VERSION "HNNBNNNYNNNNNNNNNNNNNNNNNNNNNNNNNNNNNNNNNN/4/%%%/4/'%**4NNN///"

NS_ :

BS_:

BU_: BAP_Tester BedienDisp_vo BedienSG_hi CGS DDA Gateway Gateway_PAG GurtMikrofon OTA_FC ZR_High ZR_LIMU ZR_MIB_TOP_ab_Gen3 ZR_Standard

BO_ 795 ESP_24: 8 Gateway
 SG_ ESP_24_CRC : 0|8@1+ (1,0) [0|255] ""  Vector__XXX
 SG_ ESP_24_BZ : 8|4@1+ (1,0) [0|15] ""  Vector__XXX
 SG_ ESP_Lampe : 12|1@1+ (1.0,0.0) [0.0|1] ""  OTA_FC,ZR_High,ZR_LIMU,ZR_MIB_TOP_ab_Gen3
 SG_ ABS_Lampe : 13|1@1+ (1.0,0.0) [0.0|1] ""  OTA_FC,ZR_High
 SG_ BK_Lampe_02 : 14|2@1+ (1.0,0.0) [0.0|3] ""  OTA_FC
 SG_ TC_Lampe : 16|1@1+ (1.0,0.0) [0.0|1] ""  Vector__XXX
 SG_ ESP_m_Raddrehz : 17|15@1+ (0.002,0) [0.000|65.278] "Unit_Hertz"  Vector__XXX
 SG_ ESP_Textanzeigen_03 : 32|5@1+ (1.0,0.0) [0.0|31] ""  OTA_FC
 SG_ ESP_Meldungen : 37|3@1+ (1.0,0.0) [0.0|7] ""  Vector__XXX
 SG_ ESP_Wegimp_VA : 40|11@1+ (1,0) [0|2047] ""  ZR_High,ZR_LIMU,ZR_MIB_TOP_ab_Gen3,ZR_Standard
 SG_ ESP_Fehlerstatus_Wegimp : 51|1@1+ (1.0,0.0) [0.0|1] ""  ZR_High,ZR_LIMU,ZR_MIB_TOP_ab_Gen3,ZR_Standard
 SG_ ESP_Wegimp_Ueberlauf : 52|1@1+ (1.0,0.0) [0.0|1] ""  ZR_High,ZR_LIMU,ZR_MIB_TOP_ab_Gen3,ZR_Standard
 SG_ ESP_QBit_Wegimp_VA : 53|1@1+ (1.0,0.0) [0.0|1] ""  ZR_High,ZR_LIMU,ZR_MIB_TOP_ab_Gen3,ZR_Standard
 SG_ ESP_HDC_Geschw_Farbe : 54|1@1+ (1.0,0.0) [0.0|1] ""  ZR_High,ZR_LIMU,ZR_MIB_TOP_ab_Gen3
 SG_ ESP_Off_Lampe : 55|1@1+ (1.0,0.0) [0.0|1] ""  OTA_FC,ZR_High
 SG_ ESP_HDC_Regelgeschw : 56|7@1+ (0.32,0) [0.32|39.68] "Unit_KiloMeterPerHour"  ZR_High,ZR_LIMU,ZR_MIB_TOP_ab_Gen3,ZR_Standard
 SG_ ESP_BKV_Warnung : 63|1@1+ (1.0,0.0) [0.0|1] ""  OTA_FC

BO_ 508 ESP_32: 8 Gateway
 SG_ ESP_32_CRC : 0|8@1+ (1,0) [0|255] ""  Vector__XXX
 SG_ ESP_32_BZ : 8|4@1+ (1,0) [0|15] ""  Vector__XXX
 SG_ ESP_Status_Bremsentemp_02 : 12|2@1+ (1.0,0.0) [0.0|3] ""  ZR_LIMU,ZR_MIB_TOP_ab_Gen3
 SG_ ESP_Aggregataktivitaet : 14|1@1+ (1.0,0.0) [0.0|1] ""  Vector__XXX
 SG_ ESP_Stillstandsflag : 15|1@1+ (1.0,0.0) [0.0|1] ""  Vector__XXX
 SG_ ESC_MBK_Meldungen : 16|2@1+ (1.0,0.0) [0.0|3] ""  Vector__XXX
 SG_ ESP_EDS_Anzeige : 32|3@1+ (1.0,0.0) [0.0|7] ""  ZR_High,ZR_LIMU,ZR_MIB_TOP_ab_Gen3
 SG_ RLE_Anzeigen : 35|3@1+ (1.0,0.0) [0.0|7] ""  Vector__XXX
 SG_ ESP_Wiederstart_Anz_Std : 38|1@1+ (1.0,0.0) [0.0|1] ""  Vector__XXX
 SG_ ESC_Anforderung_Airbrake : 39|1@1+ (1.0,0.0) [0.0|1] ""  Vector__XXX
 SG_ ESC_FBA_Meldungen : 40|2@1+ (1.0,0.0) [0.0|3] ""  Vector__XXX
 SG_ ESP_Rollover_Status_dyn : 42|2@1+ (1.0,0.0) [0.0|3] ""  Vector__XXX
 SG_ ESP_Rollover_Status_stat : 44|2@1+ (1.0,0.0) [0.0|3] ""  Vector__XXX
 SG_ ESP_AVH_LED : 46|3@1+ (1.0,0.0) [0.0|7] ""  Vector__XXX
 SG_ ESP_HDC_LED : 49|3@1+ (1.0,0.0) [0.0|7] ""  Vector__XXX
 SG_ ESP_Off_LED : 52|3@1+ (1.0,0.0) [0.0|7] ""  Vector__XXX
 SG_ ESP_Notbremsanzeige : 55|1@1+ (1.0,0.0) [0.0|1] ""  Vector__XXX
 SG_ ESC_Motorstartverzoegerung : 56|1@1+ (1.0,0.0) [0.0|1] ""  Vector__XXX
 SG_ ESP_Offroad_Lampe : 57|1@1+ (1.0,0.0) [0.0|1] ""  Vector__XXX
 SG_ ESP_HDC_Textanzeigen : 58|5@1+ (1.0,0.0) [0.0|31] ""  Vector__XXX
 SG_ ESP_HOLD_verf : 63|1@1+ (1.0,0.0) [0.0|1] ""  OTA_FC

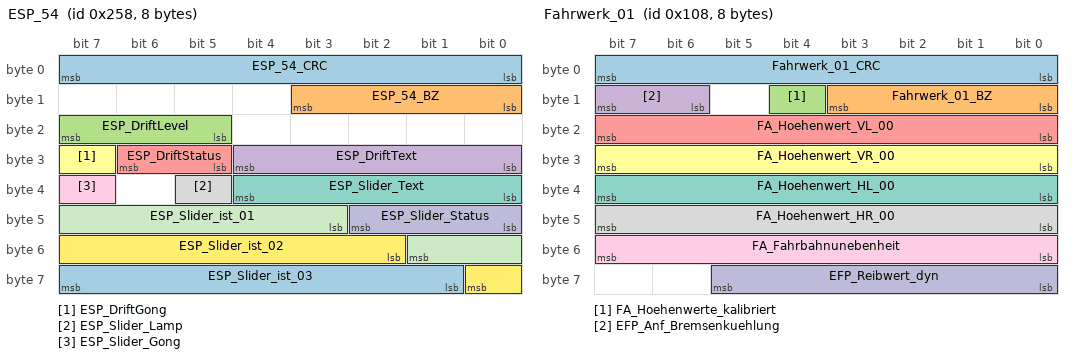
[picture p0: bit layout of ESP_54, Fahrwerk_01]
BO_ 600 ESP_54: 8 Gateway
 SG_ ESP_54_CRC : 0|8@1+ (1,0) [0|255] ""  ZR_LIMU
 SG_ ESP_54_BZ : 8|4@1+ (1,0) [0|15] ""  ZR_LIMU
 SG_ ESP_DriftLevel : 21|3@1+ (1.0,0.0) [0.0|7] ""  Vector__XXX
 SG_ ESP_DriftText : 24|5@1+ (1.0,0.0) [0.0|31] ""  Vector__XXX
 SG_ ESP_DriftStatus : 29|2@1+ (1.0,0.0) [0.0|3] ""  Vector__XXX
 SG_ ESP_DriftGong : 31|1@1+ (1.0,0.0) [0.0|1] ""  Vector__XXX
 SG_ ESP_Slider_Text : 32|5@1+ (1.0,0.0) [0.0|31] ""  ZR_LIMU
 SG_ ESP_Slider_Lamp : 37|1@1+ (1.0,0.0) [0.0|1] ""  Vector__XXX
 SG_ ESP_Slider_Gong : 39|1@1+ (1.0,0.0) [0.0|1] ""  Vector__XXX
 SG_ ESP_Slider_Status : 40|3@1+ (1.0,0.0) [0.0|7] ""  ZR_LIMU
 SG_ ESP_Slider_ist_01 : 43|7@1+ (1,0) [0|126] ""  ZR_LIMU
 SG_ ESP_Slider_ist_02 : 50|7@1+ (1,0) [0|126] ""  ZR_LIMU
 SG_ ESP_Slider_ist_03 : 57|7@1+ (1,0) [0|126] ""  ZR_LIMU

BO_ 264 Fahrwerk_01: 8 Gateway
 SG_ Fahrwerk_01_CRC : 0|8@1+ (1,0) [0|255] ""  Vector__XXX
 SG_ Fahrwerk_01_BZ : 8|4@1+ (1,0) [0|15] ""  Vector__XXX
 SG_ FA_Hoehenwerte_kalibriert : 12|1@1+ (1.0,0.0) [0.0|1] ""  ZR_High
 SG_ EFP_Anf_Bremsenkuehlung : 14|2@1+ (1.0,0.0) [0.0|3] ""  Vector__XXX
 SG_ FA_Hoehenwert_VL_00 : 16|8@1+ (1,-127) [-127|126] "Unit_MilliMeter"  DDA,OTA_FC,ZR_High,ZR_MIB_TOP_ab_Gen3
 SG_ FA_Hoehenwert_VR_00 : 24|8@1+ (1,-127) [-127|126] "Unit_MilliMeter"  DDA,OTA_FC,ZR_High,ZR_MIB_TOP_ab_Gen3
 SG_ FA_Hoehenwert_HL_00 : 32|8@1+ (1,-127) [-127|126] "Unit_MilliMeter"  DDA,OTA_FC,ZR_High,ZR_MIB_TOP_ab_Gen3
 SG_ FA_Hoehenwert_HR_00 : 40|8@1+ (1,-127) [-127|126] "Unit_MilliMeter"  DDA,OTA_FC,ZR_High,ZR_MIB_TOP_ab_Gen3
 SG_ FA_Fahrbahnunebenheit : 48|8@1+ (1,0) [0|253] ""  OTA_FC,ZR_High
 SG_ EFP_Reibwert_dyn : 56|6@1+ (0.03,0) [0.00|1.50] "Unit_None"  Vector__XXX

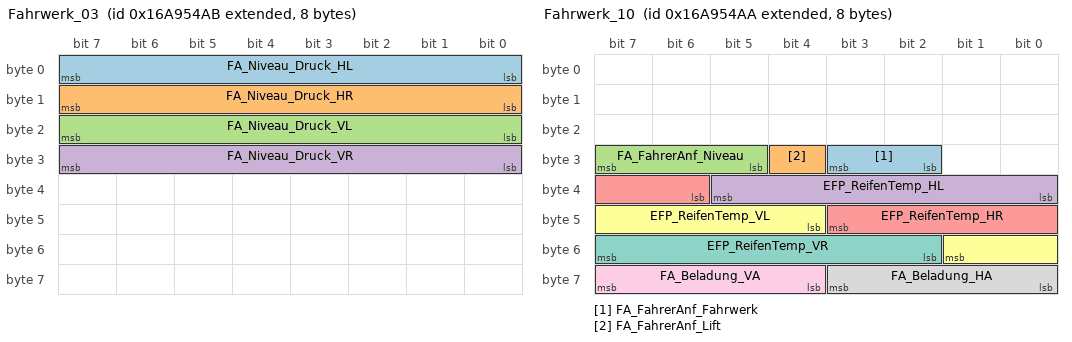
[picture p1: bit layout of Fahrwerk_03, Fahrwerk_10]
BO_ 2527679659 Fahrwerk_03: 8 Gateway
 SG_ FA_Niveau_Druck_HL : 0|8@1+ (0.1,0) [0.0|25.3] "Unit_Bar"  ZR_High
 SG_ FA_Niveau_Druck_HR : 8|8@1+ (0.1,0) [0.0|25.3] "Unit_Bar"  ZR_High
 SG_ FA_Niveau_Druck_VL : 16|8@1+ (0.1,0) [0.0|25.3] "Unit_Bar"  ZR_High
 SG_ FA_Niveau_Druck_VR : 24|8@1+ (0.1,0) [0.0|25.3] "Unit_Bar"  ZR_High

BO_ 429 Fahrwerk_06: 8 Gateway
 SG_ Fahrwerk_06_CRC : 0|8@1+ (1,0) [0|255] ""  Vector__XXX
 SG_ Fahrwerk_06_BZ : 8|4@1+ (1,0) [0|15] ""  Vector__XXX
 SG_ NR_Reglerstatus : 12|4@1+ (1.0,0.0) [0.0|15] ""  OTA_FC,ZR_High
 SG_ FA_Verstellung_in_Kuerze : 16|1@1+ (1.0,0.0) [0.0|1] ""  ZR_High
 SG_ FA_Verstellung_aktiv : 17|1@1+ (1.0,0.0) [0.0|1] ""  ZR_High
 SG_ FA_Kompressor_laeuft_in_Kuerze : 18|1@1+ (1.0,0.0) [0.0|1] ""  Vector__XXX
 SG_ FA_Kompressor_laeuft : 19|1@1+ (1.0,0.0) [0.0|1] ""  Vector__XXX
 SG_ NR_Anforderung_v_Begrenzung : 20|2@1+ (1.0,0.0) [0.0|3] ""  Vector__XXX
 SG_ NR_LED_SGN : 22|1@1+ (1.0,0.0) [0.0|1] ""  ZR_High
 SG_ NR_LED_TN : 23|1@1+ (1.0,0.0) [0.0|1] ""  ZR_High
 SG_ NR_LED_BN : 24|1@1+ (1.0,0.0) [0.0|1] ""  ZR_High
 SG_ FA_Absenkung_Fahrzeug : 25|1@1+ (1.0,0.0) [0.0|1] ""  OTA_FC,ZR_High
 SG_ FA_Anhaengerstatus_intern : 26|3@1+ (1.0,0.0) [0.0|7] ""  ZR_High
 SG_ FA_Anhebung_Fahrzeug : 29|1@1+ (1.0,0.0) [0.0|1] ""  OTA_FC,ZR_High
 SG_ FA_Druckspeicher_verfuegbar : 30|1@1+ (1.0,0.0) [0.0|1] ""  OTA_FC
 SG_ FA_HAL_Abschaltung : 31|1@1+ (1.0,0.0) [0.0|1] ""  Vector__XXX
 SG_ FA_ESP_Zuschaltung : 32|1@1+ (1.0,0.0) [0.0|1] ""  Vector__XXX
 SG_ NR_LED_HN : 33|1@1+ (1.0,0.0) [0.0|1] ""  ZR_High
 SG_ FA_Zwischenniveau : 34|1@1+ (1.0,0.0) [0.0|1] ""  OTA_FC
 SG_ FA_Systemstatus : 35|1@1+ (1.0,0.0) [0.0|1] ""  ZR_High
 SG_ EFP_Soll_FahrPr_HAL : 36|4@1+ (1.0,0.0) [0.0|15] ""  Vector__XXX
 SG_ NR_Kompressor_Strom_02 : 40|8@1+ (0.2,0) [0.0|50.8] "Unit_Amper"  Vector__XXX
 SG_ NR_Kompressor_Temp_Zylinderkopf : 48|8@1+ (1,-40) [-40|213] "Unit_DegreCelsi"  OTA_FC
 SG_ FA_Signal_Drucksensor : 56|8@1+ (0.1,0) [0.0|25.3] "Unit_Bar"  OTA_FC

BO_ 2527679658 Fahrwerk_10: 8 Gateway
 SG_ FA_FahrerAnf_Fahrwerk : 26|2@1+ (1.0,0.0) [0.0|3] ""  OTA_FC,ZR_MIB_TOP_ab_Gen3
 SG_ FA_FahrerAnf_Lift : 28|1@1+ (1.0,0.0) [0.0|1] ""  OTA_FC,ZR_MIB_TOP_ab_Gen3
 SG_ FA_FahrerAnf_Niveau : 29|3@1+ (1.0,0.0) [0.0|7] ""  OTA_FC,ZR_MIB_TOP_ab_Gen3
 SG_ EFP_ReifenTemp_HL : 32|6@1+ (2,-25) [-25|99] "Unit_DegreCelsi"  OTA_FC
 SG_ EFP_ReifenTemp_HR : 38|6@1+ (2,-25) [-25|99] "Unit_DegreCelsi"  OTA_FC
 SG_ EFP_ReifenTemp_VL : 44|6@1+ (2,-25) [-25|99] "Unit_DegreCelsi"  OTA_FC
 SG_ EFP_ReifenTemp_VR : 50|6@1+ (2,-25) [-25|99] "Unit_DegreCelsi"  OTA_FC
 SG_ FA_Beladung_HA : 56|4@1+ (50,0) [0|650] "Unit_KiloGram"  ZR_High
 SG_ FA_Beladung_VA : 60|4@1+ (50,0) [0|650] "Unit_KiloGram"  ZR_High

BO_ 2527679896 Fahrwerk_12: 8 Gateway_PAG
 SG_ Fahrwerk_12_CRC : 0|8@1+ (1,0) [0|255] ""  Vector__XXX
 SG_ Fahrwerk_12_BZ : 8|4@1+ (1,0) [0|15] ""  Vector__XXX
 SG_ EFP_ReifenTempOf_VL : 12|6@1+ (2,-25) [-25|99] "Unit_DegreCelsi"  Vector__XXX
 SG_ EFP_ReifenTempOf_VR : 18|6@1+ (2,-25) [-25|99] "Unit_DegreCelsi"  Vector__XXX
 SG_ EFP_ReifenTempOf_HL : 24|6@1+ (2,-25) [-25|99] "Unit_DegreCelsi"  Vector__XXX
 SG_ EFP_ReifenTempOf_HR : 30|6@1+ (2,-25) [-25|99] "Unit_DegreCelsi"  Vector__XXX
 SG_ FA_FahrerAnf_Lift_Abwurf : 39|1@1+ (1.0,0.0) [0.0|1] ""  ZR_MIB_TOP_ab_Gen3
 SG_ FA_Niveau_AOCCT_timer2_verbaut : 40|1@1+ (1.0,0.0) [0.0|1] ""  Vector__XXX
 SG_ FA_Niveau_AOCCT_timer2_count : 41|1@1+ (1.0,0.0) [0.0|1] ""  Vector__XXX
 SG_ FA_Niveau_AOCCT_timer1_verbaut : 42|1@1+ (1.0,0.0) [0.0|1] ""  Vector__XXX
 SG_ FA_Niveau_AOCCT_timer1_count : 43|1@1+ (1.0,0.0) [0.0|1] ""  Vector__XXX
 SG_ FA_Niveau_AOCCT_teststatus : 44|1@1+ (1.0,0.0) [0.0|1] ""  Vector__XXX
 SG_ FA_Niveau_AOCCT_fehlerstatus : 45|1@1+ (1.0,0.0) [0.0|1] ""  Vector__XXX
 SG_ FA_Zuladung_VA : 46|6@1+ (20,0) [0|1200] "Unit_KiloGram"  Vector__XXX
 SG_ FA_Zuladung_HA : 52|6@1+ (20,0) [0|1200] "Unit_KiloGram"  Vector__XXX
 SG_ FA_Zuladung_Status_VA : 58|3@1+ (1.0,0.0) [0.0|7] ""  Vector__XXX
 SG_ FA_Zuladung_Status_HA : 61|3@1+ (1.0,0.0) [0.0|7] ""  Vector__XXX

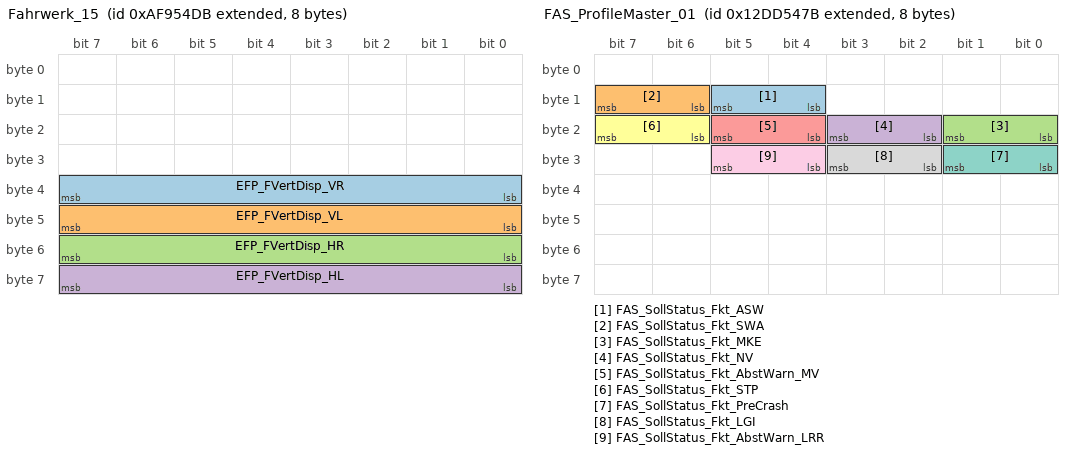
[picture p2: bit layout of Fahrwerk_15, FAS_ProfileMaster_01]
BO_ 2331595995 Fahrwerk_15: 8 Gateway
 SG_ EFP_FVertDisp_VR : 32|8@1+ (100,0) [0|24000] "Unit_Newto"  ZR_MIB_TOP_ab_Gen3
 SG_ EFP_FVertDisp_VL : 40|8@1+ (100,0) [0|24000] "Unit_Newto"  ZR_MIB_TOP_ab_Gen3
 SG_ EFP_FVertDisp_HR : 48|8@1+ (100,0) [0|24000] "Unit_Newto"  ZR_MIB_TOP_ab_Gen3
 SG_ EFP_FVertDisp_HL : 56|8@1+ (100,0) [0|24000] "Unit_Newto"  ZR_MIB_TOP_ab_Gen3

BO_ 705 Fahrwerk_Anzeige_01: 8 Gateway
 SG_ Fahrwerk_Anzeige_01_CRC : 0|8@1+ (1,0) [0|255] ""  Vector__XXX
 SG_ Fahrwerk_Anzeige_01_BZ : 8|4@1+ (1,0) [0|15] ""  Vector__XXX
 SG_ EFP_Verbau_DR : 12|1@1+ (1.0,0.0) [0.0|1] ""  Vector__XXX
 SG_ EFP_Verbau_eAllrad : 13|1@1+ (1.0,0.0) [0.0|1] ""  Vector__XXX
 SG_ EFP_Verbau_LF : 14|1@1+ (1.0,0.0) [0.0|1] ""  Vector__XXX
 SG_ LF_Texte : 15|2@1+ (1.0,0.0) [0.0|3] ""  Vector__XXX
 SG_ EFP_Verbau_eAWS : 17|1@1+ (1.0,0.0) [0.0|1] ""  Vector__XXX
 SG_ eAWS_Warnmeldung_Prio1 : 18|1@1+ (1.0,0.0) [0.0|1] ""  Vector__XXX
 SG_ eAWS_Warnmeldung_Prio2 : 19|1@1+ (1.0,0.0) [0.0|1] ""  Vector__XXX
 SG_ LF_Texte_2 : 20|4@1+ (1.0,0.0) [0.0|15] ""  Vector__XXX
 SG_ EFP_Status_Taster_Lift : 24|2@1+ (1.0,0.0) [0.0|3] ""  Vector__XXX
 SG_ EFP_Status_Taster_Fahrwerk : 26|2@1+ (1.0,0.0) [0.0|3] ""  BedienDisp_vo
 SG_ FDR_Warnung_ALR : 28|2@1+ (1.0,0.0) [0.0|3] ""  Vector__XXX
 SG_ FDR_Warnung_TV : 30|2@1+ (1.0,0.0) [0.0|3] ""  Vector__XXX
 SG_ EFP_Verbau_eABC : 32|1@1+ (1.0,0.0) [0.0|1] ""  Vector__XXX
 SG_ LF_Warnung_Prio1_02 : 33|3@1+ (1.0,0.0) [0.0|7] ""  Vector__XXX
 SG_ LF_Warnung_Prio1 : 36|2@1+ (1.0,0.0) [0.0|3] ""  Vector__XXX
 SG_ LF_Warnung_Prio2 : 38|2@1+ (1.0,0.0) [0.0|3] ""  Vector__XXX
 SG_ eABC_Warnung_Prio2 : 40|2@1+ (1.0,0.0) [0.0|3] ""  Vector__XXX
 SG_ eABC_Warnung_Prio1 : 42|3@1+ (1.0,0.0) [0.0|7] ""  Vector__XXX
 SG_ eABC_Texte : 45|3@1+ (1.0,0.0) [0.0|7] ""  Vector__XXX
 SG_ DR_Warnung : 48|2@1+ (1.0,0.0) [0.0|3] ""  Vector__XXX
 SG_ NR_LED_Offroadlevel : 50|2@1+ (1.0,0.0) [0.0|3] ""  Vector__XXX
 SG_ NR_LED_Ladelevel : 52|2@1+ (1.0,0.0) [0.0|3] ""  Vector__XXX
 SG_ NR_LED_Sync : 54|2@1+ (1.0,0.0) [0.0|3] ""  Vector__XXX
 SG_ NR_LED_XtraLevel : 56|2@1+ (1.0,0.0) [0.0|3] ""  Vector__XXX
 SG_ NR_LED_Strassenlevel : 58|2@1+ (1.0,0.0) [0.0|3] ""  Vector__XXX
 SG_ EFP_Warnung_Naesse : 60|3@1+ (1.0,0.0) [0.0|7] ""  Vector__XXX
 SG_ EFP_Warnung_Naesse_verf : 63|1@1+ (1.0,0.0) [0.0|1] ""  Vector__XXX

BO_ 2463978619 FAS_ProfileMaster_01: 8 Gateway
 SG_ FAS_SollStatus_Fkt_ASW : 12|2@1+ (1.0,0.0) [0.0|3] ""  ZR_High
 SG_ FAS_SollStatus_Fkt_SWA : 14|2@1+ (1.0,0.0) [0.0|3] ""  ZR_High
 SG_ FAS_SollStatus_Fkt_MKE : 16|2@1+ (1.0,0.0) [0.0|3] ""  ZR_High
 SG_ FAS_SollStatus_Fkt_NV : 18|2@1+ (1.0,0.0) [0.0|3] ""  ZR_High
 SG_ FAS_SollStatus_Fkt_AbstWarn_MV : 20|2@1+ (1.0,0.0) [0.0|3] ""  ZR_High
 SG_ FAS_SollStatus_Fkt_STP : 22|2@1+ (1.0,0.0) [0.0|3] ""  ZR_High
 SG_ FAS_SollStatus_Fkt_PreCrash : 24|2@1+ (1.0,0.0) [0.0|3] ""  ZR_High
 SG_ FAS_SollStatus_Fkt_LGI : 26|2@1+ (1.0,0.0) [0.0|3] ""  ZR_High
 SG_ FAS_SollStatus_Fkt_AbstWarn_LRR : 28|2@1+ (1.0,0.0) [0.0|3] ""  Vector__XXX

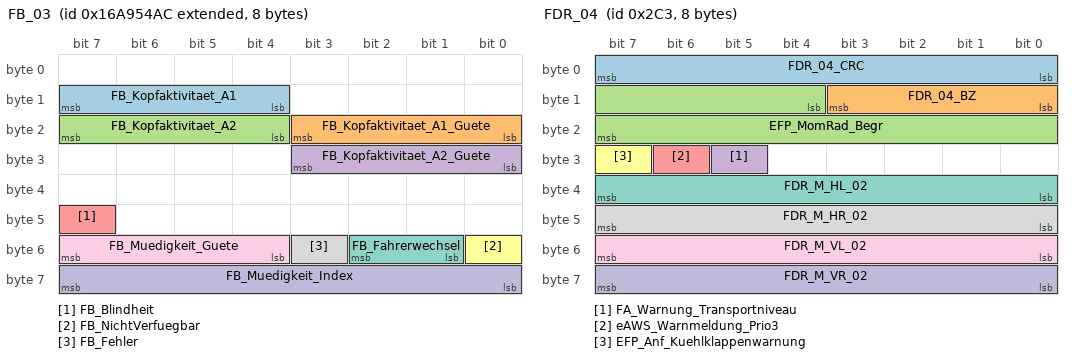
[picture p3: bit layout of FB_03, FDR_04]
BO_ 2527679660 FB_03: 8 Gateway
 SG_ FB_Kopfaktivitaet_A1 : 12|4@1+ (7.143,0) [0.000|100.002] "Unit_None"  Vector__XXX
 SG_ FB_Kopfaktivitaet_A1_Guete : 16|4@1+ (6.667,0) [0.000|100.005] "Unit_PerCent"  Vector__XXX
 SG_ FB_Kopfaktivitaet_A2 : 20|4@1+ (7.143,0) [0.000|100.002] "Unit_None"  Vector__XXX
 SG_ FB_Kopfaktivitaet_A2_Guete : 24|4@1+ (6.667,0) [0.000|100.005] "Unit_PerCent"  Vector__XXX
 SG_ FB_Blindheit : 47|1@1+ (1.0,0.0) [0.0|1] ""  Vector__XXX
 SG_ FB_NichtVerfuegbar : 48|1@1+ (1.0,0.0) [0.0|1] ""  Vector__XXX
 SG_ FB_Fahrerwechsel : 49|2@1+ (1.0,0.0) [0.0|3] ""  ZR_High
 SG_ FB_Fehler : 51|1@1+ (1.0,0.0) [0.0|1] ""  ZR_High
 SG_ FB_Muedigkeit_Guete : 52|4@1+ (6.667,0) [0.000|100.005] "Unit_PerCent"  ZR_High
 SG_ FB_Muedigkeit_Index : 56|8@1+ (0.05,0) [0.00|9.00] "Unit_None"  ZR_High

BO_ 707 FDR_04: 8 Gateway
 SG_ FDR_04_CRC : 0|8@1+ (1,0) [0|255] ""  Vector__XXX
 SG_ FDR_04_BZ : 8|4@1+ (1,0) [0|15] ""  Vector__XXX
 SG_ EFP_MomRad_Begr : 12|12@1+ (3,0) [0|12279] "Unit_NewtoMeter"  Vector__XXX
 SG_ FA_Warnung_Transportniveau : 29|1@1+ (1.0,0.0) [0.0|1] ""  Vector__XXX
 SG_ eAWS_Warnmeldung_Prio3 : 30|1@1+ (1.0,0.0) [0.0|1] ""  Vector__XXX
 SG_ EFP_Anf_Kuehlklappenwarnung : 31|1@1+ (1.0,0.0) [0.0|1] ""  Vector__XXX
 SG_ FDR_M_HL_02 : 32|8@1+ (1,-100) [-100|100] "Unit_PerCent"  ZR_High,ZR_LIMU,ZR_MIB_TOP_ab_Gen3,ZR_Standard
 SG_ FDR_M_HR_02 : 40|8@1+ (1,-100) [-100|100] "Unit_PerCent"  ZR_High,ZR_LIMU,ZR_MIB_TOP_ab_Gen3,ZR_Standard
 SG_ FDR_M_VL_02 : 48|8@1+ (1,-100) [-100|100] "Unit_PerCent"  ZR_High,ZR_LIMU,ZR_MIB_TOP_ab_Gen3,ZR_Standard
 SG_ FDR_M_VR_02 : 56|8@1+ (1,-100) [-100|100] "Unit_PerCent"  ZR_High,ZR_LIMU,ZR_MIB_TOP_ab_Gen3,ZR_Standard

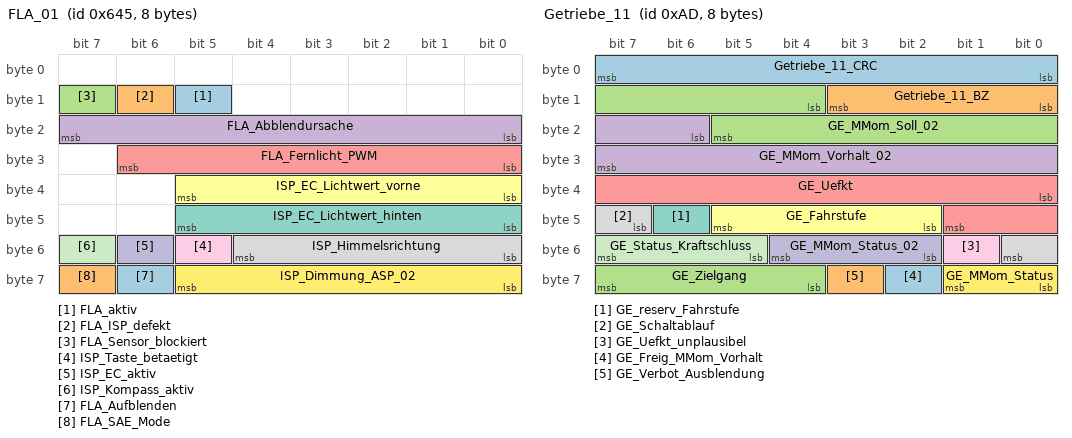
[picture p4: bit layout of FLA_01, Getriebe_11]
BO_ 1605 FLA_01: 8 Gateway
 SG_ FLA_aktiv : 13|1@1+ (1.0,0.0) [0.0|1] ""  Vector__XXX
 SG_ FLA_ISP_defekt : 14|1@1+ (1.0,0.0) [0.0|1] ""  ZR_High
 SG_ FLA_Sensor_blockiert : 15|1@1+ (1.0,0.0) [0.0|1] ""  ZR_High
 SG_ FLA_Abblendursache : 16|8@1+ (1.0,0.0) [0.0|255] ""  ZR_High
 SG_ FLA_Fernlicht_PWM : 24|7@1+ (1,0) [0|100] "Unit_PerCent"  Vector__XXX
 SG_ ISP_EC_Lichtwert_vorne : 32|6@1+ (1,0) [0|61] "Unit_None"  Vector__XXX
 SG_ ISP_EC_Lichtwert_hinten : 40|6@1+ (1,0) [0|61] "Unit_None"  Vector__XXX
 SG_ ISP_Himmelsrichtung : 48|5@1+ (12,0) [0|348] "Unit_DegreOfArc"  Vector__XXX
 SG_ ISP_Taste_betaetigt : 53|1@1+ (1.0,0.0) [0.0|1] ""  Vector__XXX
 SG_ ISP_EC_aktiv : 54|1@1+ (1.0,0.0) [0.0|1] ""  Vector__XXX
 SG_ ISP_Kompass_aktiv : 55|1@1+ (1.0,0.0) [0.0|1] ""  Vector__XXX
 SG_ ISP_Dimmung_ASP_02 : 56|6@1+ (0.0226,0) [0.0000|1.4012] "Unit_Volt"  Vector__XXX
 SG_ FLA_Aufblenden : 62|1@1+ (1.0,0.0) [0.0|1] ""  Vector__XXX
 SG_ FLA_SAE_Mode : 63|1@1+ (1.0,0.0) [0.0|1] ""  Vector__XXX

BO_ 2589283684 FoD_01: 8 Gateway
 SG_ FoD_Transmission_Info : 60|2@1+ (1.0,0.0) [0.0|3] ""  ZR_High,ZR_LIMU,ZR_MIB_TOP_ab_Gen3
 SG_ FoD_Anz_Funktionsabschaltung : 62|2@1+ (1.0,0.0) [0.0|3] ""  Vector__XXX

BO_ 2549875571 FoD_ZR_Req: 8 Gateway
 SG_ FoD_ZR_Req_Data : 0|64@1+ (1.0,0.0) [0.0|18446744073709551615] ""  ZR_High,ZR_LIMU,ZR_MIB_TOP_ab_Gen3

BO_ 2550006643 FoD_ZR_Resp: 8 ZR_High
 SG_ FoD_ZR_Resp_Data : 0|64@1+ (1.0,0.0) [0.0|18446744073709551615] ""  Gateway,Gateway_PAG

BO_ 173 Getriebe_11: 8 Gateway
 SG_ Getriebe_11_CRC : 0|8@1+ (1,0) [0|255] ""  Vector__XXX
 SG_ Getriebe_11_BZ : 8|4@1+ (1,0) [0|15] ""  Vector__XXX
 SG_ GE_MMom_Soll_02 : 12|10@1+ (1,-509) [-509|509] ""  Vector__XXX
 SG_ GE_MMom_Vorhalt_02 : 22|10@1+ (1,-509) [-509|509] ""  Vector__XXX
 SG_ GE_Uefkt : 32|10@1+ (0.1,0) [0.0|102.2] ""  Vector__XXX
 SG_ GE_Fahrstufe : 42|4@1+ (1.0,0.0) [0.0|15] ""  DDA,OTA_FC,ZR_High,ZR_LIMU,ZR_MIB_TOP_ab_Gen3
 SG_ GE_reserv_Fahrstufe : 46|1@1+ (1,0) [0|1] ""  Vector__XXX
 SG_ GE_Schaltablauf : 47|2@1+ (1.0,0.0) [0.0|3] ""  Vector__XXX
 SG_ GE_Uefkt_unplausibel : 49|1@1+ (1.0,0.0) [0.0|1] ""  Vector__XXX
 SG_ GE_MMom_Status_02 : 50|3@1+ (1.0,0.0) [0.0|7] ""  Vector__XXX
 SG_ GE_Status_Kraftschluss : 53|3@1+ (1.0,0.0) [0.0|7] ""  Vector__XXX
 SG_ GE_MMom_Status : 56|2@1+ (1.0,0.0) [0.0|3] ""  Vector__XXX
 SG_ GE_Freig_MMom_Vorhalt : 58|1@1+ (1.0,0.0) [0.0|1] ""  Vector__XXX
 SG_ GE_Verbot_Ausblendung : 59|1@1+ (1.0,0.0) [0.0|1] ""  Vector__XXX
 SG_ GE_Zielgang : 60|4@1+ (1.0,0.0) [0.0|15] ""  OTA_FC,ZR_High

BO_ 968 Getriebe_14: 8 Gateway
 SG_ GE_OBD_AbsperrVent : 12|4@1+ (1.0,0.0) [0.0|15] ""  Vector__XXX
 SG_ GE_amax_moeglich : 16|9@1+ (0.024,-2.016) [-2.016|10.224] "Unit_MeterPerSeconSquar"  Vector__XXX
 SG_ GE_Charisma_FahrPr : 25|4@1+ (1.0,0.0) [0.0|15] ""  Vector__XXX
 SG_ GE_Charisma_Status : 29|2@1+ (1.0,0.0) [0.0|3] ""  Vector__XXX
 SG_ GE_Freigabe_Verfallsinfo_WFS : 31|1@1+ (1.0,0.0) [0.0|1] ""  Vector__XXX
 SG_ GE_LaunchControl_LB : 32|4@1+ (1.0,0.0) [0.0|15] ""  Vector__XXX
 SG_ GE_Status_PaddleNeutral : 37|2@1+ (1.0,0.0) [0.0|3] ""  Vector__XXX
 SG_ GE_Remotestart_Betrieb : 39|1@1+ (1.0,0.0) [0.0|1] ""  Vector__XXX
 SG_ Freilauf_Charisma_FahrPr : 40|4@1+ (1.0,0.0) [0.0|15] ""  Vector__XXX
 SG_ Freilauf_Charisma_Status : 44|2@1+ (1.0,0.0) [0.0|3] ""  Vector__XXX
 SG_ GE_Freigabe_Info_WFS : 46|1@1+ (1.0,0.0) [0.0|1] ""  Vector__XXX
 SG_ GE_Sperr_Info_WFS : 47|1@1+ (1.0,0.0) [0.0|1] ""  Vector__XXX
 SG_ GE_Zustand_Kuppltemp : 48|2@1+ (1.0,0.0) [0.0|3] ""  Vector__XXX
 SG_ GE_Codierung_MSG : 50|1@1+ (1.0,0.0) [0.0|1] ""  Vector__XXX
 SG_ GE_LaunchControl : 51|1@1+ (1.0,0.0) [0.0|1] ""  OTA_FC
 SG_ GE_Heizwunsch : 52|2@1+ (1.0,0.0) [0.0|3] ""  Vector__XXX
 SG_ GE_OBD_Status : 54|1@1+ (1.0,0.0) [0.0|1] ""  Vector__XXX
 SG_ GE_LFR_Adaption : 55|1@1+ (1.0,0.0) [0.0|1] ""  Vector__XXX
 SG_ GE_Sumpftemperatur : 56|8@1+ (1,-58) [-58|196] "Unit_DegreCelsi"  OTA_FC,ZR_High,ZR_MIB_TOP_ab_Gen3,ZR_Standard

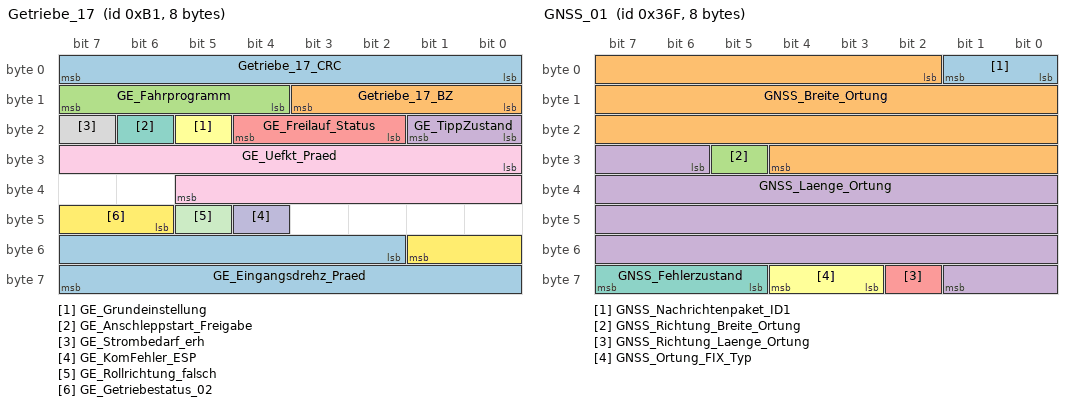
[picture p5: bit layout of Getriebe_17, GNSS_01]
BO_ 177 Getriebe_17: 8 Gateway
 SG_ Getriebe_17_CRC : 0|8@1+ (1,0) [0|255] ""  Vector__XXX
 SG_ Getriebe_17_BZ : 8|4@1+ (1,0) [0|15] ""  Vector__XXX
 SG_ GE_Fahrprogramm : 12|4@1+ (1.0,0.0) [0.0|15] ""  OTA_FC,ZR_High
 SG_ GE_TippZustand : 16|2@1+ (1.0,0.0) [0.0|3] ""  ZR_High
 SG_ GE_Freilauf_Status : 18|3@1+ (1.0,0.0) [0.0|7] ""  Vector__XXX
 SG_ GE_Grundeinstellung : 21|1@1+ (1.0,0.0) [0.0|1] ""  Vector__XXX
 SG_ GE_Anschleppstart_Freigabe : 22|1@1+ (1.0,0.0) [0.0|1] ""  Vector__XXX
 SG_ GE_Strombedarf_erh : 23|1@1+ (1.0,0.0) [0.0|1] ""  Vector__XXX
 SG_ GE_Uefkt_Praed : 24|14@1+ (0.008,0) [0.000|131.056] ""  Vector__XXX
 SG_ GE_KomFehler_ESP : 44|1@1+ (1.0,0.0) [0.0|1] ""  Vector__XXX
 SG_ GE_Rollrichtung_falsch : 45|1@1+ (1.0,0.0) [0.0|1] ""  Vector__XXX
 SG_ GE_Getriebestatus_02 : 46|4@1+ (1.0,0.0) [0.0|15] ""  OTA_FC
 SG_ GE_Eingangsdrehz_Praed : 50|14@1+ (1,0) [0|16381] "Unit_MinutInver"  Vector__XXX

BO_ 879 GNSS_01: 8 Gateway
 SG_ GNSS_Nachrichtenpaket_ID1 : 0|2@1+ (1,0) [0|3] "Unit_Bit"  ZR_High,ZR_LIMU,ZR_MIB_TOP_ab_Gen3,ZR_Standard
 SG_ GNSS_Breite_Ortung : 2|27@1+ (0.000001,0) [0.000000|90.000000] "Unit_DegreOfArc"  ZR_High,ZR_LIMU,ZR_MIB_TOP_ab_Gen3,ZR_Standard
 SG_ GNSS_Richtung_Breite_Ortung : 29|1@1+ (1.0,0.0) [0.0|1] ""  ZR_High,ZR_LIMU,ZR_MIB_TOP_ab_Gen3,ZR_Standard
 SG_ GNSS_Laenge_Ortung : 30|28@1+ (0.000001,0) [0.000000|180.000000] "Unit_DegreOfArc"  ZR_High,ZR_LIMU,ZR_MIB_TOP_ab_Gen3,ZR_Standard
 SG_ GNSS_Richtung_Laenge_Ortung : 58|1@1+ (1.0,0.0) [0.0|1] ""  ZR_High,ZR_LIMU,ZR_MIB_TOP_ab_Gen3,ZR_Standard
 SG_ GNSS_Ortung_FIX_Typ : 59|2@1+ (1.0,0.0) [0.0|3] ""  ZR_High,ZR_LIMU,ZR_MIB_TOP_ab_Gen3,ZR_Standard
 SG_ GNSS_Fehlerzustand : 61|3@1+ (1.0,0.0) [0.0|7] ""  ZR_High,ZR_LIMU,ZR_MIB_TOP_ab_Gen3,ZR_Standard

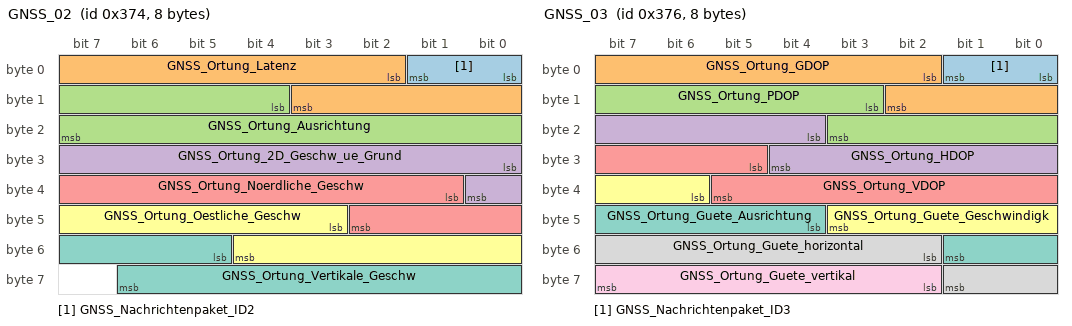
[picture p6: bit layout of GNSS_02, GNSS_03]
BO_ 884 GNSS_02: 8 Gateway
 SG_ GNSS_Nachrichtenpaket_ID2 : 0|2@1+ (1,0) [0|3] "Unit_Bit"  ZR_High,ZR_LIMU,ZR_MIB_TOP_ab_Gen3,ZR_Standard
 SG_ GNSS_Ortung_Latenz : 2|10@1+ (1,0) [0|1021] "Unit_MilliSecon"  ZR_High,ZR_LIMU,ZR_MIB_TOP_ab_Gen3,ZR_Standard
 SG_ GNSS_Ortung_Ausrichtung : 12|12@1+ (0.1,0) [0.0|359.9] "Unit_DegreOfArc"  ZR_High,ZR_LIMU,ZR_MIB_TOP_ab_Gen3,ZR_Standard
 SG_ GNSS_Ortung_2D_Geschw_ue_Grund : 24|9@1+ (0.25,0) [0.00|125.00] "Unit_MeterPerSecon"  ZR_High,ZR_LIMU,ZR_MIB_TOP_ab_Gen3,ZR_Standard
 SG_ GNSS_Ortung_Noerdliche_Geschw : 33|10@1+ (0.25,-125) [-125.00|125.00] "Unit_MeterPerSecon"  ZR_High,ZR_LIMU,ZR_MIB_TOP_ab_Gen3,ZR_Standard
 SG_ GNSS_Ortung_Oestliche_Geschw : 43|10@1+ (0.25,-125) [-125.00|125.00] "Unit_MeterPerSecon"  ZR_High,ZR_LIMU,ZR_MIB_TOP_ab_Gen3,ZR_Standard
 SG_ GNSS_Ortung_Vertikale_Geschw : 53|10@1+ (0.25,-125) [-125.00|125.00] "Unit_MeterPerSecon"  ZR_High,ZR_LIMU,ZR_MIB_TOP_ab_Gen3,ZR_Standard

BO_ 886 GNSS_03: 8 Gateway
 SG_ GNSS_Nachrichtenpaket_ID3 : 0|2@1+ (1,0) [0|3] "Unit_Bit"  ZR_High,ZR_LIMU,ZR_MIB_TOP_ab_Gen3,ZR_Standard
 SG_ GNSS_Ortung_GDOP : 2|9@1+ (0.1,0) [0.0|50.0] "Unit_None"  ZR_High,ZR_LIMU,ZR_MIB_TOP_ab_Gen3,ZR_Standard
 SG_ GNSS_Ortung_PDOP : 11|9@1+ (0.1,0) [0.0|50.0] "Unit_None"  ZR_High,ZR_LIMU,ZR_MIB_TOP_ab_Gen3,ZR_Standard
 SG_ GNSS_Ortung_HDOP : 20|9@1+ (0.1,0) [0.0|50.0] "Unit_None"  ZR_High,ZR_LIMU,ZR_MIB_TOP_ab_Gen3,ZR_Standard
 SG_ GNSS_Ortung_VDOP : 29|9@1+ (0.1,0) [0.0|50.0] "Unit_None"  ZR_High,ZR_LIMU,ZR_MIB_TOP_ab_Gen3,ZR_Standard
 SG_ GNSS_Ortung_Guete_Geschwindigk : 38|6@1+ (0.05,0) [0.00|3.05] "Unit_MeterPerSecon"  ZR_High,ZR_LIMU,ZR_MIB_TOP_ab_Gen3,ZR_Standard
 SG_ GNSS_Ortung_Guete_Ausrichtung : 44|6@1+ (0.15,0) [0.00|9.15] "Unit_DegreOfArc"  ZR_High,ZR_LIMU,ZR_MIB_TOP_ab_Gen3,ZR_Standard
 SG_ GNSS_Ortung_Guete_horizontal : 50|8@1+ (1,0) [0|250] "Unit_Meter"  ZR_High,ZR_LIMU,ZR_MIB_TOP_ab_Gen3,ZR_Standard
 SG_ GNSS_Ortung_Guete_vertikal : 58|6@1+ (2,0) [0|122] "Unit_Meter"  ZR_High,ZR_LIMU,ZR_MIB_TOP_ab_Gen3,ZR_Standard

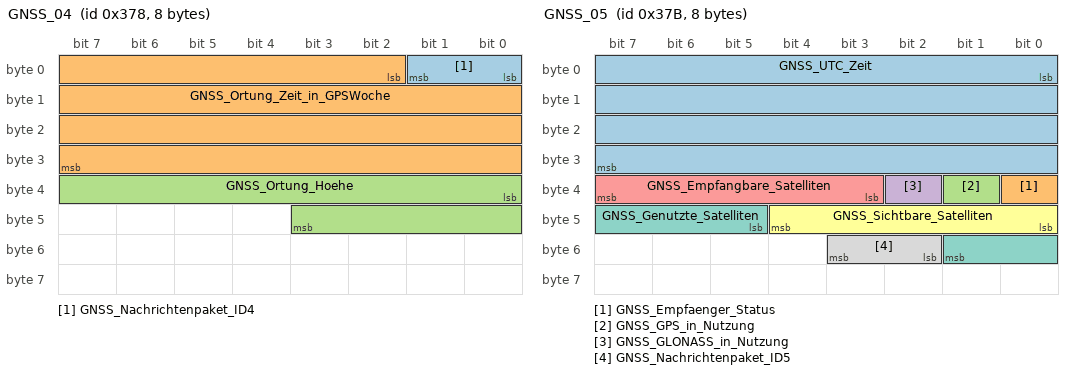
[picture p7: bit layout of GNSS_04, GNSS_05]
BO_ 888 GNSS_04: 8 Gateway
 SG_ GNSS_Nachrichtenpaket_ID4 : 0|2@1+ (1,0) [0|3] "Unit_Bit"  ZR_High,ZR_LIMU,ZR_MIB_TOP_ab_Gen3,ZR_Standard
 SG_ GNSS_Ortung_Zeit_in_GPSWoche : 2|30@1+ (1,0) [0|604800001] "Unit_MilliSecon"  ZR_High,ZR_LIMU,ZR_MIB_TOP_ab_Gen3,ZR_Standard
 SG_ GNSS_Ortung_Hoehe : 32|12@1+ (2,-500) [-500|7686] "Unit_Meter"  ZR_High,ZR_LIMU,ZR_MIB_TOP_ab_Gen3,ZR_Standard

BO_ 891 GNSS_05: 8 Gateway
 SG_ GNSS_UTC_Zeit : 0|32@1+ (1,0) [1|4294967295] "Unit_Secon"  OTA_FC,ZR_High,ZR_LIMU,ZR_MIB_TOP_ab_Gen3,ZR_Standard
 SG_ GNSS_Empfaenger_Status : 32|1@1+ (1.0,0.0) [0.0|1] ""  OTA_FC,ZR_High,ZR_LIMU,ZR_MIB_TOP_ab_Gen3,ZR_Standard
 SG_ GNSS_GPS_in_Nutzung : 33|1@1+ (1.0,0.0) [0.0|1] ""  ZR_High,ZR_LIMU,ZR_MIB_TOP_ab_Gen3,ZR_Standard
 SG_ GNSS_GLONASS_in_Nutzung : 34|1@1+ (1.0,0.0) [0.0|1] ""  ZR_High,ZR_LIMU,ZR_MIB_TOP_ab_Gen3,ZR_Standard
 SG_ GNSS_Empfangbare_Satelliten : 35|5@1+ (1,0) [1|30] "Unit_None"  ZR_High,ZR_LIMU,ZR_MIB_TOP_ab_Gen3,ZR_Standard
 SG_ GNSS_Sichtbare_Satelliten : 40|5@1+ (1,0) [1|30] "Unit_None"  ZR_High,ZR_LIMU,ZR_MIB_TOP_ab_Gen3,ZR_Standard
 SG_ GNSS_Genutzte_Satelliten : 45|5@1+ (1,0) [1|30] "Unit_None"  ZR_High,ZR_LIMU,ZR_MIB_TOP_ab_Gen3,ZR_Standard
 SG_ GNSS_Nachrichtenpaket_ID5 : 50|2@1+ (1,0) [0|3] "Unit_Bit"  ZR_High,ZR_LIMU,ZR_MIB_TOP_ab_Gen3,ZR_Standard

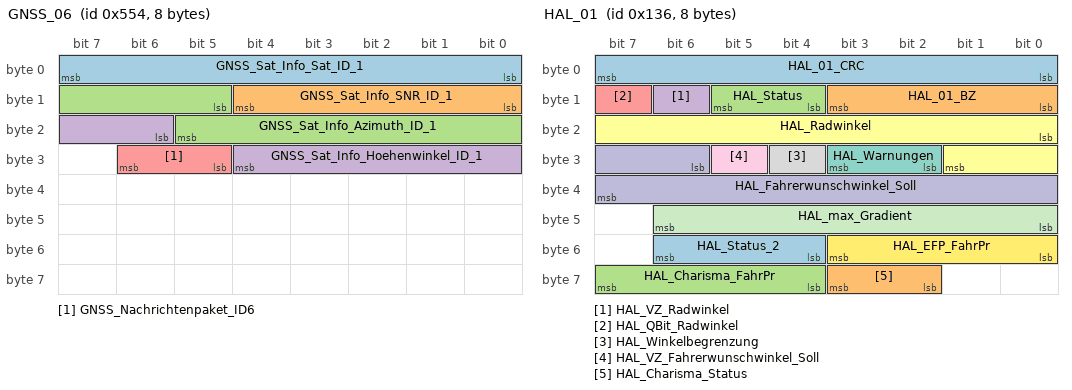
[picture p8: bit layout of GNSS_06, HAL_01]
BO_ 1364 GNSS_06: 8 Gateway
 SG_ GNSS_Sat_Info_Sat_ID_1 : 0|8@1+ (1,0) [0|255] ""  ZR_High,ZR_LIMU,ZR_MIB_TOP_ab_Gen3,ZR_Standard
 SG_ GNSS_Sat_Info_SNR_ID_1 : 8|5@1+ (2,0) [0|60] "Unit_DeziBel"  ZR_High,ZR_LIMU,ZR_MIB_TOP_ab_Gen3,ZR_Standard
 SG_ GNSS_Sat_Info_Azimuth_ID_1 : 13|9@1+ (1,0) [0|359] "Unit_DegreOfArc"  ZR_High,ZR_LIMU,ZR_MIB_TOP_ab_Gen3,ZR_Standard
 SG_ GNSS_Sat_Info_Hoehenwinkel_ID_1 : 22|7@1+ (1,0) [0|90] "Unit_DegreOfArc"  ZR_High,ZR_LIMU,ZR_MIB_TOP_ab_Gen3,ZR_Standard
 SG_ GNSS_Nachrichtenpaket_ID6 : 29|2@1+ (1,0) [0|3] "Unit_Bit"  ZR_High,ZR_LIMU,ZR_MIB_TOP_ab_Gen3,ZR_Standard

BO_ 299 GRA_ACC_01: 8 Gateway
 SG_ GRA_ACC_01_CRC : 0|8@1+ (1,0) [0|255] ""  Vector__XXX
 SG_ GRA_ACC_01_BZ : 8|4@1+ (1,0) [0|15] ""  Vector__XXX
 SG_ GRA_Hauptschalter : 12|1@1+ (1.0,0.0) [0.0|1] ""  ZR_High
 SG_ GRA_Abbrechen : 13|1@1+ (1.0,0.0) [0.0|1] ""  ZR_High
 SG_ GRA_Typ_Hauptschalter : 14|1@1+ (1.0,0.0) [0.0|1] ""  ZR_High
 SG_ GRA_Limiter : 15|1@1+ (1.0,0.0) [0.0|1] ""  ZR_High
 SG_ GRA_Tip_Setzen : 16|1@1+ (1.0,0.0) [0.0|1] ""  ZR_High
 SG_ GRA_Tip_Hoch : 17|1@1+ (1.0,0.0) [0.0|1] ""  ZR_High
 SG_ GRA_Tip_Runter : 18|1@1+ (1.0,0.0) [0.0|1] ""  ZR_High
 SG_ GRA_Tip_Wiederaufnahme : 19|1@1+ (1.0,0.0) [0.0|1] ""  ZR_High
 SG_ GRA_Verstellung_Zeitluecke : 20|2@1+ (1.0,0.0) [0.0|3] ""  ZR_High
 SG_ GRA_Codierung : 22|2@1+ (1.0,0.0) [0.0|3] ""  ZR_High
 SG_ GRA_Fehler : 24|1@1+ (1.0,0.0) [0.0|1] ""  ZR_High
 SG_ GRA_LIM_Taste_verfuegbar : 25|1@1+ (1.0,0.0) [0.0|1] ""  ZR_High
 SG_ GRA_Tip_Stufe_2 : 26|1@1+ (1.0,0.0) [0.0|1] ""  ZR_High
 SG_ GRA_Typ_Bedienteil : 27|3@1+ (1.0,0.0) [0.0|7] ""  ZR_High
 SG_ GRA_TravelAssist : 30|1@1+ (1.0,0.0) [0.0|1] ""  Vector__XXX
 SG_ GRA_reserveByte4 : 31|1@1+ (1.0,0.0) [0.0|1] ""  Vector__XXX
 SG_ GRA_reserveByte5 : 32|8@1+ (1.0,0.0) [0.0|255] ""  Vector__XXX
 SG_ GRA_reserveByte6 : 40|8@1+ (1.0,0.0) [0.0|255] ""  Vector__XXX
 SG_ GRA_reserveByte7 : 48|8@1+ (1.0,0.0) [0.0|255] ""  Vector__XXX
 SG_ GRA_reserveByte8 : 56|8@1+ (1.0,0.0) [0.0|255] ""  Vector__XXX

BO_ 310 HAL_01: 8 Gateway
 SG_ HAL_01_CRC : 0|8@1+ (1,0) [0|255] ""  Vector__XXX
 SG_ HAL_01_BZ : 8|4@1+ (1,0) [0|15] ""  Vector__XXX
 SG_ HAL_Status : 12|2@1+ (1.0,0.0) [0.0|3] ""  Vector__XXX
 SG_ HAL_VZ_Radwinkel : 14|1@1+ (1.0,0.0) [0.0|1] ""  ZR_LIMU
 SG_ HAL_QBit_Radwinkel : 15|1@1+ (1.0,0.0) [0.0|1] ""  Vector__XXX
 SG_ HAL_Radwinkel : 16|10@1+ (0.01,0) [0.00|10.19] "Unit_DegreOfArc"  ZR_LIMU,ZR_MIB_TOP_ab_Gen3
 SG_ HAL_Warnungen : 26|2@1+ (1.0,0.0) [0.0|3] ""  Vector__XXX
 SG_ HAL_Winkelbegrenzung : 28|1@1+ (1.0,0.0) [0.0|1] ""  Vector__XXX
 SG_ HAL_VZ_Fahrerwunschwinkel_Soll : 29|1@1+ (1.0,0.0) [0.0|1] ""  Vector__XXX
 SG_ HAL_Fahrerwunschwinkel_Soll : 30|10@1+ (0.01,0) [0.00|10.21] "Unit_DegreOfArc"  Vector__XXX
 SG_ HAL_max_Gradient : 40|7@1+ (0.1,0) [0.0|12.5] "Unit_DegreOfArcPerSecon"  Vector__XXX
 SG_ HAL_EFP_FahrPr : 48|4@1+ (1.0,0.0) [0.0|15] ""  Vector__XXX
 SG_ HAL_Status_2 : 52|3@1+ (1.0,0.0) [0.0|7] ""  Vector__XXX
 SG_ HAL_Charisma_Status : 58|2@1+ (1.0,0.0) [0.0|3] ""  Vector__XXX
 SG_ HAL_Charisma_FahrPr : 60|4@1+ (1.0,0.0) [0.0|15] ""  Vector__XXX

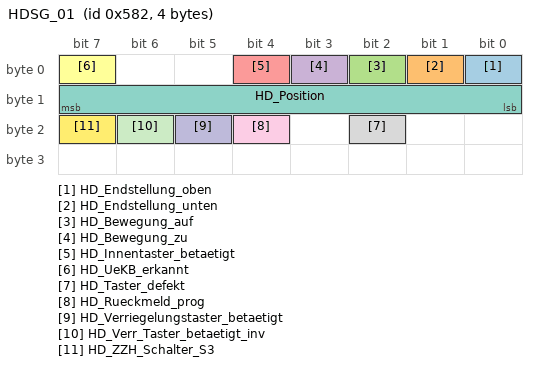
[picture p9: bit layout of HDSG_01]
BO_ 1410 HDSG_01: 4 Gateway
 SG_ HD_Endstellung_oben : 0|1@1+ (1.0,0.0) [0.0|1] ""  ZR_High
 SG_ HD_Endstellung_unten : 1|1@1+ (1.0,0.0) [0.0|1] ""  ZR_High
 SG_ HD_Bewegung_auf : 2|1@1+ (1.0,0.0) [0.0|1] ""  ZR_High
 SG_ HD_Bewegung_zu : 3|1@1+ (1.0,0.0) [0.0|1] ""  ZR_High
 SG_ HD_Innentaster_betaetigt : 4|1@1+ (1.0,0.0) [0.0|1] ""  ZR_High
 SG_ HD_UeKB_erkannt : 7|1@1+ (1.0,0.0) [0.0|1] ""  ZR_High
 SG_ HD_Position : 8|8@1+ (1,0) [0|100] "Unit_PerCent"  ZR_High
 SG_ HD_Taster_defekt : 18|1@1+ (1.0,0.0) [0.0|1] ""  ZR_High
 SG_ HD_Rueckmeld_prog : 20|1@1+ (1.0,0.0) [0.0|1] ""  Vector__XXX
 SG_ HD_Verriegelungstaster_betaetigt : 21|1@1+ (1.0,0.0) [0.0|1] ""  ZR_High
 SG_ HD_Verr_Taster_betaetigt_inv : 22|1@1+ (1.0,0.0) [0.0|1] ""  Vector__XXX
 SG_ HD_ZZH_Schalter_S3 : 23|1@1+ (1.0,0.0) [0.0|1] ""  Vector__XXX

BO_TX_BU_ 795 :Gateway,Gateway_PAG;
BO_TX_BU_ 508 :Gateway,Gateway_PAG;
BO_TX_BU_ 264 :Gateway,Gateway_PAG;
BO_TX_BU_ 2527679659 :Gateway,Gateway_PAG;
BO_TX_BU_ 429 :Gateway,Gateway_PAG;
BO_TX_BU_ 2527679658 :Gateway,Gateway_PAG;
BO_TX_BU_ 2331595995 :Gateway,Gateway_PAG;
BO_TX_BU_ 705 :Gateway,Gateway_PAG;
BO_TX_BU_ 2463978619 :Gateway,Gateway_PAG;
BO_TX_BU_ 2527679660 :Gateway,Gateway_PAG;
BO_TX_BU_ 707 :Gateway,Gateway_PAG;
BO_TX_BU_ 1605 :Gateway,Gateway_PAG;
BO_TX_BU_ 2589283684 :Gateway,Gateway_PAG;
BO_TX_BU_ 2549875571 :Gateway,Gateway_PAG;
BO_TX_BU_ 2550006643 :ZR_High,ZR_LIMU,ZR_MIB_TOP_ab_Gen3;
BO_TX_BU_ 173 :Gateway,Gateway_PAG;
BO_TX_BU_ 968 :Gateway,Gateway_PAG;
BO_TX_BU_ 177 :Gateway,Gateway_PAG;
BO_TX_BU_ 879 :Gateway,Gateway_PAG;
BO_TX_BU_ 884 :Gateway,Gateway_PAG;
BO_TX_BU_ 886 :Gateway,Gateway_PAG;
BO_TX_BU_ 888 :Gateway,Gateway_PAG;
BO_TX_BU_ 891 :Gateway,Gateway_PAG;
BO_TX_BU_ 1364 :Gateway,Gateway_PAG;
BO_TX_BU_ 299 :Gateway,Gateway_PAG;
BO_TX_BU_ 310 :Gateway,Gateway_PAG;
BO_TX_BU_ 1410 :Gateway,Gateway_PAG;
CM_ BO_ 795 "neu für MQB wg. Absicherung
Entstanden aus ESP_04";
CM_ BO_ 508 "CAN-Botschaft";
CM_ BO_ 264 "ab MLBevo mit CRC";
CM_ BO_ 879 "Nachricht 1 für Ortung:
Position und Fixtyp.";
CM_ BO_ 884 "Nachricht 2 für Ortung:
Latenz, Geschwindigkeit und Richtung.";
CM_ BO_ 886 "Nachricht 3 für Ortung:
Qualität der Ortung.";
CM_ BO_ 888 "Nachricht 4 für Ortung:
Zeitstempel der Ortung.";
CM_ BO_ 891 "Nachricht 5:
Empfängerstatus und UTC.";
CM_ BO_ 1364 "Nachricht 6:
Enthält Informationen über die Satelliten. Die Daten des stärksten Satelliten werden übertragen";

CM_ SG_ 795 ABS_Lampe "Sicherheitswarnlampe

Weiterführende Informationen im Lastenheft spezifiziert und in der entsprechenden Fachabteilung zu erfragen.";
CM_ SG_ 795 BK_Lampe_02 "Typ1_ein_statisch signalisiert EBV-Ausfall
MQB: wird auch bei HBV-Ausfall verwendet.

Typ1_ein_statisch: wird bei AUDI für Aktivierung der roten BKL ohne Text und Akustik verwendet (z.B. Lampenaufprüfung).
Typ2_ein_statisch: signalisiert elektrischen ";
CM_ SG_ 795 ESP_24_CRC "Für MLB:
'Berechnung siehe Lastenheft 'Kommunikationsabsicherung für FlexRay und CAN''

Ab MQB und MLBevo:
'Berechnung siehe Lastenheft 'End-to-End Kommunikationsabsicherung''

Endwerte siehe Begleitdokument 'S-PDU Kennungsfolgen'";
CM_ SG_ 795 ESP_BKV_Warnung "ESP sendet im Hinweis- /Störungsfall an das Kombi Informationen zum Anzeigen (Text + Akustik)

Im MQB wird dieses Signal nicht unterstützt!
";
CM_ SG_ 795 ESP_Fehlerstatus_Wegimp "Weiterführende Informationen im Lastenheft spezifiziert und in der entsprechenden Fachabteilung zu erfragen.

MLB: Fehler wird gesetzt, wenn beide ESP-Drehzahlfühler an der Vorderachse defekt sind.

MQB: Fehler wird gesetzt, wenn beide Raddrehzahlfühl";
CM_ SG_ 795 ESP_HDC_Geschw_Farbe "Farbdarstellung der angezeigten HDC-Geschwindigkeit";
CM_ SG_ 795 ESP_HDC_Regelgeschw "Verwendung/Bedienung nur im AU57x Allroad:
HDC-Geschwindigkeit
Dient der Anzeige der HDC-Geschwindigkeit und eines Bergabfahrsymbols im Kombi.
HDC-Standby wird gesetzt sobald der Fahrer den HDC-Taster aktiviert hat.
Bei HDC-Off oder während der Initia";
CM_ SG_ 795 ESP_Lampe "Zustand der Fahrdynamikregelungslampe (MLB: ASR und/oder ESP, MQB: nur ESP)

Weiterführende Informationen im Lastenheft spezifiziert und in der entsprechenden Fachabteilung zu erfragen.";
CM_ SG_ 795 ESP_m_Raddrehz "Radumdrehungen pro Sekunde sind Eingangsgröße für die Geschwindigkeitsberechnung im Kombi. Aus dieser Raddrehzahl und dem Radumfang wird die Fahrzeuggeschwindigkeit errechnet.

MLB: Exklusiver Empfänger ist das Kombiinstrument!
MQB: Bei Frontantrieb un";
CM_ SG_ 795 ESP_Meldungen "ESP sendet im Hinweis- /Störungsfall an das Kombi Informationen zum Anzeigen

Weiterführende Informationen im Lastenheft spezifiziert und in der entsprechenden Fachabteilung zu erfragen.
Ergänzender Hinweis:
1 = Autohold_Hinweis_1 (Anfahrassistent: nu";
CM_ SG_ 795 ESP_Off_Lampe "Bit zur Ansteuerung der separaten ESP-off-Lampe im Kombi (Gesetzesforderung USA)

MLB:
Verwendung/Bedienung ab D4";
CM_ SG_ 795 ESP_QBit_Wegimp_VA "Gesetzt bei Ersatzwert, Init oder Fehler.";
CM_ SG_ 795 ESP_Textanzeigen_03 "Textanzeigen der Fahrdynamikregelung im Kombiinstrument

Weiterführende Informationen im Lastenheft spezifiziert und in der entsprechenden Fachabteilung zu erfragen.

Der Signalwert 24 wird nur im BY736 verwendet.";
CM_ SG_ 795 ESP_Wegimp_Ueberlauf "Der Wegimpulszähler ist pro Zündungslauf mindestens einmal übergelaufen

Weiterführende Informationen im Lastenheft spezifiziert und in der entsprechenden Fachabteilung zu erfragen.";
CM_ SG_ 795 ESP_Wegimp_VA "Weiterführende Informationen im Lastenheft spezifiziert und in der entsprechenden Fachabteilung zu erfragen.

MLB: Die Wegimpulse Vorderachse sind die gemittelten Werte (reine mathematische Operation: Addition und Division durch zwei, keine Filterung) d";
CM_ SG_ 795 TC_Lampe "M-ABS Lampe (separate Lampe für M-ABS-Systeme Markt Brasilien)

Weiterführende Informationen im Lastenheft spezifiziert und in der entsprechenden Fachabteilung zu erfragen.";

CM_ SG_ 508 ESC_Anforderung_Airbrake "ESC fordert die Bremsperformancestellung der aktiven Aerodynamik";
CM_ SG_ 508 ESC_FBA_Meldungen "Hinweis an den Fahrer über das Kombi, bei dauerhafter Bergabfahrt einen Gang einzulegen um die Motorbremse zu nutzen.
Unterscheidung zwischen: 
Handschalterfahrzeugen (FBA_Warnung_aktiv_MT)
Automatikfahrzeugen (FBA_Warnung_aktiv_AT)";
CM_ SG_ 508 ESC_MBK_Meldungen "Das Signal steuert die Schaltempfehlung im Kombi, die bei Bergabfahrt den Fahrer darauf hinweist in eine geeignete Fahrstufe zu schalten um eine Rekuperation zu ermöglichen.";
CM_ SG_ 508 ESC_Motorstartverzoegerung "Mit dem Signal 'Motorstartverzögerung' wird den aktiven Teilnehmern ermöglicht, einen Motorstart durch die Start-Stop-Funktion zu verzögern.";
CM_ SG_ 508 ESP_32_BZ "Botschaft asynchron geroutet. Zählerwert kann springen.";
CM_ SG_ 508 ESP_32_CRC "Für MLB:
'Berechnung siehe Lastenheft 'Kommunikationsabsicherung für FlexRay und CAN''

Ab MQB und MLBevo:
'Berechnung siehe Lastenheft 'End-to-End Kommunikationsabsicherung''

Endwerte siehe Begleitdokument 'S-PDU Kennungsfolgen'";
CM_ SG_ 508 ESP_Aggregataktivitaet "Info über die Aktivität des ESP Aggregats bei aktivem Druckaufbau oder Ventilaktivität";
CM_ SG_ 508 ESP_AVH_LED "Ansteuerung der AVH Funktions-LED durch das BCM.
0 = LED aus
1 = LED ein
2 = LED blinken
3 = Funktion gesperrt, LED aus
4 = frei
5 = frei
6 = Init
7 = frei";
CM_ SG_ 508 ESP_EDS_Anzeige "Grafische Anzeige der EDS-Funktion im Kombiinstrument und MMI für Bentley";
CM_ SG_ 508 ESP_HDC_LED "Ansteuerung der HDC LED in der Schalterleiste durch BCM
0 = LED aus
1 = LED ein
2 = LED blinken
3 = Funktion gesperrt, LED aus
4 = frei
5 = frei
6 = Init
7 = frei";
CM_ SG_ 508 ESP_HDC_Textanzeigen "Textanzeigen der HDC im Kombiinstrument
Zustände 16,17,18 nur für Porsche";
CM_ SG_ 508 ESP_HOLD_verf "Das Signal ESP_HOLD_verf = 1 signalisiert dem Empfänger, dass die Aktivierungsbedingungen für die autonome HOLD-Funktion erfüllt sind (Steigung > parametrierbare Grenzsteigung mit Wunschfahrtrichtung bergauf) und die autonome HOLD-Funktion aktivierbar ist";
CM_ SG_ 508 ESP_Notbremsanzeige "ABS/ASR oder ESP hat Notbremssituation erkannt.
Weiterführende Informationen im Lastenheft spezifiziert und in der entsprechenden Fachabteilung zu erfragen.

";
CM_ SG_ 508 ESP_Off_LED "Ansteuerung der ESP-Off LED in der Schalterleiste durch BCM
0 = LED aus
1 = LED ein
2 = LED blinken
3 = Funktion gesperrt, LED aus
4 = frei
5 = frei
6 = Init
7 = frei";
CM_ SG_ 508 ESP_Offroad_Lampe "Anzeige der ESC-Offroad-Lampe im Kombiinstrument für Bentley";
CM_ SG_ 508 ESP_Rollover_Status_dyn "Information vom ESP an die Dämpferregelung über den dynamischen Rolloverstatus";
CM_ SG_ 508 ESP_Rollover_Status_stat "Information vom ESP an die Dämpferregelung über den statischen Rolloverstatus";
CM_ SG_ 508 ESP_Status_Bremsentemp_02 "Bremsscheibentemperaturmodell. Rückmeldung für Sender einer Verzögerungsanforderung";
CM_ SG_ 508 ESP_Stillstandsflag "Bei RB-Projekten wird das Stillstandsflag gesetzt, wenn der absolute Stillstand der Raddrehzahlsensoren erkannt wurde, d.h. kein Zahn bewegt sich mehr. Dieses Bit wird bspw. im MOST für TV-Tuner-Abschaltung Australien verwendet, d.h. leichte Erschütterung";
CM_ SG_ 508 ESP_Wiederstart_Anz_Std "Dieses Signal gibt die detaillierte Begründung für einen Wiederstart vom Bremsensteuergerät ausgelöst durch die HBC Funktion an.";
CM_ SG_ 508 RLE_Anzeigen "Anzeigen für die Radlöseerkennung";

CM_ SG_ 600 ESP_54_BZ "4bit Botschaftszähler, wird mit jeder Sendebotschaft inkrementiert";
CM_ SG_ 600 ESP_54_CRC "Für MLB:
Berechnung siehe Lastenheft 'Kommunikationsabsicherung für FlexRay und CAN'
Ab MQB und MLBevo:
Berechnung siehe Lastenheft 'End-to-End Kommunikationsabsicherung'

Endwerte siehe Begleitdokument 'S-PDU Kennungsfolgen'";
CM_ SG_ 600 ESP_DriftGong "Drift gong for kombi";
CM_ SG_ 600 ESP_DriftLevel "Drift level current position in ESC";
CM_ SG_ 600 ESP_DriftStatus "Status of drift controller in ESC";
CM_ SG_ 600 ESP_DriftText "Drift text for kombi";
CM_ SG_ 600 ESP_Slider_Gong "Slider gong  for kombi";
CM_ SG_ 600 ESP_Slider_ist_01 "Slider 1 current position in ESC";
CM_ SG_ 600 ESP_Slider_ist_02 "Slider 2 current position in ESC";
CM_ SG_ 600 ESP_Slider_ist_03 "Slider 3 current position in ESC";
CM_ SG_ 600 ESP_Slider_Lamp "Slider lamp  for kombi";
CM_ SG_ 600 ESP_Slider_Status "Status of Slider controller in ESC";
CM_ SG_ 600 ESP_Slider_Text "Slider text message for kombi";

CM_ SG_ 264 EFP_Anf_Bremsenkuehlung "Signal steuert das Oeffnen des Bremsenkuehlkanals und ggf. das Aktivieren eines unterstützenden Lüfters.";
CM_ SG_ 264 EFP_Reibwert_dyn "Dynamisch geschaetzter Reibwert zwischen Reifen und Strasse im Grenzbereich (Variante 2)";
CM_ SG_ 264 FA_Fahrbahnunebenheit "Informationsbeschreibung des Fahrbahnzustandes";
CM_ SG_ 264 FA_Hoehenwert_HL_00 "Aktueller Höhenwert (kalibriert) Hinten Links; ungefiltertes Signal
Einheit, Offset und Faktor sind abhänig von 'FA_Hoehenwert_kalibriert'

Achtung:
Wird im AUDI B8 nicht bedient";
CM_ SG_ 264 FA_Hoehenwert_HR_00 "Aktueller Höhenwert (kalibriert) Hinten Rechts; ungefiltertes Signal
Einheit, Offset und Faktor sind abhänig von 'FA_Hoehenwert_kalibriert'

Achtung:
Wird im AUDI B8 nicht bedient";
CM_ SG_ 264 FA_Hoehenwert_VL_00 "Aktueller Höhenwert (kalibriert) Vorne Links; ungefiltertes Signal
Einheit, Offset und Faktor sind abhänig von 'FA_Hoehenwert_kalibriert'

Achtung:
Wird im AUDI B8 nicht bedient";
CM_ SG_ 264 FA_Hoehenwert_VR_00 "Aktueller Höhenwert (kalibriert) Vorne Rechts; ungefiltertes Signal
Einheit, Offset und Faktor sind abhänig von 'FA_Hoehenwert_kalibriert'

Achtung:
Wird im AUDI B8 nicht bedient";
CM_ SG_ 264 FA_Hoehenwerte_kalibriert "Legt fest, wie die Höhensensorwerte interpretiert werden müssen. Umschaltung kalibrierte Höhenwerte / Rohsignale in Byte 3-6

Achtung:
Im AUDI B8 Konstante: 0x1. D.h. es werden nur Rohwerte bedient!
Im AUDI D4 Konstante: 0x0. D.h. es werden nur Millim";
CM_ SG_ 264 Fahrwerk_01_BZ "Botschaft asynchron geroutet. Zählerwert kann springen.";
CM_ SG_ 264 Fahrwerk_01_CRC "Für MLB:
'Berechnung siehe Lastenheft 'Kommunikationsabsicherung für FlexRay und CAN''

Ab MQB und MLBevo:
'Berechnung siehe Lastenheft 'End-to-End Kommunikationsabsicherung''

Endwerte siehe Begleitdokument 'S-PDU Kennungsfolgen'";

CM_ SG_ 2527679659 FA_Niveau_Druck_HL "Druck gemessen im Federbein HL";
CM_ SG_ 2527679659 FA_Niveau_Druck_HR "Druck gemessen im Federbein HR";
CM_ SG_ 2527679659 FA_Niveau_Druck_VL "Druck gemessen im Federbein VL";
CM_ SG_ 2527679659 FA_Niveau_Druck_VR "Druck gemessen im Federbein VL";

CM_ SG_ 429 EFP_Soll_FahrPr_HAL "Anforderung einer Zwangsumschaltung des Fahrprogramms der HAL durch EFP";
CM_ SG_ 429 FA_Absenkung_Fahrzeug "Nächsttieferes Niveau wird angefahren (Absenken). Dieses Bit wird immer gesetzt in Verbindung mit einer Auswahl aus den Bits FA_Verstellung_xx.";
CM_ SG_ 429 FA_Anhaengerstatus_intern "Anzeige des SG-internen Verarbeitungsstatus Anhängers";
CM_ SG_ 429 FA_Anhebung_Fahrzeug "Nächsthöheres Niveau wird angefahren (Anheben). Dieses Bit wird immer gesetzt in Verbindung mit einer Auswahl aus den Bits FA_Verstellung_xx.";
CM_ SG_ 429 FA_Druckspeicher_verfuegbar "Bit ist gesetzt, wenn eine Regelung aus dem Druckspeicher möglich ist.";
CM_ SG_ 429 FA_ESP_Zuschaltung "Zwangsweise Aktivierung der ESP-Funktionalität wird angefordert auch bei Passivtastung";
CM_ SG_ 429 FA_HAL_Abschaltung "Anforderung einer Zwangs-Deaktivierung der HAL wegen zu geringem
Radfreigang durch Luftfeder oder Schneekettenbetrieb.";
CM_ SG_ 429 FA_Kompressor_laeuft "Zustand der Kompressoransteuerung";
CM_ SG_ 429 FA_Kompressor_laeuft_in_Kuerze "Kompressorlauf steht unmittelbar bevor. Das Bit wird immer gesetzt in Verbindung mit den Bits FA_Anhebung_Fahrzeug oder FA_Absenkung_Fahrzeug.";
CM_ SG_ 429 FA_Signal_Drucksensor "Signalwert des Drucksensors im Magnetventilblock";
CM_ SG_ 429 FA_Systemstatus "Bit wird gesetzt, wenn interne Funktionsprüfung i.O. und System generell funktionsfähig ist.";
CM_ SG_ 429 FA_Verstellung_aktiv "Verstellung ist aktiv. Dieses Bit wird immer gesetzt in Verbindung mit den Bits FA_Anhebung_Fahrzeug oder FA_Absenkung_Fahrzeug.";
CM_ SG_ 429 FA_Verstellung_in_Kuerze "Dieses Bit wird gesetzt, wenn eine Verstellung unmittelbar bevorsteht.";
CM_ SG_ 429 FA_Zwischenniveau "Dieses Bit wird gesetzt, wenn die Fahrzeughöhe zwischen 2 definierten Niveaus liegt, z.B.. während des Regelvorgangs.";
CM_ SG_ 429 Fahrwerk_06_BZ "Botschaft asynchron geroutet. Zählerwert kann springen.";
CM_ SG_ 429 Fahrwerk_06_CRC "Ab MQB und MLBevo:
'Berechnung siehe Lastenheft 'End-to-End Kommunikationsabsicherung''

Endwerte siehe Begleitdokument 'S-PDU Kennungsfolgen'";
CM_ SG_ 429 NR_Anforderung_v_Begrenzung "Anforderung einer v-Begrenzung an das Motor-SG.";
CM_ SG_ 429 NR_Kompressor_Strom_02 "Gemessener Strom am Kompressors.";
CM_ SG_ 429 NR_Kompressor_Temp_Zylinderkopf "Gemessene Temperatur im Zylinderkopf des Luftfeder-Kompressors";
CM_ SG_ 429 NR_LED_BN "Statusrückmeldung der eingestellten Fahrzeughöhe Beladungsniveau bzw. Tasterbetätigung Anheben/Absenken.";
CM_ SG_ 429 NR_LED_HN "Statusrückmeldung der eingestellten Fahrzeughöhe Hochniveau
";
CM_ SG_ 429 NR_LED_SGN "Statusrückmeldung der eingestellten Fahrzeughöhe Sondergeländeniveau bzw. Tasterbetätigung Anheben/Absenken.";
CM_ SG_ 429 NR_LED_TN "Statusrückmeldung der eingestellten Fahrzeughöhe Tiefniveau";
CM_ SG_ 429 NR_Reglerstatus "Anzeige des auszuregelnden Sollniveaus (wird bei Beginn der Regelung auf entsprechenden Wert gesetzt).";

CM_ SG_ 2527679658 EFP_ReifenTemp_HL "Reifentemperatur hinten links";
CM_ SG_ 2527679658 EFP_ReifenTemp_HR "Reifentemperatur hinten rechts";
CM_ SG_ 2527679658 EFP_ReifenTemp_VL "Reifentemperatur vorne links";
CM_ SG_ 2527679658 EFP_ReifenTemp_VR "Reifentemperatur vorne rechts";
CM_ SG_ 2527679658 FA_Beladung_HA "Signal für Beladung (Achslast) aus dem Fahrzustandsbeobachter (FZB) als Vorsteuerinformation für die ABS-Regelung. 
Ausgabe als Delta zum DIN-Leer-Gewicht in 50 kg Schritten.
";
CM_ SG_ 2527679658 FA_Beladung_VA "Signal für Beladung (Achslast) aus dem Fahrzustandsbeobachter (FZB) als Vorsteuer­infor­ma­tion für die ABS-Regelung. 
Ausgabe als Delta zum DIN-Leer-Gewicht in 50 kg Schritten.
";
CM_ SG_ 2527679658 FA_FahrerAnf_Fahrwerk "Fahrwerk Fahrer Anforderung";
CM_ SG_ 2527679658 FA_FahrerAnf_Lift "Fahrer Lift Anforderung";
CM_ SG_ 2527679658 FA_FahrerAnf_Niveau "Niveau Fahrer Anforderung";

CM_ SG_ 2527679896 EFP_ReifenTempOf_HL "Oberflächennahe Reifentemperatur";
CM_ SG_ 2527679896 EFP_ReifenTempOf_HR "Oberflächennahe Reifentemperatur";
CM_ SG_ 2527679896 EFP_ReifenTempOf_VL "Oberflächennahe Reifentemperatur";
CM_ SG_ 2527679896 EFP_ReifenTempOf_VR "Oberflächennahe Reifentemperatur";
CM_ SG_ 2527679896 FA_FahrerAnf_Lift_Abwurf "Fahrer Lift Anforderung Abwurf";
CM_ SG_ 2527679896 FA_Niveau_AOCCT_fehlerstatus "Berechnung ActiveOffCycleCreditTechnology: Fahrwerk Niveau Fehler";
CM_ SG_ 2527679896 FA_Niveau_AOCCT_teststatus "Berechnung ActiveOffCycleCreditTechnology: Fahrwerk Niveau Diagnose durchgeführt";
CM_ SG_ 2527679896 FA_Niveau_AOCCT_timer1_count "Berechnung ActiveOffCycleCreditTechnology: Timer 1 für Fahrwerk Niveau Position <75%";
CM_ SG_ 2527679896 FA_Niveau_AOCCT_timer1_verbaut "Berechnung ActiveOffCycleCreditTechnology: Timer 1 für Fahrwerk Niveau verbaut und codiert";
CM_ SG_ 2527679896 FA_Niveau_AOCCT_timer2_count "Berechnung ActiveOffCycleCreditTechnology: Timer 2 für Fahrwerk Niveau Position >=75%";
CM_ SG_ 2527679896 FA_Niveau_AOCCT_timer2_verbaut "Berechnung ActiveOffCycleCreditTechnology: Timer 2 für Fahrwerk Niveau verbaut und codiert";
CM_ SG_ 2527679896 FA_Zuladung_HA "Signal für die Zuladung der Hinterachse aus dem EFP als delta Gewicht zu der kodierten Gewichtsklasse.";
CM_ SG_ 2527679896 FA_Zuladung_Status_HA "Status für die Zuladung der Hinterachse aus dem EFP";
CM_ SG_ 2527679896 FA_Zuladung_Status_VA "Status für die Zuladung der Vorderachse aus dem EFP";
CM_ SG_ 2527679896 FA_Zuladung_VA "Signal für die Zuladung der Vorderachse aus dem EFP als delta Gewicht zu der kodierten Gewichtsklasse.";
CM_ SG_ 2527679896 Fahrwerk_12_BZ "4bit Botschaftszähler, wird mit jeder Sendebotschaft inkrementiert";
CM_ SG_ 2527679896 Fahrwerk_12_CRC "Checksumme

Berechnung siehe Lastenheft 'End-to-End-Kommunkationsabsicherung'";

CM_ SG_ 2331595995 EFP_FVertDisp_HL "Vertikale Radaufstandskraft hinten links für Anzeigefunktion inkl. dynamischer Radlastverlagerung aus Längs- und Querbeschleunigung";
CM_ SG_ 2331595995 EFP_FVertDisp_HR "Vertikale Radaufstandskraft hinten rechts für Anzeigefunktion inkl. dynamischer Radlastverlagerung aus Längs- und Querbeschleunigung";
CM_ SG_ 2331595995 EFP_FVertDisp_VL "Vertikale Radaufstandskraft vorne links für Anzeigefunktion inkl. dynamischer Radlastverlagerung aus Längs- und Querbeschleunigung";
CM_ SG_ 2331595995 EFP_FVertDisp_VR "Vertikale Radaufstandskraft vorne rechts für Anzeigefunktion inkl. dynamischer Radlastverlagerung aus Längs- und Querbeschleunigung";

CM_ SG_ 705 DR_Warnung "Signal zur Ansteuerung von Dämpferregler-Warnungen im Kombiinstrument.";
CM_ SG_ 705 eABC_Texte "Signal zur Ansteuerung von Fahrerhinweisen im Kombi seitens eABC.";
CM_ SG_ 705 eABC_Warnung_Prio1 "Signal zur Ansteuerung von Prio1 Warnmeldungein im Kombi seitens eABC.";
CM_ SG_ 705 eABC_Warnung_Prio2 "Signal zur Ansteuerung von Prio2 Warnmeldungein im Kombi seitens eABC.";
CM_ SG_ 705 eAWS_Warnmeldung_Prio1 "Signal zur Ansteuerung der Prio1 Warnmeldung für das eAWS im Kombi ";
CM_ SG_ 705 eAWS_Warnmeldung_Prio2 "Signal zur Ansteuerung der Prio2 Warnmeldung für das eAWS im Kombi";
CM_ SG_ 705 EFP_Status_Taster_Fahrwerk "Status des EFP PAG Fahrwerkmodus";
CM_ SG_ 705 EFP_Status_Taster_Lift "Status des EFP Liftmodus";
CM_ SG_ 705 EFP_Verbau_DR "Verbauinfo Dämpferfunktion im EFP";
CM_ SG_ 705 EFP_Verbau_eABC "Verbauinfo eABC";
CM_ SG_ 705 EFP_Verbau_eAllrad "Verbauinfo eAllrad-Funktion im EFP";
CM_ SG_ 705 EFP_Verbau_eAWS "Verbauinfo eAWS";
CM_ SG_ 705 EFP_Verbau_LF "Verbauinfo Luftfederfunktion im EFP";
CM_ SG_ 705 EFP_Warnung_Naesse "Signal zur Ansteuerung von Naesse-Erkennung-Warnungen im Kombiinstrument";
CM_ SG_ 705 EFP_Warnung_Naesse_verf "Signal zur Ansteuerung von Fahrerhinweisen im Kombi";
CM_ SG_ 705 Fahrwerk_Anzeige_01_CRC "Für MLB:
'Berechnung siehe Lastenheft 'Kommunikationsabsicherung für FlexRay und CAN''

Ab MQB und MLBevo:
'Berechnung siehe Lastenheft 'End-to-End Kommunikationsabsicherung''

Endwerte siehe Begleitdokument 'S-PDU Kennungsfolgen'";
CM_ SG_ 705 FDR_Warnung_ALR "Warnmeldungen der Allradverteilung";
CM_ SG_ 705 FDR_Warnung_TV "Signal zur Ansteuerung von Warnungen im Kombi";
CM_ SG_ 705 LF_Texte "Signal zur Ansteuerung von Fahrerhinweisen im Kombi";
CM_ SG_ 705 LF_Texte_2 "Signal zur Ansteuerung von Fahrerhinweisen im Kombi";
CM_ SG_ 705 LF_Warnung_Prio1 "Signal zur Ansteuerung von Prio1-Warnungen im Kombi";
CM_ SG_ 705 LF_Warnung_Prio1_02 "Signal zur Ansteuerung von Prio1-Warnungen seitens Niveau im Kombi";
CM_ SG_ 705 LF_Warnung_Prio2 "Signal zur Ansteuerung von Prio2-Warnungen im Kombi";
CM_ SG_ 705 NR_LED_Ladelevel "Statusrückmeldung der eingestelten Fahrzeughöhe Ladelevel";
CM_ SG_ 705 NR_LED_Offroadlevel "Statusrückmeldung der eingestelten Fahrzeughöhe Offroadlevel";
CM_ SG_ 705 NR_LED_Strassenlevel "Statusrückmeldung der eingestelten Fahrzeughöhe Strassenlevel";
CM_ SG_ 705 NR_LED_Sync "Statusrückmeldung der Synchronität zwischen Luftfedersystem und Fahrprofilauswahl";
CM_ SG_ 705 NR_LED_XtraLevel "Statusrückmeldung der eingestelten Fahrzeughöhe XtraLevel";

CM_ SG_ 2463978619 FAS_SollStatus_Fkt_AbstWarn_LRR "FAS-ProfileMaster Sollstatus der Kundenfunktion";
CM_ SG_ 2463978619 FAS_SollStatus_Fkt_AbstWarn_MV "FAS-ProfileMaster Sollstatus der Kundenfunktion";
CM_ SG_ 2463978619 FAS_SollStatus_Fkt_ASW "FAS-ProfileMaster Sollstatus der Kundenfunktion";
CM_ SG_ 2463978619 FAS_SollStatus_Fkt_LGI "FAS-ProfileMaster Sollstatus der Kundenfunktion";
CM_ SG_ 2463978619 FAS_SollStatus_Fkt_MKE "FAS-ProfileMaster Sollstatus der Kundenfunktion";
CM_ SG_ 2463978619 FAS_SollStatus_Fkt_NV "FAS-ProfileMaster Sollstatus der Kundenfunktion";
CM_ SG_ 2463978619 FAS_SollStatus_Fkt_PreCrash "FAS-ProfileMaster Sollstatus der Kundenfunktion";
CM_ SG_ 2463978619 FAS_SollStatus_Fkt_STP "FAS-ProfileMaster Sollstatus der Kundenfunktion";
CM_ SG_ 2463978619 FAS_SollStatus_Fkt_SWA "FAS-ProfileMaster Sollstatus der Kundenfunktion";

CM_ SG_ 2527679660 FB_Blindheit "Blindheit: Sensor operativ aber Sichtbeeinträchtigung";
CM_ SG_ 2527679660 FB_Fahrerwechsel "Fahrerwechsel erkannt";
CM_ SG_ 2527679660 FB_Fehler "Fehler liegt vor";
CM_ SG_ 2527679660 FB_Kopfaktivitaet_A1 "kurzfristige Kopfbewegungen
";
CM_ SG_ 2527679660 FB_Kopfaktivitaet_A1_Guete "Guete kurzfristige Kopfbewegung";
CM_ SG_ 2527679660 FB_Kopfaktivitaet_A2 "langfristige Kopfbewegungen
";
CM_ SG_ 2527679660 FB_Kopfaktivitaet_A2_Guete "Guete Langfristige Kopfbewegung";
CM_ SG_ 2527679660 FB_Muedigkeit_Guete "Güte der Müdigkeitserkennung";
CM_ SG_ 2527679660 FB_Muedigkeit_Index "Müdigkeitsignal nach HFC Müdigkeitsskala";
CM_ SG_ 2527679660 FB_NichtVerfuegbar "Fahrerbeobachtung nicht verfügbar";

CM_ SG_ 707 eAWS_Warnmeldung_Prio3 "Signal zur Ansteuerung der Prio3 Warnmeldung für das eAWS im Kombi";
CM_ SG_ 707 EFP_Anf_Kuehlklappenwarnung "Signal wird zur Ansteuerung einer Kühlklappenwarnung im Kombiinstrument genutzt";
CM_ SG_ 707 EFP_MomRad_Begr "Begrenzung des beschleunigt wirkenden Antriebstrangsollmomentenanteils auf Summenradebene 
Für MLBevo: Faktor in TS_Faktor_Radmomente beachten!";
CM_ SG_ 707 FA_Warnung_Transportniveau "Signal zur Ansteuerung einer Warnmeldung, wenn beim Transportmodus das Zielniveau nicht angefahren wird";
CM_ SG_ 707 FDR_04_BZ "4bit Botschaftszähler, wird mit jeder Sendebotschaft inkrementiert";
CM_ SG_ 707 FDR_04_CRC "Für MLB:
Berechnung siehe Lastenheft 'Kommunikationsabsicherung für FlexRay und CAN'
Ab MQB und MLBevo:
Berechnung siehe Lastenheft 'End-to-End Kommunikationsabsicherung'

Endwerte siehe Begleitdokument 'S-PDU Kennungsfolgen'";
CM_ SG_ 707 FDR_M_HL_02 "Momentenanzeige für MMI.";
CM_ SG_ 707 FDR_M_HR_02 "Momentenanzeige für MMI.";
CM_ SG_ 707 FDR_M_VL_02 "Momentenanzeige für MMI.";
CM_ SG_ 707 FDR_M_VR_02 "Momentenanzeige für MMI.";

CM_ SG_ 1605 FLA_Abblendursache "FLA Abblendursache
(20ms Task)";
CM_ SG_ 1605 FLA_aktiv "FLA aktiv  (200ms Task)";
CM_ SG_ 1605 FLA_Aufblenden "FLA Aufblenden (20ms Task)";
CM_ SG_ 1605 FLA_Fernlicht_PWM "FLA PWM Vorgabe Fernlicht
(20ms Task)";
CM_ SG_ 1605 FLA_ISP_defekt "FLA Innenspiegel defekt
interner Fehler  (200ms Task)";
CM_ SG_ 1605 FLA_SAE_Mode "Rückmeldung an den Fahrer, über Wechsel in den SAE Modus --> wird nur für den amerikanischen Markt benötigt.";
CM_ SG_ 1605 FLA_Sensor_blockiert "FLA Sensor blockiert
Sichtbeeinträchtigung CMOS-Kamera  (200ms Task)";
CM_ SG_ 1605 ISP_Dimmung_ASP_02 "Dimmwertvorgabe für Aussenspiegel
Es wird 1:1 die Spannung am Innenspiegel nach außen übertragen.";
CM_ SG_ 1605 ISP_EC_aktiv "Status Innenspiegel (EC-Spiegel)";
CM_ SG_ 1605 ISP_EC_Lichtwert_hinten "Innenspiegel: Lichtwert hinten
";
CM_ SG_ 1605 ISP_EC_Lichtwert_vorne "Innenspiegel: Lichtwert vorne
";
CM_ SG_ 1605 ISP_Himmelsrichtung "Himmelsrichtung Kompass im EC Spiegel
Wertebereich 0-29 (12°-Schritte, 0-348°)
";
CM_ SG_ 1605 ISP_Kompass_aktiv "Status Kompass Innenspiegel";
CM_ SG_ 1605 ISP_Taste_betaetigt "ISP Taste betätigt
(200ms Task)";

CM_ SG_ 2589283684 FoD_Anz_Funktionsabschaltung "Signal triggert Aufschaltung eines Popups, um dem Fahrer die Abschaltung einer Funktion zu melden.";
CM_ SG_ 2589283684 FoD_Transmission_Info "Mit dem Signal zeigt der FoD-Master allen FoD-Slaves den Beginn und das Ende eines Freischaltuebertragungszykluses (FS-ID-Zyklus) an.";

CM_ SG_ 2549875571 FoD_ZR_Req_Data "FoD - Function On Demand
ISO-TP Datenkanal - FID2NA
Request Funktion 0x03 FoD-Master

FoD-Master an Zentralrechner";

CM_ SG_ 2550006643 FoD_ZR_Resp_Data "FoD - Function On Demand
ISO-TP Datenkanal - FID2NA
Response Knoten 0x73 Zentralrechner

Zentralrechner an FoD Master";

CM_ SG_ 173 GE_Fahrstufe "Fahrprogramm des Getriebes

Hinweis: Zwischenstellung '0x0' darf nur für Zustandswechsel P/R, R/N, N/D ausgegeben werden, nicht für D/S oder D/Tippgasse wegen Abschaltkriterium GRA/ACC";
CM_ SG_ 173 GE_Freig_MMom_Vorhalt "Freigabe für die Anforderung einer Momentenreserve durch das Getriebe über das Signal
MLB: GE_MMom_Vorhalt
MQB/MLBevo: GE_MMom_Vorhalt_02";
CM_ SG_ 173 GE_MMom_Soll_02 "Momenteneingriff an den Motor.
Fordert vom MSG eine kurzfristige Reduzierung oder Anhebung des Moments.
Das Signal ist nur gültig in Kombination mit GE_MMom_Status (bei MQB) bzw. GE_MMom_Status_02 (bei MLBevo).

Achtung:
Einheitenloser Wert! Faktor i";
CM_ SG_ 173 GE_MMom_Status "Qualifiziert 
MLB: GE_MMom_Soll
MQB: GE_MMom_Soll_02";
CM_ SG_ 173 GE_MMom_Status_02 "Das Signal qualifiziert GE_MMom_Soll_02 und gibt an, wie der Wert aus GE_MMom_soll – vorbehaltlich der Umsetzbarkeit aufgrund motorinterner Restriktionen – umgesetzt werden soll.
Werte:
0= kein Eingriff
1=   absoluter reduzierender Eingriff auf Gesamt ";
CM_ SG_ 173 GE_MMom_Vorhalt_02 "Anforderung einer Momentenreserve durch das Getriebe, gilt nur mit Freigabe durch 
GE_Freig_MMom_Vorhalt

Anforderung wird als Absolut-Wert umgesetzt, nicht als Relativ-Wert/Delta zum aktuellen Ist-Moment (d. h. eine Momentenreserve wird eingestellt, w";
CM_ SG_ 173 GE_reserv_Fahrstufe "reserviert, falls künftig Erweiterung von GE_Fahrstufe nötig";
CM_ SG_ 173 GE_Schaltablauf "Das Signal zeigt den aktuellen Status eines Schaltvorgangs.

Bei Signal = 0 liegt kein Schaltvorgang vor.
Bei Signal =2 liegt die Befüllphase der zuschaltenden Kupplung bzw. 
                      die Vorbereitungsphase dazu vor.

Mit den unterschie";
CM_ SG_ 173 GE_Status_Kraftschluss "Zeigt den Ist-Status des Kraftschlusses im Getriebe.
(Anmerkung: meist wird damit der Zustand des Anfahrelements beschrieben, d.h. bei DL/DQ die Kupplung;  bei AQ/AL der Wandler incl. Überbrückungskupplung)
0 = offen, kein Kraftschluss
1 = offen mit Kr";
CM_ SG_ 173 GE_Uefkt "Übertragungsfunktion des Getriebes
Drehzahlverhältnis = Eingangsdrehzahl / Ausgangsdrehzahl

AL: Wandlerverstärkung x Drehzahlverhältnis
VL: Drehzahlverhältnis
DL: Drehzahlverhältnis der aktiven und kraftschluß führenden Welle zum Abtrieb, bei Schalt";
CM_ SG_ 173 GE_Uefkt_unplausibel "Das Signal darf nur im Reku-Manager in Hybrid-Varianten verwendet werden.
Zeigt an, ob die Plausibilisierung Momenten-Verhältnis zu Drehzahl-Verhältnis i.O. ist.
Ein gesetztes Signal meldet eine unplausible GE_Uefkt bzw. GE_Uefkt_02.";
CM_ SG_ 173 GE_Verbot_Ausblendung "Verbot Einspritzausblendung für komfortable Schaltungen";
CM_ SG_ 173 GE_Zielgang "VL-Getriebe:
Signalisiert den Zielgang im manuellen Modus während eines Schaltvorgangs bzw. die momentane simulierte Gangstufe wenn kein Schaltvorgang aktiv ist. In den Fahrprogrammen 'D' und 'S' ist die Übersetzung variabel und somit wird dauerhaft 'Ist";
CM_ SG_ 173 Getriebe_11_BZ "Botschaftszähler
Botschaft asynchron geroutet. Zählerwert kann springen.";
CM_ SG_ 173 Getriebe_11_CRC "Für MLB:
'Berechnung siehe Lastenheft 'Kommunikationsabsicherung für FlexRay und CAN''

Ab MQB und MLBevo:
'Berechnung siehe Lastenheft 'End-to-End Kommunikationsabsicherung''

Endwerte siehe Begleitdokument 'S-PDU Kennungsfolgen'";

CM_ SG_ 968 Freilauf_Charisma_FahrPr "MLBevo: Aktuelles Fahrprogramm des Charisma-Teilnehmers (siehe Systemlastenheft Drive Select)
MQB: Istwert der Kennlinie (siehe Systemlastenheft MQB FPA)";
CM_ SG_ 968 Freilauf_Charisma_Status "Charisma Systemstatus des Charisma-Teilnehmers

Wert 0x3 ist nur für Fahrzeuge ab MQB relevant";
CM_ SG_ 968 GE_amax_moeglich "AL/DL: maximal mögliche Beschleunigung unter Berücksichtigung aller möglichen Gänge.

Eine Reduzierung des maximalen Motormoments durch Efficiency wird in dem Signal berücksichtigt.

VL: maximal mögliche Beschleunigung bei Nenndrehzahl (Efficency wird";
CM_ SG_ 968 GE_Charisma_FahrPr "MLBevo: Aktuelles Fahrprogramm des Charisma-Teilnehmers (siehe Systemlastenheft Drive Select)
MQB: Istwert der Kennlinie (siehe Systemlastenheft MQB FPA)";
CM_ SG_ 968 GE_Charisma_Status "Charisma Systemstatus des Charisma-Teilnehmers

Wert 0x3 ist nur für Fahrzeuge ab MQB relevant";
CM_ SG_ 968 GE_Codierung_MSG "Statusausgabe der Diagnose für Falschverbau. Plausibilisierung der empfangenen Motor- und Getriebevariante mit der erwarteten Motor- und Getriebevarianten.";
CM_ SG_ 968 GE_Freigabe_Info_WFS "WFS-Freigabeinformation";
CM_ SG_ 968 GE_Freigabe_Verfallsinfo_WFS "WFS";
CM_ SG_ 968 GE_LaunchControl "Während einer LaunchControl-Anfahrt sendet das Getriebesteuergerät das Bit LaunchControl aktiv.
Die Bremse wertet dieses Bit aus, um während einer solchen Anfahrt die Regelgrenzen der Schlupfregelung zu erweitern.
Im Motor Nutzung zur Verbesserung des A";
CM_ SG_ 968 GE_LaunchControl_LB "LB launch control status";
CM_ SG_ 968 GE_LFR_Adaption "Qualifiziert das ausgegeben Motorbelastungsmoment (durch GE_Vorsteuermoment) für die Verwendung zur LFR (Leerlauffüllungsregelung) im Moto";
CM_ SG_ 968 GE_OBD_AbsperrVent "Das Getriebesteuergerät führt eine elektrische Diagnose des von ihm angesteuerten Absperrventils für den Öl-Wasser-Wärmetauscher durch und übermittelt das Ergebnis an das MSG (Standard-4Bit-OBD-Status, nicht alle Zustände müssen genutzt werden; so sind z.";
CM_ SG_ 968 GE_OBD_Status "Dieses Bit steuert die MIL-Lampe an (Motorsteuergerät reicht diese Info an Kombi weiter).";
CM_ SG_ 968 GE_Remotestart_Betrieb "Das GSG ist für den Remotestart-Betrieb bereit. Nach Empfang der Motorstartanforderung für RSt-Betrieb durch BCM wird der Fahrzeugmotor gestartet und solange der Motor läuft, bleibt dieses Bit aktiv. Dieses Signal ist nur zur Verwendung durch das BCM zur ";
CM_ SG_ 968 GE_Sperr_Info_WFS "WFS-Sperrinformation";
CM_ SG_ 968 GE_Status_PaddleNeutral "Status Ablauf der Paddle Neutral Funktion";
CM_ SG_ 968 GE_Sumpftemperatur "Getriebesumpftemperatur wird über den Temperatursensor auf der Getriebeplatine ermittelt. Die absolute Sumpftemperatur wird vom Motor empfangen, um entsprechende Kühlleistung für das Getriebe einzustellen.";
CM_ SG_ 968 GE_Zustand_Kuppltemp "Dieses Signal gibt den Temperaturzustand der Kupplung im DQ-Getriebe (z. Zt. DQ2x0, DQ500) an das ACC-System.";

CM_ SG_ 177 GE_Anschleppstart_Freigabe "Bilden einer Schleppstartfreigabe aus Fahrdynamiksicht. Schleppstartabbruch bei kritischer Fahrzeugstabilität";
CM_ SG_ 177 GE_Eingangsdrehz_Praed "prädizierte Getriebe-Eingangsdrehzahl (während Schaltungen kann die voraussichtliche Drehzahl am Ende der Schaltung gezeigt werden)";
CM_ SG_ 177 GE_Fahrprogramm "Signalisiert das Fahrprogramm  im Bezug auf
die Fahrstufe des Getriebes.

Audi/MQB:
Offroad

Bentley:
Snow
Gravel
Mud_Ruts
Sand_Dune

Touareg:
Offroad
Snow";
CM_ SG_ 177 GE_Freilauf_Status "Freilauf-Status-Signal vom Frailauf-Master an aktive Freilauf-Teilnehmer. In diesem Signal zeigt der Freilauf-Master an, welchen aktuellen Status die Freilauf-Betriebsstrategie hat.";
CM_ SG_ 177 GE_Getriebestatus_02 "Signalisierung von speziellen Betriebszuständen des Getriebes:
1= Rennstartvorbereitung; genutzt im MSG zum Aufbau einer Momentenreserve, in Allrad und Quersperre (GQS)
2= Rennstart; nicht genutzt im MSG
3= Anfahrt; genutzt im MSG zur Umschaltung des F";
CM_ SG_ 177 GE_Grundeinstellung "Grundeinstellung des Getriebes ist aktiv

Hinweis:
Verwendung nur im MQB";
CM_ SG_ 177 GE_KomFehler_ESP "Anzeige Kommunikationsfehler bei Empfang vom ESP.

Einsatz nur in PDK-Projekten.";
CM_ SG_ 177 GE_Rollrichtung_falsch "Rollrichtung des Fahrzeugs ist entgegen der eingelegten Fahrstufe (bezogen auf GE_Fahrstufe);
0 = Rollrichtung richtig bzw. Init (auch im Stillstand bzw. in P/N/Zwischenposition)
1 = Rollrichtung falsch";
CM_ SG_ 177 GE_Strombedarf_erh "Das GSG teilt dem MSG einen aufgrund der Kühlung erhöhten Strombedarf mit, damit gleichzeitig die Kühler-Lüfter-Ansteuerung kurzzeitig reduziert wird.

Signal wird bisher nur im MQB-PHEV verwendet.";
CM_ SG_ 177 GE_TippZustand "Zeigt den Tippzustand in eine Fahrstufe und ein Fahrprogramm via Paddles oder Schaltbetätigung an.
Das Signal ist gültig in Kombination mit GE_Fahrstufe und GE_Fahrprogramm.

MLBevo:
DL und AL: nur Tipp_in_permanent
PDK2: Tipp_in_temporaer und Tipp_i";
CM_ SG_ 177 GE_Uefkt_Praed "Praedizierte Triebstrangübertragungsfunktion 
(Verständnis Übertragungsfunktion gemäß Ge_Uefkt_02)
Weiterführende Informationen sind bei der entsprechenden Fachabteilung zu erfragen.";
CM_ SG_ 177 Getriebe_17_BZ "Botschaftszähler
Botschaft asynchron geroutet. Zählerwert kann springen.";
CM_ SG_ 177 Getriebe_17_CRC "Für MLB:
'Berechnung siehe Lastenheft 'Kommunikationsabsicherung für FlexRay und CAN''

Ab MQB und MLBevo:
'Berechnung siehe Lastenheft 'End-to-End Kommunikationsabsicherung''

Endwerte siehe Begleitdokument 'S-PDU Kennungsfolgen'";

CM_ SG_ 879 GNSS_Breite_Ortung "Breitengrad des Ortungsergebnisses nach WGS84 als Kombination von mehreren GNSSen";
CM_ SG_ 879 GNSS_Fehlerzustand "Fehlerzustand von der GNSS-Funktion, daraufhin können keine GNSS-Daten geliefert werden";
CM_ SG_ 879 GNSS_Laenge_Ortung "Längengrad des Ortungsergebnisses nach WGS84 als Kombination von mehreren GNSSen";
CM_ SG_ 879 GNSS_Nachrichtenpaket_ID1 "+1 für jedes neue Paket. Zyklische ID-Vergabe (Zähler). Zur Identifizierung zusammenhängender Nachrichten, die die Daten derselben GNSS-Ortung enthalten und somit zum selben Zyklus gehören. D.h. Daten in den Nachrichten wurden zur selben Zeit erzeugt. Der";
CM_ SG_ 879 GNSS_Ortung_FIX_Typ "Art des 'GNSS-Fix' für die aktuelle Position auf Basis mehrerer GNSS Systeme.";
CM_ SG_ 879 GNSS_Richtung_Breite_Ortung "Richtung des Breitengrads des Ortungsergebnisses nach WGS84 als Kombination von mehreren GNSSen";
CM_ SG_ 879 GNSS_Richtung_Laenge_Ortung "Richtung des Längengrads des Ortungsergebnisses nach WGS84 als Kombination von mehreren GNSSen";

CM_ SG_ 884 GNSS_Nachrichtenpaket_ID2 "+1 für jedes neue Paket. Zyklische ID-Vergabe (Zähler). Zur Identifizierung zusammenhängender Nachrichten, die die Daten derselben GNSS-Ortung enthalten und somit zum selben Zyklus gehören. D.h. Daten in den Nachrichten wurden zur selben Zeit erzeugt. Der";
CM_ SG_ 884 GNSS_Ortung_2D_Geschw_ue_Grund "Geschwindigkeit in m pro Sekunde entsprechend dem GNSS-Empfänger";
CM_ SG_ 884 GNSS_Ortung_Ausrichtung "Ausrichtung (Kurswinkel) der GNSS-Messung";
CM_ SG_ 884 GNSS_Ortung_Latenz "Latenz zwischen GNSS-Messung und aktueller Verteilung über CAN-Bus.
Hinweis: Zur Stabilisierung der Latenz soll die GNSS-Zeit für die Bestimmung der CAN-Zyklendauer verwendet werden.";
CM_ SG_ 884 GNSS_Ortung_Noerdliche_Geschw "Geschwindigkeit in m pro Sekunde in Nordrichtung entsprechend dem GNSS-Empfänger";
CM_ SG_ 884 GNSS_Ortung_Oestliche_Geschw "Geschwindigkeit in m pro Sekunde in Ostrichtung entsprechend dem GNSS-Empfänger";
CM_ SG_ 884 GNSS_Ortung_Vertikale_Geschw "Geschwindigkeit  in m pro Sekunde in vertikaler Richtung (aufwärts) entsprechend dem GNSS-Empfänger";

CM_ SG_ 886 GNSS_Nachrichtenpaket_ID3 "+1 für jedes neue Paket. Zyklische ID-Vergabe (Zähler). Zur Identifizierung zusammenhängender Nachrichten, die die Daten derselben GNSS-Ortung enthalten und somit zum selben Zyklus gehören. D.h. Daten in den Nachrichten wurden zur selben Zeit erzeugt. Der";
CM_ SG_ 886 GNSS_Ortung_GDOP "Synthetischer Wert für den Verlust an Präzision der Postions- und Zeitmessung auf Grund der Satellitenkonstellation";
CM_ SG_ 886 GNSS_Ortung_Guete_Ausrichtung "Gesamtgenauigkeit bezüglich der Ausrichtung (Kurswinkel)";
CM_ SG_ 886 GNSS_Ortung_Guete_Geschwindigk "Gesamtgenauigkeit bezüglich Geschwindigkeit am Erdboden";
CM_ SG_ 886 GNSS_Ortung_Guete_horizontal "Gesamtgenauigkeit bezüglich der 2D-Position (horzontal)";
CM_ SG_ 886 GNSS_Ortung_Guete_vertikal "Gesamtgenauigkeit bezüglich der 1D-Position (vertikal)";
CM_ SG_ 886 GNSS_Ortung_HDOP "Synthetischer Wert für den Verlust an Präzision der 2D-Postionsmessung (horizontal) auf Grund der Satellitenkonstellation";
CM_ SG_ 886 GNSS_Ortung_PDOP "Synthetischer Wert für den Verlust an Präzision der Postionsmessung auf Grund der Satellitenkonstellation";
CM_ SG_ 886 GNSS_Ortung_VDOP "Synthetischer Wert für den Verlust an Präzision der 1D-Postionsmessung (vertikal) auf Grund der Satellitenkonstellation";

CM_ SG_ 888 GNSS_Nachrichtenpaket_ID4 "+1 für jedes neue Paket. Zyklische ID-Vergabe (Zähler). Zur Identifizierung zusammenhängender Nachrichten, die die Daten derselben GNSS-Ortung enthalten und somit zum selben Zyklus gehören. D.h. Daten in den Nachrichten wurden zur selben Zeit erzeugt. Der";
CM_ SG_ 888 GNSS_Ortung_Hoehe "Höhe über dem Meeresspiegel";
CM_ SG_ 888 GNSS_Ortung_Zeit_in_GPSWoche "Zeitstempel für die Jitter-Prüfung aso. Zeit muss sychron zur Zeit der GNSS-Ortung sein.";

CM_ SG_ 891 GNSS_Empfaenger_Status "Im 'Backup Mode' wird z.B. die UTC Zeit durch eine gepufferte 'Realtime Clock' bereitgestellt.
Im 'Live Mode' wird die UTC Zeit durch das GNSS Modul bereitgestellt. ";
CM_ SG_ 891 GNSS_Empfangbare_Satelliten "Anzahl der Satelliten, welche bei der aktuellen Satellitenkonfiguration ptentiell verfügbar sind";
CM_ SG_ 891 GNSS_Genutzte_Satelliten "Anzahl der Satelliten, welche für die aktuelle Ortung verwendet werden";
CM_ SG_ 891 GNSS_GLONASS_in_Nutzung "1: das genannte GNSS wurde für die Ortung verwendet";
CM_ SG_ 891 GNSS_GPS_in_Nutzung "1: das genannte GNSS wurde für die Ortung verwendet";
CM_ SG_ 891 GNSS_Nachrichtenpaket_ID5 "+1 für jedes neue Paket. Zyklische ID-Vergabe (Zähler). Zur Identifizierung zusammenhängender Nachrichten, die die Daten derselben GNSS-Ortung enthalten und somit zum selben Zyklus gehören. D.h. Daten in den Nachrichten wurden zur selben Zeit erzeugt. Der";
CM_ SG_ 891 GNSS_Sichtbare_Satelliten "Anzahl der Satelliten, welche aktuell empfangen werden";
CM_ SG_ 891 GNSS_UTC_Zeit "UTC-Zeit, Sekunden seit dem 01.01.1970 00:00";

CM_ SG_ 1364 GNSS_Nachrichtenpaket_ID6 "+1 für jedes neue Paket. Zyklische ID-Vergabe (Zähler). Zur Identifizierung zusammenhängender Nachrichten, die die Daten derselben GNSS-Ortung enthalten und somit zum selben Zyklus gehören. D.h. Daten in den Nachrichten wurden zur selben Zeit erzeugt. Der";
CM_ SG_ 1364 GNSS_Sat_Info_Azimuth_ID_1 "Azimut des Satelliten";
CM_ SG_ 1364 GNSS_Sat_Info_Hoehenwinkel_ID_1 "Höhenwinkel des Satelliten";
CM_ SG_ 1364 GNSS_Sat_Info_Sat_ID_1 "ID des Satelliten";
CM_ SG_ 1364 GNSS_Sat_Info_SNR_ID_1 "Signal-Rausch-Verhältnis des Satelliten";

CM_ SG_ 299 GRA_Abbrechen "GRA : aus mit speichern
ACC : Soft aus";
CM_ SG_ 299 GRA_ACC_01_BZ "4bit Botschaftszaehler, wird mit jeder Sendebotschaft inkrementiert
Botschaft asynchron geroutet. Zählerwert kann springen.";
CM_ SG_ 299 GRA_ACC_01_CRC "Für MLB:
'Berechnung siehe Lastenheft 'Kommunikationsabsicherung für FlexRay und CAN''

Ab MQB und MLBevo:
'Berechnung siehe Lastenheft 'End-to-End Kommunikationsabsicherung''

Endwerte siehe Begleitdokument 'S-PDU Kennungsfolgen'";
CM_ SG_ 299 GRA_Codierung "Das Signal zeigt an, ob das Sende-SG (SMLS/MFL) auf GRA- oder ACC-Bedienteil codiert ist:
0: kein GRA- oder ACC Bedienteil
1: GRA-Bedienteil
2: ACC-Bedienteil
3: Limiter_Only-Bedienteil";
CM_ SG_ 299 GRA_Fehler "Das Signal zeigt an, dass das Sende-SG (SMLS/MFG) einen Defekt des GRA-Bedienteils erkannt hat und hierzu ein FSPE abgelegt wurde.";
CM_ SG_ 299 GRA_Hauptschalter "Stellung des GRA/ACC-Hauptschalters: 
Bei gerastetem Hauptschalter:
0: Hauptschalter aus
1: Hauptschalter ein
Bei getastetem Hauptschalter:
0: Taster nicht betätigt
1: Taster betätigt";
CM_ SG_ 299 GRA_LIM_Taste_verfuegbar "Das Signal zeigt an, ob eine Limiter-Umschalttaste am jeweiligen GRA/ACC-Bedienelement vorhanden ist.";
CM_ SG_ 299 GRA_Limiter "Stellung des Limiter-Tasters";
CM_ SG_ 299 GRA_reserveByte4 "Zweck: Befüllen der reservierten Bitpositionen mit 0 (wg. LIN-Teilnehmer MFL)";
CM_ SG_ 299 GRA_reserveByte5 "Zweck: Befüllen der reservierten Bitpositionen mit 0 (wg. LIN-Teilnehmer MFL)";
CM_ SG_ 299 GRA_reserveByte6 "Zweck: Befüllen der reservierten Bitpositionen mit 0 (wg. LIN-Teilnehmer MFL)";
CM_ SG_ 299 GRA_reserveByte7 "Zweck: Befüllen der reservierten Bitpositionen mit 0 (wg. LIN-Teilnehmer MFL)";
CM_ SG_ 299 GRA_reserveByte8 "Zweck: Befüllen der reservierten Bitpositionen mit 0 (wg. LIN-Teilnehmer MFL)";
CM_ SG_ 299 GRA_Tip_Hoch "Tippschalter Tip Up / Geschwindigkeit erhöhen";
CM_ SG_ 299 GRA_Tip_Runter "Tippschalter Tip Down / Geschwindigkeit reduzieren";
CM_ SG_ 299 GRA_Tip_Setzen "Tippschalter Set";
CM_ SG_ 299 GRA_Tip_Stufe_2 "Signal zeigt an, dass der zweistufige GRA/ACC-Hebel (8_Positions_Bedienteil) in der 2. Tip-Stufe betätigt wird. Das Signal wird nur gleichzeitig mit dem Signal GRA_Tip_Hoch oder GRA_Tip_Runter gesetzt, wobei die Bits GRA_Tip_Hoch bzw. GRA_Tip_Runter die R";
CM_ SG_ 299 GRA_Tip_Wiederaufnahme "Tippschalter Wiederaufnahme";
CM_ SG_ 299 GRA_TravelAssist "Taste für TravelAssist";
CM_ SG_ 299 GRA_Typ_Bedienteil "Das Signal kennzeichnet die Variante des GRA/ACC-Bedienteils:
0: Init
1: 4-Positionen-Bedienteil (z.B. GRA im Blinkerhebel)
2: 6-Positionen-Bedienteil (GRA/ACC-Bedienteil mit separaten Stellungen für Set/Resume/TipUp/TipDown) 
3: 8-Positionen-Bediente";
CM_ SG_ 299 GRA_Typ_Hauptschalter "Variante des GRA/ACC-Hauptschalters:
0: gerasteter Hauptschalter (bzw. Taster mit Speicherung des Status im SMLS (PAG))
1: getasteter Hauptschalter, keine Speicherung des Status im SMLS";
CM_ SG_ 299 GRA_Verstellung_Zeitluecke "Verstellung der Zeitlücke für ACC

DIST -1 = Zeitluecke um 1 Stufe kleiner
DIST +1 = Zeitluecke um 1 Stufe groeßer
DIST Toggle = Zeitlücke um 1 Stufe kleiner, von kleinster Stufe auf größte Stufe";

CM_ SG_ 310 HAL_01_BZ "Botschaft asynchron geroutet. Zählerwert kann springen.";
CM_ SG_ 310 HAL_01_CRC "Für MLB:
'Berechnung siehe Lastenheft 'Kommunikationsabsicherung für FlexRay und CAN''

Ab MQB und MLBevo:
'Berechnung siehe Lastenheft 'End-to-End Kommunikationsabsicherung''

Endwerte siehe Begleitdokument 'S-PDU Kennungsfolgen'
";
CM_ SG_ 310 HAL_Charisma_FahrPr "MLBevo: Aktuelles Fahrprogramm des Charisma-Teilnehmers (siehe Systemlastenheft Drive Select)
MQB: Istwert der Kennlinie (siehe Systemlastenheft MQB FPA)";
CM_ SG_ 310 HAL_Charisma_Status "Rückmeldung an den Charisma-Master";
CM_ SG_ 310 HAL_EFP_FahrPr "Aktueller Ist-Zustand der HAL";
CM_ SG_ 310 HAL_Fahrerwunschwinkel_Soll "Zielwinkel (=Fahrerwunschwinkel) am Rad Hinterachslenkung in Grad";
CM_ SG_ 310 HAL_max_Gradient "maximaler Zustellgradient für die Stabilisierungsfunktion mit HAL durch ESP";
CM_ SG_ 310 HAL_QBit_Radwinkel "Wenn Bit gesetzt, dann entspreicht das Signal nicht mehr ASIL-D. (z.B. Ausfall der redundanten Sensorik)";
CM_ SG_ 310 HAL_Radwinkel "Zusätzlich durch die HAL gestellter Radwinkeloffset an der Hinterachse in Grad";
CM_ SG_ 310 HAL_Status "Status der Hinterachslenkung
0: normaler Betrieb 
1: HAL verriegelt (z.B. harter Fehler, nicht kalibriert)
2: Rücknahme der Leistung, Funktion eingeschränkt/Derating aktiv 
3: HAL deaktiviert";
CM_ SG_ 310 HAL_Status_2 "Zustand der Hinterachlenkung in der Smart application";
CM_ SG_ 310 HAL_VZ_Fahrerwunschwinkel_Soll "Soll-Lenkrichtung der HAL";
CM_ SG_ 310 HAL_VZ_Radwinkel "Lenkrichtung der HAL";
CM_ SG_ 310 HAL_Warnungen "Warnmeldungsanforderung von der Hinterachslenkung an das Kombiinstrumnent";
CM_ SG_ 310 HAL_Winkelbegrenzung "Signal liefert die Info über eine aktive Winkelbegrenzung in der HAL aufgrund Bauteilschutz";

CM_ SG_ 1410 HD_Bewegung_auf "Bewegung HD (öffnen)";
CM_ SG_ 1410 HD_Bewegung_zu "Bewegung HD (schließen)";
CM_ SG_ 1410 HD_Endstellung_oben "obere Endstellung HD
";
CM_ SG_ 1410 HD_Endstellung_unten "untere Endstellung HD";
CM_ SG_ 1410 HD_Innentaster_betaetigt "Betätigung Innentaster HD
";
CM_ SG_ 1410 HD_Position "HD Position von 0 bis 100 %";
CM_ SG_ 1410 HD_Rueckmeld_prog "Programmierung Endstellung HD 
";
CM_ SG_ 1410 HD_Taster_defekt "Anzeige ob Heckdeckeltaster defekt ist";
CM_ SG_ 1410 HD_UeKB_erkannt "Erkennung Einklemmschutz";
CM_ SG_ 1410 HD_Verr_Taster_betaetigt_inv "Inverses Bit (Fusi-Anforderung) Betätigung des Verriegelungstaster für Heckdeckel";
CM_ SG_ 1410 HD_Verriegelungstaster_betaetigt "Betätigung des Verriegelungstaster für Heckdeckel";
CM_ SG_ 1410 HD_ZZH_Schalter_S3 "Teilt den Zustand des Statusschalters in einer unidirektionalen ZZH mit.";
BA_DEF_REL_ BU_SG_REL_  "GenSigTimeoutTime" INT 0 65535;
BA_DEF_ BO_  "DiagRequest" ENUM "No", "Yes";
BA_DEF_ BO_  "DiagResponse" ENUM "No", "Yes";
BA_DEF_ BO_  "DiagState" ENUM "No", "Yes";
BA_DEF_ BO_  "GenMsgChkConstant" HEX 0 4095;
BA_DEF_ BO_  "GenMsgCycleTime" INT 0 65535;
BA_DEF_ BO_  "GenMsgCycleTimeFast" INT 0 65535;
BA_DEF_ BO_  "GenMsgDelayTime" INT 0 100000;
BA_DEF_ BO_  "GenMsgILSupport" ENUM "No", "Yes";
BA_DEF_ BO_  "GenMsgNrOfRepetition" INT 0 100;
BA_DEF_ BO_  "GenMsgPDUConstants" STRING;
BA_DEF_ BO_  "GenMsgSendType" ENUM "Cyclic", "not_used", "not_used", "not_used", "not_used", "not_used", "not_used", "IfActive", "NoMsgSendType";
BA_DEF_ BO_  "GenMsgStartDelayTime" INT 0 100000;
BA_DEF_ BO_  "NmMessage" ENUM "No", "Yes";
BA_DEF_ BO_  "NmhMessage" ENUM "No", "Yes";
BA_DEF_ BO_  "MsgType" ENUM "Application", "NM ", "NMH", "TP2.0", "ISO-TP ", "BAP", "EID", "KS", "XCP_PRE_CONFIGURED", "XCP_RUNTIME_CONFIGURED";
BA_DEF_ BO_  "VAGTP20_API" HEX 0 255;
BA_DEF_ BO_  "VAGTP20_DynConnection" ENUM "No", "Yes";
BA_DEF_ BO_  "VAGTP20_DynSetup" ENUM "No", "Yes";
BA_DEF_ BO_  "VAGTP20_StatConnection" ENUM "No", "Yes";
BA_DEF_ SG_  "GenSigActiveRepetitions" INT -2147483648 2147483647;
BA_DEF_ SG_  "GenSigInactiveValue" INT -2147483648 2147483647;
BA_DEF_ SG_  "GenSigSendType" ENUM "Cyclic", "OnWrite", "OnWriteWithRepetition", "OnChange", "OnChangeWithRepetition", "IfActive", "IfActiveWithRepetition", "NoSigSendType", "OnChangeAndIfActive", "OnChangeAndIfActiveWithRepetition";
BA_DEF_ SG_  "GenSigStartValue" INT -2147483648 2147483647;
BA_DEF_ SG_  "NWM-WakeupAllowed" ENUM "No", "Yes";
BA_DEF_ SG_  "GenSigFuncType" ENUM "NoFunction", "MsgCounter", "CRC-8", "XOR", "XOR-2", "DatedBit", "SW-Kl15", "CHK", "Constant", "Protocol", "CRC-8-SAE_J1850", "CRC-32", "DataLength", "DataID", "MsgCounter16", "SOK-Signatur", "Cluster";
BA_DEF_ SG_  "GenSigSwitchedByIgnition" ENUM "No", "Yes";
BA_DEF_ SG_  "Fehlerwert" HEX 0 2147483647;
BA_DEF_ SG_  "GenSigMissingSourceValue" HEX 0 2147483647;
BA_DEF_DEF_REL_  "GenSigTimeoutTime" 0;
BA_DEF_DEF_  "DiagRequest" "No";
BA_DEF_DEF_  "DiagResponse" "No";
BA_DEF_DEF_  "DiagState" "No";
BA_DEF_DEF_  "GenMsgChkConstant" 0;
BA_DEF_DEF_  "GenMsgCycleTime" 0;
BA_DEF_DEF_  "GenMsgCycleTimeFast" 0;
BA_DEF_DEF_  "GenMsgDelayTime" 0;
BA_DEF_DEF_  "GenMsgILSupport" "No";
BA_DEF_DEF_  "GenMsgNrOfRepetition" 0;
BA_DEF_DEF_  "GenMsgPDUConstants" "";
BA_DEF_DEF_  "GenMsgSendType" "NoMsgSendType";
BA_DEF_DEF_  "GenMsgStartDelayTime" 0;
BA_DEF_DEF_  "NmMessage" "No";
BA_DEF_DEF_  "NmhMessage" "No";
BA_DEF_DEF_  "MsgType" "Application";
BA_DEF_DEF_  "VAGTP20_API" 0;
BA_DEF_DEF_  "VAGTP20_DynConnection" "No";
BA_DEF_DEF_  "VAGTP20_DynSetup" "No";
BA_DEF_DEF_  "VAGTP20_StatConnection" "No";
BA_DEF_DEF_  "GenSigActiveRepetitions" 0;
BA_DEF_DEF_  "GenSigInactiveValue" 0;
BA_DEF_DEF_  "GenSigSendType" "NoSigSendType";
BA_DEF_DEF_  "GenSigStartValue" 0;
BA_DEF_DEF_  "NWM-WakeupAllowed" "No";
BA_DEF_DEF_  "GenSigFuncType" "NoFunction";
BA_DEF_DEF_  "GenSigSwitchedByIgnition" "Yes";
BA_DEF_DEF_  "Fehlerwert" 0;
BA_DEF_DEF_  "GenSigMissingSourceValue" 0;
BA_ "GenMsgCycleTime" BO_ 795 40;
BA_ "GenMsgILSupport" BO_ 795 1;
BA_ "GenMsgPDUConstants" BO_ 795 "0x67,0x8a,0xae,0x22,0x4d,0xd0,0x51,0x80,0x5c,0xb9,0xce,0x1e,0xdf,0x02,0x2d,0xd4";
BA_ "GenMsgSendType" BO_ 795 0;
BA_ "GenMsgCycleTime" BO_ 508 200;
BA_ "GenMsgDelayTime" BO_ 508 20;
BA_ "GenMsgILSupport" BO_ 508 1;
BA_ "GenMsgPDUConstants" BO_ 508 "0x01,0x10,0x05,0xde,0xe0,0xdc,0x34,0xc4,0x8a,0xb1,0x6d,0x7b,0x62,0xef,0x1f,0x95";
BA_ "GenMsgSendType" BO_ 508 0;
BA_ "GenMsgStartDelayTime" BO_ 508 40;
BA_ "GenMsgCycleTime" BO_ 600 400;
BA_ "GenMsgDelayTime" BO_ 600 40;
BA_ "GenMsgILSupport" BO_ 600 1;
BA_ "GenMsgPDUConstants" BO_ 600 "0xe0,0x57,0x49,0xc3,0x18,0xac,0xa6,0x0b,0x5c,0xc1,0x84,0x7b,0x04,0x98,0x73,0x20";
BA_ "GenMsgSendType" BO_ 600 0;
BA_ "GenMsgChkConstant" BO_ 264 9;
BA_ "GenMsgCycleTime" BO_ 264 50;
BA_ "GenMsgILSupport" BO_ 264 1;
BA_ "GenMsgPDUConstants" BO_ 264 "0x09,0x09,0x09,0x09,0x09,0x09,0x09,0x09,0x09,0x09,0x09,0x09,0x09,0x09,0x09,0x09";
BA_ "GenMsgSendType" BO_ 264 0;
BA_ "GenMsgCycleTime" BO_ 2527679659 320;
BA_ "GenMsgILSupport" BO_ 2527679659 1;
BA_ "GenMsgPDUConstants" BO_ 2527679659 "0x17,0xbe,0xf4,0xdd,0xd2,0x70,0x3d,0x04,0xcd,0x8a,0x28,0x06,0x4c,0x09,0x14,0x5b";
BA_ "GenMsgSendType" BO_ 2527679659 0;
BA_ "GenMsgCycleTime" BO_ 429 1000;
BA_ "GenMsgDelayTime" BO_ 429 40;
BA_ "GenMsgILSupport" BO_ 429 1;
BA_ "GenMsgPDUConstants" BO_ 429 "0x40,0x7a,0x23,0x13,0x03,0xf4,0xf8,0xe5,0x97,0xc9,0xd6,0x07,0x47,0x21,0x66,0xdd";
BA_ "GenMsgSendType" BO_ 429 0;
BA_ "GenMsgStartDelayTime" BO_ 429 65;
BA_ "GenMsgCycleTime" BO_ 2527679658 320;
BA_ "GenMsgILSupport" BO_ 2527679658 1;
BA_ "GenMsgSendType" BO_ 2527679658 0;
BA_ "GenMsgCycleTime" BO_ 2527679896 320;
BA_ "GenMsgILSupport" BO_ 2527679896 1;
BA_ "GenMsgPDUConstants" BO_ 2527679896 "0x7a,0xdd,0x42,0x9a,0x9f,0x9d,0x28,0xf7,0x16,0x78,0x96,0x86,0x87,0x6e,0x7c,0xaf";
BA_ "GenMsgSendType" BO_ 2527679896 0;
BA_ "GenMsgCycleTime" BO_ 2331595995 50;
BA_ "GenMsgILSupport" BO_ 2331595995 1;
BA_ "GenMsgSendType" BO_ 2331595995 0;
BA_ "GenMsgCycleTime" BO_ 705 80;
BA_ "GenMsgILSupport" BO_ 705 1;
BA_ "GenMsgPDUConstants" BO_ 705 "0x96,0x12,0x1e,0xcd,0x2f,0x45,0xec,0xcb,0xd1,0x39,0x04,0x7c,0xb7,0x29,0x37,0x47";
BA_ "GenMsgSendType" BO_ 705 0;
BA_ "GenMsgCycleTime" BO_ 2463978619 960;
BA_ "GenMsgCycleTimeFast" BO_ 2463978619 40;
BA_ "GenMsgDelayTime" BO_ 2463978619 40;
BA_ "GenMsgILSupport" BO_ 2463978619 1;
BA_ "GenMsgNrOfRepetition" BO_ 2463978619 10;
BA_ "GenMsgSendType" BO_ 2463978619 0;
BA_ "GenMsgCycleTime" BO_ 2527679660 320;
BA_ "GenMsgILSupport" BO_ 2527679660 1;
BA_ "GenMsgSendType" BO_ 2527679660 0;
BA_ "GenMsgStartDelayTime" BO_ 2527679660 250;
BA_ "GenMsgCycleTime" BO_ 707 80;
BA_ "GenMsgILSupport" BO_ 707 1;
BA_ "GenMsgPDUConstants" BO_ 707 "0x4e,0xc0,0xa1,0x90,0xc4,0xb0,0xe7,0x7d,0xdb,0x1e,0x6f,0x69,0xac,0x73,0x9c,0x17";
BA_ "GenMsgSendType" BO_ 707 0;
BA_ "GenMsgCycleTime" BO_ 1605 1000;
BA_ "GenMsgDelayTime" BO_ 1605 20;
BA_ "GenMsgILSupport" BO_ 1605 1;
BA_ "GenMsgSendType" BO_ 1605 0;
BA_ "GenMsgCycleTime" BO_ 2589283684 960;
BA_ "GenMsgDelayTime" BO_ 2589283684 320;
BA_ "GenMsgILSupport" BO_ 2589283684 1;
BA_ "GenMsgSendType" BO_ 2589283684 0;
BA_ "GenMsgStartDelayTime" BO_ 2589283684 320;
BA_ "GenMsgILSupport" BO_ 2549875571 1;
BA_ "MsgType" BO_ 2549875571 4;
BA_ "GenMsgILSupport" BO_ 2550006643 1;
BA_ "MsgType" BO_ 2550006643 4;
BA_ "GenMsgCycleTime" BO_ 173 1000;
BA_ "GenMsgDelayTime" BO_ 173 10;
BA_ "GenMsgILSupport" BO_ 173 1;
BA_ "GenMsgPDUConstants" BO_ 173 "0x3f,0x69,0x39,0xdc,0x94,0xf9,0x14,0x64,0xd8,0x6a,0x34,0xce,0xa2,0x55,0xb5,0x2c";
BA_ "GenMsgSendType" BO_ 173 0;
BA_ "GenMsgCycleTime" BO_ 968 200;
BA_ "GenMsgILSupport" BO_ 968 1;
BA_ "GenMsgSendType" BO_ 968 0;
BA_ "GenMsgCycleTime" BO_ 177 500;
BA_ "GenMsgDelayTime" BO_ 177 10;
BA_ "GenMsgILSupport" BO_ 177 1;
BA_ "GenMsgPDUConstants" BO_ 177 "0xe1,0x9e,0xc2,0xe9,0x48,0x98,0xf5,0xb6,0x47,0x83,0x26,0x45,0x9a,0x10,0x7b,0x1c";
BA_ "GenMsgSendType" BO_ 177 0;
BA_ "GenMsgStartDelayTime" BO_ 177 270;
BA_ "GenMsgCycleTime" BO_ 879 1000;
BA_ "GenMsgILSupport" BO_ 879 1;
BA_ "GenMsgSendType" BO_ 879 0;
BA_ "GenMsgCycleTime" BO_ 884 1000;
BA_ "GenMsgILSupport" BO_ 884 1;
BA_ "GenMsgSendType" BO_ 884 0;
BA_ "GenMsgCycleTime" BO_ 886 1000;
BA_ "GenMsgILSupport" BO_ 886 1;
BA_ "GenMsgSendType" BO_ 886 0;
BA_ "GenMsgCycleTime" BO_ 888 1000;
BA_ "GenMsgILSupport" BO_ 888 1;
BA_ "GenMsgSendType" BO_ 888 0;
BA_ "GenMsgCycleTime" BO_ 891 1000;
BA_ "GenMsgILSupport" BO_ 891 1;
BA_ "GenMsgSendType" BO_ 891 0;
BA_ "GenMsgCycleTime" BO_ 1364 1000;
BA_ "GenMsgILSupport" BO_ 1364 1;
BA_ "GenMsgSendType" BO_ 1364 0;
BA_ "GenMsgCycleTime" BO_ 299 200;
BA_ "GenMsgDelayTime" BO_ 299 20;
BA_ "GenMsgILSupport" BO_ 299 1;
BA_ "GenMsgPDUConstants" BO_ 299 "0x6a,0x38,0xb4,0x27,0x22,0xef,0xe1,0xbb,0xf8,0x80,0x84,0x49,0xc7,0x9e,0x1e,0x2b";
BA_ "GenMsgSendType" BO_ 299 0;
BA_ "GenMsgStartDelayTime" BO_ 299 40;
BA_ "GenMsgChkConstant" BO_ 310 55;
BA_ "GenMsgCycleTime" BO_ 310 100;
BA_ "GenMsgDelayTime" BO_ 310 10;
BA_ "GenMsgILSupport" BO_ 310 1;
BA_ "GenMsgPDUConstants" BO_ 310 "0x37,0x37,0x37,0x37,0x37,0x37,0x37,0x37,0x37,0x37,0x37,0x37,0x37,0x37,0x37,0x37";
BA_ "GenMsgSendType" BO_ 310 0;
BA_ "GenMsgCycleTime" BO_ 1410 200;
BA_ "GenMsgDelayTime" BO_ 1410 20;
BA_ "GenMsgILSupport" BO_ 1410 1;
BA_ "GenMsgSendType" BO_ 1410 0;
BA_ "GenMsgStartDelayTime" BO_ 1410 290;
BA_ "GenSigSendType" SG_ 795 ABS_Lampe 0;
BA_ "GenSigStartValue" SG_ 795 ABS_Lampe 1;
BA_ "GenSigSwitchedByIgnition" SG_ 795 ABS_Lampe 0;
BA_ "GenSigSendType" SG_ 795 BK_Lampe_02 0;
BA_ "GenSigStartValue" SG_ 795 BK_Lampe_02 1;
BA_ "GenSigSwitchedByIgnition" SG_ 795 BK_Lampe_02 0;
BA_ "GenSigSendType" SG_ 795 ESP_24_BZ 0;
BA_ "GenSigFuncType" SG_ 795 ESP_24_BZ 1;
BA_ "GenSigSwitchedByIgnition" SG_ 795 ESP_24_BZ 0;
BA_ "GenSigSendType" SG_ 795 ESP_24_CRC 0;
BA_ "GenSigFuncType" SG_ 795 ESP_24_CRC 2;
BA_ "GenSigSwitchedByIgnition" SG_ 795 ESP_24_CRC 0;
BA_ "GenSigSendType" SG_ 795 ESP_BKV_Warnung 0;
BA_ "GenSigSwitchedByIgnition" SG_ 795 ESP_BKV_Warnung 0;
BA_ "GenSigSendType" SG_ 795 ESP_Fehlerstatus_Wegimp 0;
BA_ "GenSigSwitchedByIgnition" SG_ 795 ESP_Fehlerstatus_Wegimp 0;
BA_ "GenSigSendType" SG_ 795 ESP_HDC_Geschw_Farbe 0;
BA_ "GenSigSwitchedByIgnition" SG_ 795 ESP_HDC_Geschw_Farbe 0;
BA_ "GenSigSendType" SG_ 795 ESP_HDC_Regelgeschw 0;
BA_ "GenSigStartValue" SG_ 795 ESP_HDC_Regelgeschw 126;
BA_ "GenSigSwitchedByIgnition" SG_ 795 ESP_HDC_Regelgeschw 0;
BA_ "Fehlerwert" SG_ 795 ESP_HDC_Regelgeschw 127;
BA_ "GenSigSendType" SG_ 795 ESP_Lampe 0;
BA_ "GenSigStartValue" SG_ 795 ESP_Lampe 1;
BA_ "GenSigSwitchedByIgnition" SG_ 795 ESP_Lampe 0;
BA_ "GenSigSendType" SG_ 795 ESP_m_Raddrehz 0;
BA_ "GenSigStartValue" SG_ 795 ESP_m_Raddrehz 32766;
BA_ "GenSigSwitchedByIgnition" SG_ 795 ESP_m_Raddrehz 0;
BA_ "Fehlerwert" SG_ 795 ESP_m_Raddrehz 32767;
BA_ "GenSigSendType" SG_ 795 ESP_Meldungen 0;
BA_ "GenSigSwitchedByIgnition" SG_ 795 ESP_Meldungen 0;
BA_ "GenSigSendType" SG_ 795 ESP_Off_Lampe 0;
BA_ "GenSigSwitchedByIgnition" SG_ 795 ESP_Off_Lampe 0;
BA_ "GenSigSendType" SG_ 795 ESP_QBit_Wegimp_VA 0;
BA_ "GenSigStartValue" SG_ 795 ESP_QBit_Wegimp_VA 1;
BA_ "GenSigSwitchedByIgnition" SG_ 795 ESP_QBit_Wegimp_VA 0;
BA_ "GenSigSendType" SG_ 795 ESP_Textanzeigen_03 0;
BA_ "GenSigSwitchedByIgnition" SG_ 795 ESP_Textanzeigen_03 0;
BA_ "GenSigSendType" SG_ 795 ESP_Wegimp_Ueberlauf 0;
BA_ "GenSigSwitchedByIgnition" SG_ 795 ESP_Wegimp_Ueberlauf 0;
BA_ "GenSigSendType" SG_ 795 ESP_Wegimp_VA 0;
BA_ "GenSigSwitchedByIgnition" SG_ 795 ESP_Wegimp_VA 0;
BA_ "GenSigSendType" SG_ 795 TC_Lampe 0;
BA_ "GenSigSwitchedByIgnition" SG_ 795 TC_Lampe 0;
BA_ "GenSigSendType" SG_ 508 ESC_Anforderung_Airbrake 0;
BA_ "GenSigSwitchedByIgnition" SG_ 508 ESC_Anforderung_Airbrake 0;
BA_ "GenSigSendType" SG_ 508 ESC_FBA_Meldungen 3;
BA_ "GenSigSwitchedByIgnition" SG_ 508 ESC_FBA_Meldungen 0;
BA_ "GenSigSendType" SG_ 508 ESC_MBK_Meldungen 3;
BA_ "GenSigSwitchedByIgnition" SG_ 508 ESC_MBK_Meldungen 0;
BA_ "GenSigSendType" SG_ 508 ESC_Motorstartverzoegerung 0;
BA_ "GenSigSwitchedByIgnition" SG_ 508 ESC_Motorstartverzoegerung 0;
BA_ "GenSigSendType" SG_ 508 ESP_32_BZ 0;
BA_ "GenSigFuncType" SG_ 508 ESP_32_BZ 1;
BA_ "GenSigSwitchedByIgnition" SG_ 508 ESP_32_BZ 0;
BA_ "GenSigSendType" SG_ 508 ESP_32_CRC 0;
BA_ "GenSigFuncType" SG_ 508 ESP_32_CRC 2;
BA_ "GenSigSwitchedByIgnition" SG_ 508 ESP_32_CRC 0;
BA_ "GenSigSendType" SG_ 508 ESP_Aggregataktivitaet 0;
BA_ "GenSigSwitchedByIgnition" SG_ 508 ESP_Aggregataktivitaet 0;
BA_ "GenSigSendType" SG_ 508 ESP_AVH_LED 0;
BA_ "GenSigStartValue" SG_ 508 ESP_AVH_LED 6;
BA_ "GenSigSwitchedByIgnition" SG_ 508 ESP_AVH_LED 0;
BA_ "GenSigSendType" SG_ 508 ESP_EDS_Anzeige 3;
BA_ "GenSigSwitchedByIgnition" SG_ 508 ESP_EDS_Anzeige 0;
BA_ "GenSigSendType" SG_ 508 ESP_HDC_LED 0;
BA_ "GenSigStartValue" SG_ 508 ESP_HDC_LED 6;
BA_ "GenSigSwitchedByIgnition" SG_ 508 ESP_HDC_LED 0;
BA_ "GenSigSendType" SG_ 508 ESP_HDC_Textanzeigen 3;
BA_ "GenSigSwitchedByIgnition" SG_ 508 ESP_HDC_Textanzeigen 0;
BA_ "GenSigSendType" SG_ 508 ESP_HOLD_verf 0;
BA_ "GenSigSwitchedByIgnition" SG_ 508 ESP_HOLD_verf 0;
BA_ "GenSigSendType" SG_ 508 ESP_Notbremsanzeige 0;
BA_ "GenSigSwitchedByIgnition" SG_ 508 ESP_Notbremsanzeige 0;
BA_ "GenSigSendType" SG_ 508 ESP_Off_LED 0;
BA_ "GenSigStartValue" SG_ 508 ESP_Off_LED 6;
BA_ "GenSigSwitchedByIgnition" SG_ 508 ESP_Off_LED 0;
BA_ "GenSigSendType" SG_ 508 ESP_Offroad_Lampe 0;
BA_ "GenSigSwitchedByIgnition" SG_ 508 ESP_Offroad_Lampe 0;
BA_ "GenSigSendType" SG_ 508 ESP_Rollover_Status_dyn 0;
BA_ "GenSigSwitchedByIgnition" SG_ 508 ESP_Rollover_Status_dyn 0;
BA_ "GenSigSendType" SG_ 508 ESP_Rollover_Status_stat 0;
BA_ "GenSigSwitchedByIgnition" SG_ 508 ESP_Rollover_Status_stat 0;
BA_ "GenSigSendType" SG_ 508 ESP_Status_Bremsentemp_02 0;
BA_ "GenSigSwitchedByIgnition" SG_ 508 ESP_Status_Bremsentemp_02 0;
BA_ "GenSigSendType" SG_ 508 ESP_Stillstandsflag 0;
BA_ "GenSigSwitchedByIgnition" SG_ 508 ESP_Stillstandsflag 0;
BA_ "GenSigSendType" SG_ 508 ESP_Wiederstart_Anz_Std 3;
BA_ "GenSigSwitchedByIgnition" SG_ 508 ESP_Wiederstart_Anz_Std 0;
BA_ "GenSigSendType" SG_ 508 RLE_Anzeigen 3;
BA_ "GenSigSwitchedByIgnition" SG_ 508 RLE_Anzeigen 0;
BA_ "GenSigSendType" SG_ 600 ESP_54_BZ 0;
BA_ "GenSigFuncType" SG_ 600 ESP_54_BZ 1;
BA_ "GenSigSwitchedByIgnition" SG_ 600 ESP_54_BZ 0;
BA_ "GenSigSendType" SG_ 600 ESP_54_CRC 0;
BA_ "GenSigFuncType" SG_ 600 ESP_54_CRC 2;
BA_ "GenSigSwitchedByIgnition" SG_ 600 ESP_54_CRC 0;
BA_ "GenSigSendType" SG_ 600 ESP_DriftGong 3;
BA_ "GenSigSwitchedByIgnition" SG_ 600 ESP_DriftGong 0;
BA_ "GenSigSendType" SG_ 600 ESP_DriftLevel 3;
BA_ "GenSigSendType" SG_ 600 ESP_DriftStatus 3;
BA_ "GenSigSendType" SG_ 600 ESP_DriftText 3;
BA_ "GenSigSendType" SG_ 600 ESP_Slider_Gong 3;
BA_ "GenSigSwitchedByIgnition" SG_ 600 ESP_Slider_Gong 0;
BA_ "GenSigSendType" SG_ 600 ESP_Slider_ist_01 3;
BA_ "GenSigStartValue" SG_ 600 ESP_Slider_ist_01 127;
BA_ "GenSigSendType" SG_ 600 ESP_Slider_ist_02 3;
BA_ "GenSigStartValue" SG_ 600 ESP_Slider_ist_02 127;
BA_ "GenSigSendType" SG_ 600 ESP_Slider_ist_03 3;
BA_ "GenSigStartValue" SG_ 600 ESP_Slider_ist_03 127;
BA_ "GenSigSendType" SG_ 600 ESP_Slider_Lamp 3;
BA_ "GenSigSendType" SG_ 600 ESP_Slider_Status 3;
BA_ "GenSigSendType" SG_ 600 ESP_Slider_Text 3;
BA_ "GenSigSendType" SG_ 264 EFP_Anf_Bremsenkuehlung 0;
BA_ "GenSigSwitchedByIgnition" SG_ 264 EFP_Anf_Bremsenkuehlung 0;
BA_ "GenSigSendType" SG_ 264 EFP_Reibwert_dyn 0;
BA_ "GenSigStartValue" SG_ 264 EFP_Reibwert_dyn 62;
BA_ "GenSigSwitchedByIgnition" SG_ 264 EFP_Reibwert_dyn 0;
BA_ "Fehlerwert" SG_ 264 EFP_Reibwert_dyn 63;
BA_ "GenSigSendType" SG_ 264 FA_Fahrbahnunebenheit 0;
BA_ "GenSigStartValue" SG_ 264 FA_Fahrbahnunebenheit 254;
BA_ "GenSigSwitchedByIgnition" SG_ 264 FA_Fahrbahnunebenheit 0;
BA_ "Fehlerwert" SG_ 264 FA_Fahrbahnunebenheit 255;
BA_ "GenSigSendType" SG_ 264 FA_Hoehenwert_HL_00 0;
BA_ "GenSigStartValue" SG_ 264 FA_Hoehenwert_HL_00 254;
BA_ "Fehlerwert" SG_ 264 FA_Hoehenwert_HL_00 255;
BA_ "GenSigSendType" SG_ 264 FA_Hoehenwert_HR_00 0;
BA_ "GenSigStartValue" SG_ 264 FA_Hoehenwert_HR_00 254;
BA_ "Fehlerwert" SG_ 264 FA_Hoehenwert_HR_00 255;
BA_ "GenSigSendType" SG_ 264 FA_Hoehenwert_VL_00 0;
BA_ "GenSigStartValue" SG_ 264 FA_Hoehenwert_VL_00 254;
BA_ "Fehlerwert" SG_ 264 FA_Hoehenwert_VL_00 255;
BA_ "GenSigSendType" SG_ 264 FA_Hoehenwert_VR_00 0;
BA_ "GenSigStartValue" SG_ 264 FA_Hoehenwert_VR_00 254;
BA_ "Fehlerwert" SG_ 264 FA_Hoehenwert_VR_00 255;
BA_ "GenSigSendType" SG_ 264 FA_Hoehenwerte_kalibriert 0;
BA_ "GenSigSendType" SG_ 264 Fahrwerk_01_BZ 0;
BA_ "GenSigFuncType" SG_ 264 Fahrwerk_01_BZ 1;
BA_ "GenSigSendType" SG_ 264 Fahrwerk_01_CRC 0;
BA_ "GenSigFuncType" SG_ 264 Fahrwerk_01_CRC 2;
BA_ "GenSigSendType" SG_ 2527679659 FA_Niveau_Druck_HL 0;
BA_ "GenSigStartValue" SG_ 2527679659 FA_Niveau_Druck_HL 254;
BA_ "GenSigSwitchedByIgnition" SG_ 2527679659 FA_Niveau_Druck_HL 0;
BA_ "Fehlerwert" SG_ 2527679659 FA_Niveau_Druck_HL 255;
BA_ "GenSigSendType" SG_ 2527679659 FA_Niveau_Druck_HR 0;
BA_ "GenSigStartValue" SG_ 2527679659 FA_Niveau_Druck_HR 254;
BA_ "GenSigSwitchedByIgnition" SG_ 2527679659 FA_Niveau_Druck_HR 0;
BA_ "Fehlerwert" SG_ 2527679659 FA_Niveau_Druck_HR 255;
BA_ "GenSigSendType" SG_ 2527679659 FA_Niveau_Druck_VL 0;
BA_ "GenSigStartValue" SG_ 2527679659 FA_Niveau_Druck_VL 254;
BA_ "GenSigSwitchedByIgnition" SG_ 2527679659 FA_Niveau_Druck_VL 0;
BA_ "Fehlerwert" SG_ 2527679659 FA_Niveau_Druck_VL 255;
BA_ "GenSigSendType" SG_ 2527679659 FA_Niveau_Druck_VR 0;
BA_ "GenSigStartValue" SG_ 2527679659 FA_Niveau_Druck_VR 254;
BA_ "GenSigSwitchedByIgnition" SG_ 2527679659 FA_Niveau_Druck_VR 0;
BA_ "Fehlerwert" SG_ 2527679659 FA_Niveau_Druck_VR 255;
BA_ "GenSigSendType" SG_ 429 EFP_Soll_FahrPr_HAL 0;
BA_ "GenSigSwitchedByIgnition" SG_ 429 EFP_Soll_FahrPr_HAL 0;
BA_ "GenSigSendType" SG_ 429 FA_Absenkung_Fahrzeug 0;
BA_ "GenSigSwitchedByIgnition" SG_ 429 FA_Absenkung_Fahrzeug 0;
BA_ "GenSigSendType" SG_ 429 FA_Anhaengerstatus_intern 0;
BA_ "GenSigSwitchedByIgnition" SG_ 429 FA_Anhaengerstatus_intern 0;
BA_ "GenSigSendType" SG_ 429 FA_Anhebung_Fahrzeug 0;
BA_ "GenSigSwitchedByIgnition" SG_ 429 FA_Anhebung_Fahrzeug 0;
BA_ "GenSigSendType" SG_ 429 FA_Druckspeicher_verfuegbar 0;
BA_ "GenSigSwitchedByIgnition" SG_ 429 FA_Druckspeicher_verfuegbar 0;
BA_ "GenSigSendType" SG_ 429 FA_ESP_Zuschaltung 0;
BA_ "GenSigSendType" SG_ 429 FA_HAL_Abschaltung 0;
BA_ "GenSigSwitchedByIgnition" SG_ 429 FA_HAL_Abschaltung 0;
BA_ "GenSigSendType" SG_ 429 FA_Kompressor_laeuft 0;
BA_ "GenSigSwitchedByIgnition" SG_ 429 FA_Kompressor_laeuft 0;
BA_ "GenSigSendType" SG_ 429 FA_Kompressor_laeuft_in_Kuerze 0;
BA_ "GenSigSwitchedByIgnition" SG_ 429 FA_Kompressor_laeuft_in_Kuerze 0;
BA_ "GenSigSendType" SG_ 429 FA_Signal_Drucksensor 0;
BA_ "GenSigStartValue" SG_ 429 FA_Signal_Drucksensor 254;
BA_ "GenSigSwitchedByIgnition" SG_ 429 FA_Signal_Drucksensor 0;
BA_ "Fehlerwert" SG_ 429 FA_Signal_Drucksensor 255;
BA_ "GenSigSendType" SG_ 429 FA_Systemstatus 0;
BA_ "GenSigSwitchedByIgnition" SG_ 429 FA_Systemstatus 0;
BA_ "GenSigSendType" SG_ 429 FA_Verstellung_aktiv 0;
BA_ "GenSigSwitchedByIgnition" SG_ 429 FA_Verstellung_aktiv 0;
BA_ "GenSigSendType" SG_ 429 FA_Verstellung_in_Kuerze 0;
BA_ "GenSigSwitchedByIgnition" SG_ 429 FA_Verstellung_in_Kuerze 0;
BA_ "GenSigSendType" SG_ 429 FA_Zwischenniveau 0;
BA_ "GenSigSwitchedByIgnition" SG_ 429 FA_Zwischenniveau 0;
BA_ "GenSigSendType" SG_ 429 Fahrwerk_06_BZ 0;
BA_ "GenSigFuncType" SG_ 429 Fahrwerk_06_BZ 1;
BA_ "GenSigSwitchedByIgnition" SG_ 429 Fahrwerk_06_BZ 0;
BA_ "GenSigSendType" SG_ 429 Fahrwerk_06_CRC 0;
BA_ "GenSigFuncType" SG_ 429 Fahrwerk_06_CRC 2;
BA_ "GenSigSwitchedByIgnition" SG_ 429 Fahrwerk_06_CRC 0;
BA_ "GenSigSendType" SG_ 429 NR_Anforderung_v_Begrenzung 0;
BA_ "GenSigSwitchedByIgnition" SG_ 429 NR_Anforderung_v_Begrenzung 0;
BA_ "GenSigSendType" SG_ 429 NR_Kompressor_Strom_02 0;
BA_ "Fehlerwert" SG_ 429 NR_Kompressor_Strom_02 255;
BA_ "GenSigSendType" SG_ 429 NR_Kompressor_Temp_Zylinderkopf 0;
BA_ "GenSigStartValue" SG_ 429 NR_Kompressor_Temp_Zylinderkopf 254;
BA_ "Fehlerwert" SG_ 429 NR_Kompressor_Temp_Zylinderkopf 255;
BA_ "GenSigSendType" SG_ 429 NR_LED_BN 3;
BA_ "GenSigSwitchedByIgnition" SG_ 429 NR_LED_BN 0;
BA_ "GenSigSendType" SG_ 429 NR_LED_HN 3;
BA_ "GenSigSwitchedByIgnition" SG_ 429 NR_LED_HN 0;
BA_ "GenSigSendType" SG_ 429 NR_LED_SGN 3;
BA_ "GenSigSwitchedByIgnition" SG_ 429 NR_LED_SGN 0;
BA_ "GenSigSendType" SG_ 429 NR_LED_TN 3;
BA_ "GenSigSwitchedByIgnition" SG_ 429 NR_LED_TN 0;
BA_ "GenSigSendType" SG_ 429 NR_Reglerstatus 3;
BA_ "GenSigSwitchedByIgnition" SG_ 429 NR_Reglerstatus 0;
BA_ "GenSigSendType" SG_ 2527679658 EFP_ReifenTemp_HL 0;
BA_ "GenSigStartValue" SG_ 2527679658 EFP_ReifenTemp_HL 63;
BA_ "GenSigSwitchedByIgnition" SG_ 2527679658 EFP_ReifenTemp_HL 0;
BA_ "GenSigSendType" SG_ 2527679658 EFP_ReifenTemp_HR 0;
BA_ "GenSigStartValue" SG_ 2527679658 EFP_ReifenTemp_HR 63;
BA_ "GenSigSwitchedByIgnition" SG_ 2527679658 EFP_ReifenTemp_HR 0;
BA_ "GenSigSendType" SG_ 2527679658 EFP_ReifenTemp_VL 0;
BA_ "GenSigStartValue" SG_ 2527679658 EFP_ReifenTemp_VL 63;
BA_ "GenSigSwitchedByIgnition" SG_ 2527679658 EFP_ReifenTemp_VL 0;
BA_ "GenSigSendType" SG_ 2527679658 EFP_ReifenTemp_VR 0;
BA_ "GenSigStartValue" SG_ 2527679658 EFP_ReifenTemp_VR 63;
BA_ "GenSigSwitchedByIgnition" SG_ 2527679658 EFP_ReifenTemp_VR 0;
BA_ "GenSigSendType" SG_ 2527679658 FA_Beladung_HA 0;
BA_ "GenSigStartValue" SG_ 2527679658 FA_Beladung_HA 14;
BA_ "GenSigSwitchedByIgnition" SG_ 2527679658 FA_Beladung_HA 0;
BA_ "Fehlerwert" SG_ 2527679658 FA_Beladung_HA 15;
BA_ "GenSigSendType" SG_ 2527679658 FA_Beladung_VA 0;
BA_ "GenSigStartValue" SG_ 2527679658 FA_Beladung_VA 14;
BA_ "GenSigSwitchedByIgnition" SG_ 2527679658 FA_Beladung_VA 0;
BA_ "Fehlerwert" SG_ 2527679658 FA_Beladung_VA 15;
BA_ "GenSigSendType" SG_ 2527679658 FA_FahrerAnf_Fahrwerk 0;
BA_ "GenSigSwitchedByIgnition" SG_ 2527679658 FA_FahrerAnf_Fahrwerk 0;
BA_ "GenSigSendType" SG_ 2527679658 FA_FahrerAnf_Lift 0;
BA_ "GenSigSwitchedByIgnition" SG_ 2527679658 FA_FahrerAnf_Lift 0;
BA_ "GenSigSendType" SG_ 2527679658 FA_FahrerAnf_Niveau 0;
BA_ "GenSigSwitchedByIgnition" SG_ 2527679658 FA_FahrerAnf_Niveau 0;
BA_ "GenSigSendType" SG_ 2527679896 EFP_ReifenTempOf_HL 0;
BA_ "GenSigStartValue" SG_ 2527679896 EFP_ReifenTempOf_HL 63;
BA_ "GenSigSwitchedByIgnition" SG_ 2527679896 EFP_ReifenTempOf_HL 0;
BA_ "GenSigSendType" SG_ 2527679896 EFP_ReifenTempOf_HR 0;
BA_ "GenSigStartValue" SG_ 2527679896 EFP_ReifenTempOf_HR 63;
BA_ "GenSigSwitchedByIgnition" SG_ 2527679896 EFP_ReifenTempOf_HR 0;
BA_ "GenSigSendType" SG_ 2527679896 EFP_ReifenTempOf_VL 0;
BA_ "GenSigStartValue" SG_ 2527679896 EFP_ReifenTempOf_VL 63;
BA_ "GenSigSwitchedByIgnition" SG_ 2527679896 EFP_ReifenTempOf_VL 0;
BA_ "GenSigSendType" SG_ 2527679896 EFP_ReifenTempOf_VR 0;
BA_ "GenSigStartValue" SG_ 2527679896 EFP_ReifenTempOf_VR 63;
BA_ "GenSigSwitchedByIgnition" SG_ 2527679896 EFP_ReifenTempOf_VR 0;
BA_ "GenSigSendType" SG_ 2527679896 FA_FahrerAnf_Lift_Abwurf 0;
BA_ "GenSigSwitchedByIgnition" SG_ 2527679896 FA_FahrerAnf_Lift_Abwurf 0;
BA_ "GenSigSendType" SG_ 2527679896 FA_Niveau_AOCCT_fehlerstatus 0;
BA_ "GenSigSwitchedByIgnition" SG_ 2527679896 FA_Niveau_AOCCT_fehlerstatus 0;
BA_ "GenSigSendType" SG_ 2527679896 FA_Niveau_AOCCT_teststatus 0;
BA_ "GenSigSwitchedByIgnition" SG_ 2527679896 FA_Niveau_AOCCT_teststatus 0;
BA_ "GenSigSendType" SG_ 2527679896 FA_Niveau_AOCCT_timer1_count 0;
BA_ "GenSigSwitchedByIgnition" SG_ 2527679896 FA_Niveau_AOCCT_timer1_count 0;
BA_ "GenSigSendType" SG_ 2527679896 FA_Niveau_AOCCT_timer1_verbaut 0;
BA_ "GenSigSwitchedByIgnition" SG_ 2527679896 FA_Niveau_AOCCT_timer1_verbaut 0;
BA_ "GenSigSendType" SG_ 2527679896 FA_Niveau_AOCCT_timer2_count 0;
BA_ "GenSigSwitchedByIgnition" SG_ 2527679896 FA_Niveau_AOCCT_timer2_count 0;
BA_ "GenSigSendType" SG_ 2527679896 FA_Niveau_AOCCT_timer2_verbaut 0;
BA_ "GenSigSwitchedByIgnition" SG_ 2527679896 FA_Niveau_AOCCT_timer2_verbaut 0;
BA_ "GenSigSendType" SG_ 2527679896 FA_Zuladung_HA 0;
BA_ "GenSigStartValue" SG_ 2527679896 FA_Zuladung_HA 62;
BA_ "GenSigSwitchedByIgnition" SG_ 2527679896 FA_Zuladung_HA 0;
BA_ "Fehlerwert" SG_ 2527679896 FA_Zuladung_HA 63;
BA_ "GenSigSendType" SG_ 2527679896 FA_Zuladung_Status_HA 0;
BA_ "GenSigSwitchedByIgnition" SG_ 2527679896 FA_Zuladung_Status_HA 0;
BA_ "GenSigSendType" SG_ 2527679896 FA_Zuladung_Status_VA 0;
BA_ "GenSigSwitchedByIgnition" SG_ 2527679896 FA_Zuladung_Status_VA 0;
BA_ "GenSigSendType" SG_ 2527679896 FA_Zuladung_VA 0;
BA_ "GenSigStartValue" SG_ 2527679896 FA_Zuladung_VA 62;
BA_ "GenSigSwitchedByIgnition" SG_ 2527679896 FA_Zuladung_VA 0;
BA_ "Fehlerwert" SG_ 2527679896 FA_Zuladung_VA 63;
BA_ "GenSigSendType" SG_ 2527679896 Fahrwerk_12_BZ 0;
BA_ "GenSigFuncType" SG_ 2527679896 Fahrwerk_12_BZ 1;
BA_ "GenSigSendType" SG_ 2527679896 Fahrwerk_12_CRC 0;
BA_ "GenSigFuncType" SG_ 2527679896 Fahrwerk_12_CRC 2;
BA_ "GenSigSendType" SG_ 2331595995 EFP_FVertDisp_HL 0;
BA_ "GenSigStartValue" SG_ 2331595995 EFP_FVertDisp_HL 254;
BA_ "GenSigSwitchedByIgnition" SG_ 2331595995 EFP_FVertDisp_HL 0;
BA_ "Fehlerwert" SG_ 2331595995 EFP_FVertDisp_HL 255;
BA_ "GenSigSendType" SG_ 2331595995 EFP_FVertDisp_HR 0;
BA_ "GenSigStartValue" SG_ 2331595995 EFP_FVertDisp_HR 254;
BA_ "GenSigSwitchedByIgnition" SG_ 2331595995 EFP_FVertDisp_HR 0;
BA_ "Fehlerwert" SG_ 2331595995 EFP_FVertDisp_HR 255;
BA_ "GenSigSendType" SG_ 2331595995 EFP_FVertDisp_VL 0;
BA_ "GenSigStartValue" SG_ 2331595995 EFP_FVertDisp_VL 254;
BA_ "GenSigSwitchedByIgnition" SG_ 2331595995 EFP_FVertDisp_VL 0;
BA_ "Fehlerwert" SG_ 2331595995 EFP_FVertDisp_VL 255;
BA_ "GenSigSendType" SG_ 2331595995 EFP_FVertDisp_VR 0;
BA_ "GenSigStartValue" SG_ 2331595995 EFP_FVertDisp_VR 254;
BA_ "GenSigSwitchedByIgnition" SG_ 2331595995 EFP_FVertDisp_VR 0;
BA_ "Fehlerwert" SG_ 2331595995 EFP_FVertDisp_VR 255;
BA_ "GenSigSendType" SG_ 705 DR_Warnung 0;
BA_ "GenSigSendType" SG_ 705 eABC_Texte 0;
BA_ "GenSigSendType" SG_ 705 eABC_Warnung_Prio1 0;
BA_ "GenSigSendType" SG_ 705 eABC_Warnung_Prio2 0;
BA_ "GenSigSendType" SG_ 705 eAWS_Warnmeldung_Prio1 0;
BA_ "GenSigSendType" SG_ 705 eAWS_Warnmeldung_Prio2 0;
BA_ "GenSigSendType" SG_ 705 EFP_Status_Taster_Fahrwerk 0;
BA_ "GenSigSwitchedByIgnition" SG_ 705 EFP_Status_Taster_Fahrwerk 0;
BA_ "GenSigSendType" SG_ 705 EFP_Status_Taster_Lift 0;
BA_ "GenSigSwitchedByIgnition" SG_ 705 EFP_Status_Taster_Lift 0;
BA_ "GenSigSendType" SG_ 705 EFP_Verbau_DR 0;
BA_ "GenSigSendType" SG_ 705 EFP_Verbau_eABC 0;
BA_ "GenSigSendType" SG_ 705 EFP_Verbau_eAllrad 0;
BA_ "GenSigSendType" SG_ 705 EFP_Verbau_eAWS 0;
BA_ "GenSigSendType" SG_ 705 EFP_Verbau_LF 0;
BA_ "GenSigSendType" SG_ 705 EFP_Warnung_Naesse 0;
BA_ "GenSigSwitchedByIgnition" SG_ 705 EFP_Warnung_Naesse 0;
BA_ "GenSigSendType" SG_ 705 EFP_Warnung_Naesse_verf 0;
BA_ "GenSigSwitchedByIgnition" SG_ 705 EFP_Warnung_Naesse_verf 0;
BA_ "GenSigSendType" SG_ 705 Fahrwerk_Anzeige_01_BZ 0;
BA_ "GenSigFuncType" SG_ 705 Fahrwerk_Anzeige_01_BZ 1;
BA_ "GenSigSendType" SG_ 705 Fahrwerk_Anzeige_01_CRC 0;
BA_ "GenSigFuncType" SG_ 705 Fahrwerk_Anzeige_01_CRC 2;
BA_ "GenSigSendType" SG_ 705 FDR_Warnung_ALR 0;
BA_ "GenSigSwitchedByIgnition" SG_ 705 FDR_Warnung_ALR 0;
BA_ "GenSigSendType" SG_ 705 FDR_Warnung_TV 0;
BA_ "GenSigSwitchedByIgnition" SG_ 705 FDR_Warnung_TV 0;
BA_ "GenSigSendType" SG_ 705 LF_Texte 0;
BA_ "GenSigSendType" SG_ 705 LF_Texte_2 0;
BA_ "GenSigSwitchedByIgnition" SG_ 705 LF_Texte_2 0;
BA_ "GenSigSendType" SG_ 705 LF_Warnung_Prio1 0;
BA_ "GenSigSendType" SG_ 705 LF_Warnung_Prio1_02 0;
BA_ "GenSigSendType" SG_ 705 LF_Warnung_Prio2 0;
BA_ "GenSigSendType" SG_ 705 NR_LED_Ladelevel 0;
BA_ "GenSigStartValue" SG_ 705 NR_LED_Ladelevel 3;
BA_ "GenSigSwitchedByIgnition" SG_ 705 NR_LED_Ladelevel 0;
BA_ "GenSigSendType" SG_ 705 NR_LED_Offroadlevel 0;
BA_ "GenSigStartValue" SG_ 705 NR_LED_Offroadlevel 3;
BA_ "GenSigSwitchedByIgnition" SG_ 705 NR_LED_Offroadlevel 0;
BA_ "GenSigSendType" SG_ 705 NR_LED_Strassenlevel 0;
BA_ "GenSigStartValue" SG_ 705 NR_LED_Strassenlevel 3;
BA_ "GenSigSwitchedByIgnition" SG_ 705 NR_LED_Strassenlevel 0;
BA_ "GenSigSendType" SG_ 705 NR_LED_Sync 0;
BA_ "GenSigStartValue" SG_ 705 NR_LED_Sync 3;
BA_ "GenSigSwitchedByIgnition" SG_ 705 NR_LED_Sync 0;
BA_ "GenSigSendType" SG_ 705 NR_LED_XtraLevel 0;
BA_ "GenSigStartValue" SG_ 705 NR_LED_XtraLevel 3;
BA_ "GenSigSwitchedByIgnition" SG_ 705 NR_LED_XtraLevel 0;
BA_ "GenSigSendType" SG_ 2463978619 FAS_SollStatus_Fkt_AbstWarn_LRR 3;
BA_ "GenSigSwitchedByIgnition" SG_ 2463978619 FAS_SollStatus_Fkt_AbstWarn_LRR 0;
BA_ "GenSigSendType" SG_ 2463978619 FAS_SollStatus_Fkt_AbstWarn_MV 3;
BA_ "GenSigSwitchedByIgnition" SG_ 2463978619 FAS_SollStatus_Fkt_AbstWarn_MV 0;
BA_ "GenSigSendType" SG_ 2463978619 FAS_SollStatus_Fkt_ASW 3;
BA_ "GenSigSwitchedByIgnition" SG_ 2463978619 FAS_SollStatus_Fkt_ASW 0;
BA_ "GenSigSendType" SG_ 2463978619 FAS_SollStatus_Fkt_LGI 3;
BA_ "GenSigSwitchedByIgnition" SG_ 2463978619 FAS_SollStatus_Fkt_LGI 0;
BA_ "GenSigSendType" SG_ 2463978619 FAS_SollStatus_Fkt_MKE 3;
BA_ "GenSigSwitchedByIgnition" SG_ 2463978619 FAS_SollStatus_Fkt_MKE 0;
BA_ "GenSigActiveRepetitions" SG_ 2463978619 FAS_SollStatus_Fkt_NV 10;
BA_ "GenSigSendType" SG_ 2463978619 FAS_SollStatus_Fkt_NV 4;
BA_ "GenSigSwitchedByIgnition" SG_ 2463978619 FAS_SollStatus_Fkt_NV 0;
BA_ "GenSigSendType" SG_ 2463978619 FAS_SollStatus_Fkt_PreCrash 3;
BA_ "GenSigSwitchedByIgnition" SG_ 2463978619 FAS_SollStatus_Fkt_PreCrash 0;
BA_ "GenSigSendType" SG_ 2463978619 FAS_SollStatus_Fkt_STP 3;
BA_ "GenSigSwitchedByIgnition" SG_ 2463978619 FAS_SollStatus_Fkt_STP 0;
BA_ "GenSigSendType" SG_ 2463978619 FAS_SollStatus_Fkt_SWA 3;
BA_ "GenSigSwitchedByIgnition" SG_ 2463978619 FAS_SollStatus_Fkt_SWA 0;
BA_ "GenSigSendType" SG_ 2527679660 FB_Blindheit 0;
BA_ "GenSigSendType" SG_ 2527679660 FB_Fahrerwechsel 0;
BA_ "GenSigStartValue" SG_ 2527679660 FB_Fahrerwechsel 3;
BA_ "GenSigSendType" SG_ 2527679660 FB_Fehler 0;
BA_ "Fehlerwert" SG_ 2527679660 FB_Fehler 1;
BA_ "GenSigSendType" SG_ 2527679660 FB_Kopfaktivitaet_A1 0;
BA_ "GenSigStartValue" SG_ 2527679660 FB_Kopfaktivitaet_A1 15;
BA_ "GenSigSendType" SG_ 2527679660 FB_Kopfaktivitaet_A1_Guete 0;
BA_ "GenSigSendType" SG_ 2527679660 FB_Kopfaktivitaet_A2 0;
BA_ "GenSigStartValue" SG_ 2527679660 FB_Kopfaktivitaet_A2 15;
BA_ "GenSigSendType" SG_ 2527679660 FB_Kopfaktivitaet_A2_Guete 0;
BA_ "GenSigSendType" SG_ 2527679660 FB_Muedigkeit_Guete 0;
BA_ "GenSigSendType" SG_ 2527679660 FB_Muedigkeit_Index 0;
BA_ "GenSigStartValue" SG_ 2527679660 FB_Muedigkeit_Index 255;
BA_ "GenSigSendType" SG_ 2527679660 FB_NichtVerfuegbar 0;
BA_ "GenSigStartValue" SG_ 2527679660 FB_NichtVerfuegbar 1;
BA_ "GenSigSendType" SG_ 707 eAWS_Warnmeldung_Prio3 0;
BA_ "GenSigSwitchedByIgnition" SG_ 707 eAWS_Warnmeldung_Prio3 0;
BA_ "GenSigSendType" SG_ 707 EFP_Anf_Kuehlklappenwarnung 0;
BA_ "GenSigSwitchedByIgnition" SG_ 707 EFP_Anf_Kuehlklappenwarnung 0;
BA_ "GenSigSendType" SG_ 707 EFP_MomRad_Begr 0;
BA_ "GenSigStartValue" SG_ 707 EFP_MomRad_Begr 4094;
BA_ "GenSigSwitchedByIgnition" SG_ 707 EFP_MomRad_Begr 0;
BA_ "Fehlerwert" SG_ 707 EFP_MomRad_Begr 4095;
BA_ "GenSigSendType" SG_ 707 FA_Warnung_Transportniveau 0;
BA_ "GenSigSwitchedByIgnition" SG_ 707 FA_Warnung_Transportniveau 0;
BA_ "GenSigSendType" SG_ 707 FDR_04_BZ 0;
BA_ "GenSigFuncType" SG_ 707 FDR_04_BZ 1;
BA_ "GenSigSwitchedByIgnition" SG_ 707 FDR_04_BZ 0;
BA_ "GenSigSendType" SG_ 707 FDR_04_CRC 0;
BA_ "GenSigFuncType" SG_ 707 FDR_04_CRC 2;
BA_ "GenSigSwitchedByIgnition" SG_ 707 FDR_04_CRC 0;
BA_ "GenSigSendType" SG_ 707 FDR_M_HL_02 0;
BA_ "GenSigStartValue" SG_ 707 FDR_M_HL_02 254;
BA_ "GenSigSwitchedByIgnition" SG_ 707 FDR_M_HL_02 0;
BA_ "Fehlerwert" SG_ 707 FDR_M_HL_02 255;
BA_ "GenSigSendType" SG_ 707 FDR_M_HR_02 0;
BA_ "GenSigStartValue" SG_ 707 FDR_M_HR_02 254;
BA_ "GenSigSwitchedByIgnition" SG_ 707 FDR_M_HR_02 0;
BA_ "Fehlerwert" SG_ 707 FDR_M_HR_02 255;
BA_ "GenSigSendType" SG_ 707 FDR_M_VL_02 0;
BA_ "GenSigStartValue" SG_ 707 FDR_M_VL_02 254;
BA_ "GenSigSwitchedByIgnition" SG_ 707 FDR_M_VL_02 0;
BA_ "Fehlerwert" SG_ 707 FDR_M_VL_02 255;
BA_ "GenSigSendType" SG_ 707 FDR_M_VR_02 0;
BA_ "GenSigStartValue" SG_ 707 FDR_M_VR_02 254;
BA_ "GenSigSwitchedByIgnition" SG_ 707 FDR_M_VR_02 0;
BA_ "Fehlerwert" SG_ 707 FDR_M_VR_02 255;
BA_ "GenSigSendType" SG_ 1605 FLA_Abblendursache 3;
BA_ "Fehlerwert" SG_ 1605 FLA_Abblendursache 255;
BA_ "GenSigSendType" SG_ 1605 FLA_aktiv 3;
BA_ "GenSigSendType" SG_ 1605 FLA_Aufblenden 3;
BA_ "GenSigSendType" SG_ 1605 FLA_Fernlicht_PWM 3;
BA_ "GenSigStartValue" SG_ 1605 FLA_Fernlicht_PWM 100;
BA_ "Fehlerwert" SG_ 1605 FLA_Fernlicht_PWM 127;
BA_ "GenSigSendType" SG_ 1605 FLA_ISP_defekt 3;
BA_ "GenSigSendType" SG_ 1605 FLA_SAE_Mode 3;
BA_ "GenSigSendType" SG_ 1605 FLA_Sensor_blockiert 3;
BA_ "GenSigSendType" SG_ 1605 ISP_Dimmung_ASP_02 3;
BA_ "GenSigSendType" SG_ 1605 ISP_EC_aktiv 3;
BA_ "GenSigStartValue" SG_ 1605 ISP_EC_aktiv 1;
BA_ "GenSigSendType" SG_ 1605 ISP_EC_Lichtwert_hinten 3;
BA_ "GenSigStartValue" SG_ 1605 ISP_EC_Lichtwert_hinten 62;
BA_ "Fehlerwert" SG_ 1605 ISP_EC_Lichtwert_hinten 63;
BA_ "GenSigSendType" SG_ 1605 ISP_EC_Lichtwert_vorne 3;
BA_ "GenSigStartValue" SG_ 1605 ISP_EC_Lichtwert_vorne 62;
BA_ "Fehlerwert" SG_ 1605 ISP_EC_Lichtwert_vorne 63;
BA_ "GenSigSendType" SG_ 1605 ISP_Himmelsrichtung 3;
BA_ "GenSigStartValue" SG_ 1605 ISP_Himmelsrichtung 30;
BA_ "Fehlerwert" SG_ 1605 ISP_Himmelsrichtung 31;
BA_ "GenSigSendType" SG_ 1605 ISP_Kompass_aktiv 3;
BA_ "GenSigStartValue" SG_ 1605 ISP_Kompass_aktiv 1;
BA_ "GenSigSendType" SG_ 1605 ISP_Taste_betaetigt 3;
BA_ "GenSigSendType" SG_ 2589283684 FoD_Anz_Funktionsabschaltung 3;
BA_ "GenSigSwitchedByIgnition" SG_ 2589283684 FoD_Anz_Funktionsabschaltung 0;
BA_ "GenSigSendType" SG_ 2589283684 FoD_Transmission_Info 3;
BA_ "GenSigSwitchedByIgnition" SG_ 2589283684 FoD_Transmission_Info 0;
BA_ "GenSigSendType" SG_ 2549875571 FoD_ZR_Req_Data 3;
BA_ "GenSigFuncType" SG_ 2549875571 FoD_ZR_Req_Data 9;
BA_ "GenSigSwitchedByIgnition" SG_ 2549875571 FoD_ZR_Req_Data 0;
BA_ "GenSigSendType" SG_ 2550006643 FoD_ZR_Resp_Data 3;
BA_ "GenSigFuncType" SG_ 2550006643 FoD_ZR_Resp_Data 9;
BA_ "GenSigSwitchedByIgnition" SG_ 2550006643 FoD_ZR_Resp_Data 0;
BA_ "GenSigSendType" SG_ 173 GE_Fahrstufe 3;
BA_ "GenSigStartValue" SG_ 173 GE_Fahrstufe 1;
BA_ "GenSigSwitchedByIgnition" SG_ 173 GE_Fahrstufe 0;
BA_ "Fehlerwert" SG_ 173 GE_Fahrstufe 15;
BA_ "GenSigSendType" SG_ 173 GE_Freig_MMom_Vorhalt 0;
BA_ "GenSigSwitchedByIgnition" SG_ 173 GE_Freig_MMom_Vorhalt 0;
BA_ "GenSigSendType" SG_ 173 GE_MMom_Soll_02 0;
BA_ "GenSigStartValue" SG_ 173 GE_MMom_Soll_02 1022;
BA_ "GenSigSwitchedByIgnition" SG_ 173 GE_MMom_Soll_02 0;
BA_ "Fehlerwert" SG_ 173 GE_MMom_Soll_02 1023;
BA_ "GenSigSendType" SG_ 173 GE_MMom_Status 0;
BA_ "GenSigSwitchedByIgnition" SG_ 173 GE_MMom_Status 0;
BA_ "GenSigSendType" SG_ 173 GE_MMom_Status_02 0;
BA_ "GenSigSwitchedByIgnition" SG_ 173 GE_MMom_Status_02 0;
BA_ "GenSigSendType" SG_ 173 GE_MMom_Vorhalt_02 0;
BA_ "GenSigStartValue" SG_ 173 GE_MMom_Vorhalt_02 1022;
BA_ "GenSigSwitchedByIgnition" SG_ 173 GE_MMom_Vorhalt_02 0;
BA_ "Fehlerwert" SG_ 173 GE_MMom_Vorhalt_02 1023;
BA_ "GenSigSendType" SG_ 173 GE_reserv_Fahrstufe 0;
BA_ "GenSigSwitchedByIgnition" SG_ 173 GE_reserv_Fahrstufe 0;
BA_ "GenSigSendType" SG_ 173 GE_Schaltablauf 0;
BA_ "GenSigSwitchedByIgnition" SG_ 173 GE_Schaltablauf 0;
BA_ "GenSigSendType" SG_ 173 GE_Status_Kraftschluss 0;
BA_ "GenSigSwitchedByIgnition" SG_ 173 GE_Status_Kraftschluss 0;
BA_ "GenSigSendType" SG_ 173 GE_Uefkt 0;
BA_ "GenSigSwitchedByIgnition" SG_ 173 GE_Uefkt 0;
BA_ "Fehlerwert" SG_ 173 GE_Uefkt 1023;
BA_ "GenSigSendType" SG_ 173 GE_Uefkt_unplausibel 0;
BA_ "GenSigSwitchedByIgnition" SG_ 173 GE_Uefkt_unplausibel 0;
BA_ "GenSigSendType" SG_ 173 GE_Verbot_Ausblendung 0;
BA_ "GenSigSwitchedByIgnition" SG_ 173 GE_Verbot_Ausblendung 0;
BA_ "GenSigSendType" SG_ 173 GE_Zielgang 0;
BA_ "GenSigSwitchedByIgnition" SG_ 173 GE_Zielgang 0;
BA_ "Fehlerwert" SG_ 173 GE_Zielgang 15;
BA_ "GenSigSendType" SG_ 173 Getriebe_11_BZ 0;
BA_ "GenSigFuncType" SG_ 173 Getriebe_11_BZ 1;
BA_ "GenSigSwitchedByIgnition" SG_ 173 Getriebe_11_BZ 0;
BA_ "GenSigSendType" SG_ 173 Getriebe_11_CRC 0;
BA_ "GenSigFuncType" SG_ 173 Getriebe_11_CRC 2;
BA_ "GenSigSwitchedByIgnition" SG_ 173 Getriebe_11_CRC 0;
BA_ "GenSigSendType" SG_ 968 Freilauf_Charisma_FahrPr 0;
BA_ "GenSigSwitchedByIgnition" SG_ 968 Freilauf_Charisma_FahrPr 0;
BA_ "GenSigSendType" SG_ 968 Freilauf_Charisma_Status 0;
BA_ "GenSigSwitchedByIgnition" SG_ 968 Freilauf_Charisma_Status 0;
BA_ "GenSigSendType" SG_ 968 GE_amax_moeglich 0;
BA_ "GenSigStartValue" SG_ 968 GE_amax_moeglich 84;
BA_ "GenSigSwitchedByIgnition" SG_ 968 GE_amax_moeglich 0;
BA_ "GenSigSendType" SG_ 968 GE_Charisma_FahrPr 0;
BA_ "GenSigSwitchedByIgnition" SG_ 968 GE_Charisma_FahrPr 0;
BA_ "GenSigSendType" SG_ 968 GE_Charisma_Status 0;
BA_ "GenSigSwitchedByIgnition" SG_ 968 GE_Charisma_Status 0;
BA_ "GenSigSendType" SG_ 968 GE_Codierung_MSG 0;
BA_ "GenSigSwitchedByIgnition" SG_ 968 GE_Codierung_MSG 0;
BA_ "GenSigSendType" SG_ 968 GE_Freigabe_Info_WFS 0;
BA_ "GenSigSwitchedByIgnition" SG_ 968 GE_Freigabe_Info_WFS 0;
BA_ "GenSigSendType" SG_ 968 GE_Freigabe_Verfallsinfo_WFS 0;
BA_ "GenSigSwitchedByIgnition" SG_ 968 GE_Freigabe_Verfallsinfo_WFS 0;
BA_ "GenSigSendType" SG_ 968 GE_Heizwunsch 0;
BA_ "GenSigStartValue" SG_ 968 GE_Heizwunsch 1;
BA_ "GenSigSwitchedByIgnition" SG_ 968 GE_Heizwunsch 0;
BA_ "GenSigSendType" SG_ 968 GE_LaunchControl 0;
BA_ "GenSigSwitchedByIgnition" SG_ 968 GE_LaunchControl 0;
BA_ "GenSigSendType" SG_ 968 GE_LaunchControl_LB 0;
BA_ "GenSigSwitchedByIgnition" SG_ 968 GE_LaunchControl_LB 0;
BA_ "GenSigSendType" SG_ 968 GE_LFR_Adaption 0;
BA_ "GenSigSwitchedByIgnition" SG_ 968 GE_LFR_Adaption 0;
BA_ "GenSigSendType" SG_ 968 GE_OBD_AbsperrVent 0;
BA_ "GenSigSwitchedByIgnition" SG_ 968 GE_OBD_AbsperrVent 0;
BA_ "GenSigSendType" SG_ 968 GE_OBD_Status 0;
BA_ "GenSigSwitchedByIgnition" SG_ 968 GE_OBD_Status 0;
BA_ "GenSigSendType" SG_ 968 GE_Remotestart_Betrieb 0;
BA_ "GenSigSwitchedByIgnition" SG_ 968 GE_Remotestart_Betrieb 0;
BA_ "GenSigSendType" SG_ 968 GE_Sperr_Info_WFS 0;
BA_ "GenSigSwitchedByIgnition" SG_ 968 GE_Sperr_Info_WFS 0;
BA_ "GenSigSendType" SG_ 968 GE_Status_PaddleNeutral 0;
BA_ "GenSigSwitchedByIgnition" SG_ 968 GE_Status_PaddleNeutral 0;
BA_ "GenSigSendType" SG_ 968 GE_Sumpftemperatur 0;
BA_ "GenSigSwitchedByIgnition" SG_ 968 GE_Sumpftemperatur 0;
BA_ "Fehlerwert" SG_ 968 GE_Sumpftemperatur 255;
BA_ "GenSigSendType" SG_ 968 GE_Zustand_Kuppltemp 0;
BA_ "GenSigSwitchedByIgnition" SG_ 968 GE_Zustand_Kuppltemp 0;
BA_ "GenSigSendType" SG_ 177 GE_Anschleppstart_Freigabe 0;
BA_ "GenSigSwitchedByIgnition" SG_ 177 GE_Anschleppstart_Freigabe 0;
BA_ "GenSigSendType" SG_ 177 GE_Eingangsdrehz_Praed 0;
BA_ "GenSigStartValue" SG_ 177 GE_Eingangsdrehz_Praed 16382;
BA_ "GenSigSwitchedByIgnition" SG_ 177 GE_Eingangsdrehz_Praed 0;
BA_ "Fehlerwert" SG_ 177 GE_Eingangsdrehz_Praed 16383;
BA_ "GenSigSendType" SG_ 177 GE_Fahrprogramm 0;
BA_ "GenSigSwitchedByIgnition" SG_ 177 GE_Fahrprogramm 0;
BA_ "GenSigSendType" SG_ 177 GE_Freilauf_Status 3;
BA_ "GenSigSwitchedByIgnition" SG_ 177 GE_Freilauf_Status 0;
BA_ "Fehlerwert" SG_ 177 GE_Freilauf_Status 7;
BA_ "GenSigSendType" SG_ 177 GE_Getriebestatus_02 0;
BA_ "GenSigSwitchedByIgnition" SG_ 177 GE_Getriebestatus_02 0;
BA_ "GenSigSendType" SG_ 177 GE_Grundeinstellung 0;
BA_ "GenSigSwitchedByIgnition" SG_ 177 GE_Grundeinstellung 0;
BA_ "GenSigSendType" SG_ 177 GE_KomFehler_ESP 0;
BA_ "GenSigSwitchedByIgnition" SG_ 177 GE_KomFehler_ESP 0;
BA_ "Fehlerwert" SG_ 177 GE_KomFehler_ESP 1;
BA_ "GenSigSendType" SG_ 177 GE_Rollrichtung_falsch 0;
BA_ "GenSigSwitchedByIgnition" SG_ 177 GE_Rollrichtung_falsch 0;
BA_ "GenSigSendType" SG_ 177 GE_Strombedarf_erh 0;
BA_ "GenSigSwitchedByIgnition" SG_ 177 GE_Strombedarf_erh 0;
BA_ "GenSigSendType" SG_ 177 GE_TippZustand 0;
BA_ "GenSigSwitchedByIgnition" SG_ 177 GE_TippZustand 0;
BA_ "GenSigSendType" SG_ 177 GE_Uefkt_Praed 0;
BA_ "GenSigSwitchedByIgnition" SG_ 177 GE_Uefkt_Praed 0;
BA_ "Fehlerwert" SG_ 177 GE_Uefkt_Praed 16383;
BA_ "GenSigSendType" SG_ 177 Getriebe_17_BZ 0;
BA_ "GenSigFuncType" SG_ 177 Getriebe_17_BZ 1;
BA_ "GenSigSwitchedByIgnition" SG_ 177 Getriebe_17_BZ 0;
BA_ "GenSigSendType" SG_ 177 Getriebe_17_CRC 0;
BA_ "GenSigFuncType" SG_ 177 Getriebe_17_CRC 2;
BA_ "GenSigSwitchedByIgnition" SG_ 177 Getriebe_17_CRC 0;
BA_ "GenSigSendType" SG_ 879 GNSS_Breite_Ortung 0;
BA_ "GenSigStartValue" SG_ 879 GNSS_Breite_Ortung 134217726;
BA_ "GenSigSwitchedByIgnition" SG_ 879 GNSS_Breite_Ortung 0;
BA_ "Fehlerwert" SG_ 879 GNSS_Breite_Ortung 134217727;
BA_ "GenSigSendType" SG_ 879 GNSS_Fehlerzustand 0;
BA_ "GenSigSwitchedByIgnition" SG_ 879 GNSS_Fehlerzustand 0;
BA_ "GenSigSendType" SG_ 879 GNSS_Laenge_Ortung 0;
BA_ "GenSigStartValue" SG_ 879 GNSS_Laenge_Ortung 268435454;
BA_ "GenSigSwitchedByIgnition" SG_ 879 GNSS_Laenge_Ortung 0;
BA_ "Fehlerwert" SG_ 879 GNSS_Laenge_Ortung 268435455;
BA_ "GenSigSendType" SG_ 879 GNSS_Nachrichtenpaket_ID1 0;
BA_ "GenSigSwitchedByIgnition" SG_ 879 GNSS_Nachrichtenpaket_ID1 0;
BA_ "GenSigSendType" SG_ 879 GNSS_Ortung_FIX_Typ 0;
BA_ "GenSigSwitchedByIgnition" SG_ 879 GNSS_Ortung_FIX_Typ 0;
BA_ "GenSigSendType" SG_ 879 GNSS_Richtung_Breite_Ortung 0;
BA_ "GenSigStartValue" SG_ 879 GNSS_Richtung_Breite_Ortung 1;
BA_ "GenSigSwitchedByIgnition" SG_ 879 GNSS_Richtung_Breite_Ortung 0;
BA_ "GenSigSendType" SG_ 879 GNSS_Richtung_Laenge_Ortung 0;
BA_ "GenSigStartValue" SG_ 879 GNSS_Richtung_Laenge_Ortung 1;
BA_ "GenSigSwitchedByIgnition" SG_ 879 GNSS_Richtung_Laenge_Ortung 0;
BA_ "GenSigSendType" SG_ 884 GNSS_Nachrichtenpaket_ID2 0;
BA_ "GenSigSwitchedByIgnition" SG_ 884 GNSS_Nachrichtenpaket_ID2 0;
BA_ "GenSigSendType" SG_ 884 GNSS_Ortung_2D_Geschw_ue_Grund 0;
BA_ "GenSigStartValue" SG_ 884 GNSS_Ortung_2D_Geschw_ue_Grund 510;
BA_ "GenSigSwitchedByIgnition" SG_ 884 GNSS_Ortung_2D_Geschw_ue_Grund 0;
BA_ "Fehlerwert" SG_ 884 GNSS_Ortung_2D_Geschw_ue_Grund 511;
BA_ "GenSigSendType" SG_ 884 GNSS_Ortung_Ausrichtung 0;
BA_ "GenSigStartValue" SG_ 884 GNSS_Ortung_Ausrichtung 4094;
BA_ "GenSigSwitchedByIgnition" SG_ 884 GNSS_Ortung_Ausrichtung 0;
BA_ "Fehlerwert" SG_ 884 GNSS_Ortung_Ausrichtung 4095;
BA_ "GenSigSendType" SG_ 884 GNSS_Ortung_Latenz 0;
BA_ "GenSigStartValue" SG_ 884 GNSS_Ortung_Latenz 1022;
BA_ "GenSigSwitchedByIgnition" SG_ 884 GNSS_Ortung_Latenz 0;
BA_ "Fehlerwert" SG_ 884 GNSS_Ortung_Latenz 1023;
BA_ "GenSigSendType" SG_ 884 GNSS_Ortung_Noerdliche_Geschw 0;
BA_ "GenSigStartValue" SG_ 884 GNSS_Ortung_Noerdliche_Geschw 1022;
BA_ "GenSigSwitchedByIgnition" SG_ 884 GNSS_Ortung_Noerdliche_Geschw 0;
BA_ "Fehlerwert" SG_ 884 GNSS_Ortung_Noerdliche_Geschw 1023;
BA_ "GenSigSendType" SG_ 884 GNSS_Ortung_Oestliche_Geschw 0;
BA_ "GenSigStartValue" SG_ 884 GNSS_Ortung_Oestliche_Geschw 1022;
BA_ "GenSigSwitchedByIgnition" SG_ 884 GNSS_Ortung_Oestliche_Geschw 0;
BA_ "Fehlerwert" SG_ 884 GNSS_Ortung_Oestliche_Geschw 1023;
BA_ "GenSigSendType" SG_ 884 GNSS_Ortung_Vertikale_Geschw 0;
BA_ "GenSigStartValue" SG_ 884 GNSS_Ortung_Vertikale_Geschw 1022;
BA_ "GenSigSwitchedByIgnition" SG_ 884 GNSS_Ortung_Vertikale_Geschw 0;
BA_ "Fehlerwert" SG_ 884 GNSS_Ortung_Vertikale_Geschw 1023;
BA_ "GenSigSendType" SG_ 886 GNSS_Nachrichtenpaket_ID3 0;
BA_ "GenSigSwitchedByIgnition" SG_ 886 GNSS_Nachrichtenpaket_ID3 0;
BA_ "GenSigSendType" SG_ 886 GNSS_Ortung_GDOP 0;
BA_ "GenSigStartValue" SG_ 886 GNSS_Ortung_GDOP 510;
BA_ "GenSigSwitchedByIgnition" SG_ 886 GNSS_Ortung_GDOP 0;
BA_ "Fehlerwert" SG_ 886 GNSS_Ortung_GDOP 511;
BA_ "GenSigSendType" SG_ 886 GNSS_Ortung_Guete_Ausrichtung 0;
BA_ "GenSigStartValue" SG_ 886 GNSS_Ortung_Guete_Ausrichtung 62;
BA_ "GenSigSwitchedByIgnition" SG_ 886 GNSS_Ortung_Guete_Ausrichtung 0;
BA_ "Fehlerwert" SG_ 886 GNSS_Ortung_Guete_Ausrichtung 63;
BA_ "GenSigSendType" SG_ 886 GNSS_Ortung_Guete_Geschwindigk 0;
BA_ "GenSigStartValue" SG_ 886 GNSS_Ortung_Guete_Geschwindigk 62;
BA_ "GenSigSwitchedByIgnition" SG_ 886 GNSS_Ortung_Guete_Geschwindigk 0;
BA_ "Fehlerwert" SG_ 886 GNSS_Ortung_Guete_Geschwindigk 63;
BA_ "GenSigSendType" SG_ 886 GNSS_Ortung_Guete_horizontal 0;
BA_ "GenSigStartValue" SG_ 886 GNSS_Ortung_Guete_horizontal 254;
BA_ "GenSigSwitchedByIgnition" SG_ 886 GNSS_Ortung_Guete_horizontal 0;
BA_ "Fehlerwert" SG_ 886 GNSS_Ortung_Guete_horizontal 255;
BA_ "GenSigSendType" SG_ 886 GNSS_Ortung_Guete_vertikal 0;
BA_ "GenSigStartValue" SG_ 886 GNSS_Ortung_Guete_vertikal 62;
BA_ "GenSigSwitchedByIgnition" SG_ 886 GNSS_Ortung_Guete_vertikal 0;
BA_ "Fehlerwert" SG_ 886 GNSS_Ortung_Guete_vertikal 63;
BA_ "GenSigSendType" SG_ 886 GNSS_Ortung_HDOP 0;
BA_ "GenSigStartValue" SG_ 886 GNSS_Ortung_HDOP 510;
BA_ "GenSigSwitchedByIgnition" SG_ 886 GNSS_Ortung_HDOP 0;
BA_ "Fehlerwert" SG_ 886 GNSS_Ortung_HDOP 511;
BA_ "GenSigSendType" SG_ 886 GNSS_Ortung_PDOP 0;
BA_ "GenSigStartValue" SG_ 886 GNSS_Ortung_PDOP 510;
BA_ "GenSigSwitchedByIgnition" SG_ 886 GNSS_Ortung_PDOP 0;
BA_ "Fehlerwert" SG_ 886 GNSS_Ortung_PDOP 511;
BA_ "GenSigSendType" SG_ 886 GNSS_Ortung_VDOP 0;
BA_ "GenSigStartValue" SG_ 886 GNSS_Ortung_VDOP 510;
BA_ "GenSigSwitchedByIgnition" SG_ 886 GNSS_Ortung_VDOP 0;
BA_ "Fehlerwert" SG_ 886 GNSS_Ortung_VDOP 511;
BA_ "GenSigSendType" SG_ 888 GNSS_Nachrichtenpaket_ID4 0;
BA_ "GenSigSwitchedByIgnition" SG_ 888 GNSS_Nachrichtenpaket_ID4 0;
BA_ "GenSigSendType" SG_ 888 GNSS_Ortung_Hoehe 0;
BA_ "GenSigStartValue" SG_ 888 GNSS_Ortung_Hoehe 4094;
BA_ "GenSigSwitchedByIgnition" SG_ 888 GNSS_Ortung_Hoehe 0;
BA_ "Fehlerwert" SG_ 888 GNSS_Ortung_Hoehe 4095;
BA_ "GenSigSendType" SG_ 888 GNSS_Ortung_Zeit_in_GPSWoche 0;
BA_ "GenSigStartValue" SG_ 888 GNSS_Ortung_Zeit_in_GPSWoche 1073741822;
BA_ "GenSigSwitchedByIgnition" SG_ 888 GNSS_Ortung_Zeit_in_GPSWoche 0;
BA_ "Fehlerwert" SG_ 888 GNSS_Ortung_Zeit_in_GPSWoche 1073741823;
BA_ "GenSigSendType" SG_ 891 GNSS_Empfaenger_Status 0;
BA_ "GenSigSwitchedByIgnition" SG_ 891 GNSS_Empfaenger_Status 0;
BA_ "GenSigSendType" SG_ 891 GNSS_Empfangbare_Satelliten 0;
BA_ "GenSigSwitchedByIgnition" SG_ 891 GNSS_Empfangbare_Satelliten 0;
BA_ "GenSigSendType" SG_ 891 GNSS_Genutzte_Satelliten 0;
BA_ "GenSigSwitchedByIgnition" SG_ 891 GNSS_Genutzte_Satelliten 0;
BA_ "GenSigSendType" SG_ 891 GNSS_GLONASS_in_Nutzung 0;
BA_ "GenSigSwitchedByIgnition" SG_ 891 GNSS_GLONASS_in_Nutzung 0;
BA_ "GenSigSendType" SG_ 891 GNSS_GPS_in_Nutzung 0;
BA_ "GenSigSwitchedByIgnition" SG_ 891 GNSS_GPS_in_Nutzung 0;
BA_ "GenSigSendType" SG_ 891 GNSS_Nachrichtenpaket_ID5 0;
BA_ "GenSigSwitchedByIgnition" SG_ 891 GNSS_Nachrichtenpaket_ID5 0;
BA_ "GenSigSendType" SG_ 891 GNSS_Sichtbare_Satelliten 0;
BA_ "GenSigSwitchedByIgnition" SG_ 891 GNSS_Sichtbare_Satelliten 0;
BA_ "GenSigSendType" SG_ 891 GNSS_UTC_Zeit 0;
BA_ "GenSigSwitchedByIgnition" SG_ 891 GNSS_UTC_Zeit 0;
BA_ "GenSigSendType" SG_ 1364 GNSS_Nachrichtenpaket_ID6 0;
BA_ "GenSigSwitchedByIgnition" SG_ 1364 GNSS_Nachrichtenpaket_ID6 0;
BA_ "GenSigSendType" SG_ 1364 GNSS_Sat_Info_Azimuth_ID_1 0;
BA_ "GenSigStartValue" SG_ 1364 GNSS_Sat_Info_Azimuth_ID_1 511;
BA_ "GenSigSwitchedByIgnition" SG_ 1364 GNSS_Sat_Info_Azimuth_ID_1 0;
BA_ "GenSigSendType" SG_ 1364 GNSS_Sat_Info_Hoehenwinkel_ID_1 0;
BA_ "GenSigStartValue" SG_ 1364 GNSS_Sat_Info_Hoehenwinkel_ID_1 127;
BA_ "GenSigSwitchedByIgnition" SG_ 1364 GNSS_Sat_Info_Hoehenwinkel_ID_1 0;
BA_ "GenSigSendType" SG_ 1364 GNSS_Sat_Info_Sat_ID_1 0;
BA_ "GenSigSwitchedByIgnition" SG_ 1364 GNSS_Sat_Info_Sat_ID_1 0;
BA_ "GenSigSendType" SG_ 1364 GNSS_Sat_Info_SNR_ID_1 0;
BA_ "GenSigStartValue" SG_ 1364 GNSS_Sat_Info_SNR_ID_1 31;
BA_ "GenSigSwitchedByIgnition" SG_ 1364 GNSS_Sat_Info_SNR_ID_1 0;
BA_ "GenSigSendType" SG_ 299 GRA_Abbrechen 0;
BA_ "GenSigSendType" SG_ 299 GRA_ACC_01_BZ 0;
BA_ "GenSigFuncType" SG_ 299 GRA_ACC_01_BZ 1;
BA_ "GenSigSendType" SG_ 299 GRA_ACC_01_CRC 0;
BA_ "GenSigFuncType" SG_ 299 GRA_ACC_01_CRC 2;
BA_ "GenSigSendType" SG_ 299 GRA_Codierung 0;
BA_ "GenSigSendType" SG_ 299 GRA_Fehler 0;
BA_ "Fehlerwert" SG_ 299 GRA_Fehler 1;
BA_ "GenSigSendType" SG_ 299 GRA_Hauptschalter 3;
BA_ "GenSigSendType" SG_ 299 GRA_LIM_Taste_verfuegbar 0;
BA_ "GenSigFuncType" SG_ 299 GRA_LIM_Taste_verfuegbar 8;
BA_ "GenSigSendType" SG_ 299 GRA_Limiter 3;
BA_ "GenSigSendType" SG_ 299 GRA_reserveByte4 0;
BA_ "GenSigSendType" SG_ 299 GRA_reserveByte5 0;
BA_ "GenSigSendType" SG_ 299 GRA_reserveByte6 0;
BA_ "GenSigSendType" SG_ 299 GRA_reserveByte7 0;
BA_ "GenSigSendType" SG_ 299 GRA_reserveByte8 0;
BA_ "GenSigSendType" SG_ 299 GRA_Tip_Hoch 0;
BA_ "GenSigSendType" SG_ 299 GRA_Tip_Runter 0;
BA_ "GenSigSendType" SG_ 299 GRA_Tip_Setzen 0;
BA_ "GenSigSendType" SG_ 299 GRA_Tip_Stufe_2 0;
BA_ "GenSigSendType" SG_ 299 GRA_Tip_Wiederaufnahme 0;
BA_ "GenSigSendType" SG_ 299 GRA_TravelAssist 3;
BA_ "GenSigSwitchedByIgnition" SG_ 299 GRA_TravelAssist 0;
BA_ "GenSigSendType" SG_ 299 GRA_Typ_Bedienteil 0;
BA_ "GenSigSendType" SG_ 299 GRA_Typ_Hauptschalter 0;
BA_ "GenSigSendType" SG_ 299 GRA_Verstellung_Zeitluecke 0;
BA_ "GenSigSendType" SG_ 310 HAL_01_BZ 0;
BA_ "GenSigFuncType" SG_ 310 HAL_01_BZ 1;
BA_ "GenSigSwitchedByIgnition" SG_ 310 HAL_01_BZ 0;
BA_ "GenSigSendType" SG_ 310 HAL_01_CRC 0;
BA_ "GenSigFuncType" SG_ 310 HAL_01_CRC 2;
BA_ "GenSigSwitchedByIgnition" SG_ 310 HAL_01_CRC 0;
BA_ "GenSigSendType" SG_ 310 HAL_Charisma_FahrPr 0;
BA_ "GenSigSwitchedByIgnition" SG_ 310 HAL_Charisma_FahrPr 0;
BA_ "GenSigSendType" SG_ 310 HAL_Charisma_Status 0;
BA_ "GenSigSwitchedByIgnition" SG_ 310 HAL_Charisma_Status 0;
BA_ "GenSigSendType" SG_ 310 HAL_EFP_FahrPr 0;
BA_ "GenSigSwitchedByIgnition" SG_ 310 HAL_EFP_FahrPr 0;
BA_ "GenSigSendType" SG_ 310 HAL_Fahrerwunschwinkel_Soll 0;
BA_ "GenSigStartValue" SG_ 310 HAL_Fahrerwunschwinkel_Soll 1022;
BA_ "GenSigSwitchedByIgnition" SG_ 310 HAL_Fahrerwunschwinkel_Soll 0;
BA_ "Fehlerwert" SG_ 310 HAL_Fahrerwunschwinkel_Soll 1023;
BA_ "GenSigSendType" SG_ 310 HAL_max_Gradient 0;
BA_ "GenSigStartValue" SG_ 310 HAL_max_Gradient 126;
BA_ "GenSigSwitchedByIgnition" SG_ 310 HAL_max_Gradient 0;
BA_ "Fehlerwert" SG_ 310 HAL_max_Gradient 127;
BA_ "GenSigSendType" SG_ 310 HAL_QBit_Radwinkel 0;
BA_ "GenSigSwitchedByIgnition" SG_ 310 HAL_QBit_Radwinkel 0;
BA_ "GenSigSendType" SG_ 310 HAL_Radwinkel 0;
BA_ "GenSigStartValue" SG_ 310 HAL_Radwinkel 1022;
BA_ "GenSigSwitchedByIgnition" SG_ 310 HAL_Radwinkel 0;
BA_ "Fehlerwert" SG_ 310 HAL_Radwinkel 1023;
BA_ "GenSigSendType" SG_ 310 HAL_Status 0;
BA_ "GenSigSwitchedByIgnition" SG_ 310 HAL_Status 0;
BA_ "GenSigSendType" SG_ 310 HAL_Status_2 0;
BA_ "GenSigSwitchedByIgnition" SG_ 310 HAL_Status_2 0;
BA_ "GenSigSendType" SG_ 310 HAL_VZ_Fahrerwunschwinkel_Soll 0;
BA_ "GenSigSwitchedByIgnition" SG_ 310 HAL_VZ_Fahrerwunschwinkel_Soll 0;
BA_ "GenSigSendType" SG_ 310 HAL_VZ_Radwinkel 0;
BA_ "GenSigSwitchedByIgnition" SG_ 310 HAL_VZ_Radwinkel 0;
BA_ "GenSigSendType" SG_ 310 HAL_Warnungen 3;
BA_ "GenSigSwitchedByIgnition" SG_ 310 HAL_Warnungen 0;
BA_ "GenSigSendType" SG_ 310 HAL_Winkelbegrenzung 0;
BA_ "GenSigSwitchedByIgnition" SG_ 310 HAL_Winkelbegrenzung 0;
BA_ "GenSigSendType" SG_ 1410 HD_Bewegung_auf 0;
BA_ "GenSigSwitchedByIgnition" SG_ 1410 HD_Bewegung_auf 0;
BA_ "GenSigSendType" SG_ 1410 HD_Bewegung_zu 0;
BA_ "GenSigSwitchedByIgnition" SG_ 1410 HD_Bewegung_zu 0;
BA_ "GenSigSendType" SG_ 1410 HD_Endstellung_oben 0;
BA_ "GenSigSwitchedByIgnition" SG_ 1410 HD_Endstellung_oben 0;
BA_ "GenSigSendType" SG_ 1410 HD_Endstellung_unten 0;
BA_ "GenSigSwitchedByIgnition" SG_ 1410 HD_Endstellung_unten 0;
BA_ "GenSigSendType" SG_ 1410 HD_Innentaster_betaetigt 0;
BA_ "GenSigSwitchedByIgnition" SG_ 1410 HD_Innentaster_betaetigt 0;
BA_ "GenSigSendType" SG_ 1410 HD_Position 0;
BA_ "GenSigSwitchedByIgnition" SG_ 1410 HD_Position 0;
BA_ "GenSigSendType" SG_ 1410 HD_Rueckmeld_prog 0;
BA_ "GenSigSwitchedByIgnition" SG_ 1410 HD_Rueckmeld_prog 0;
BA_ "GenSigSendType" SG_ 1410 HD_Taster_defekt 0;
BA_ "GenSigSwitchedByIgnition" SG_ 1410 HD_Taster_defekt 0;
BA_ "GenSigSendType" SG_ 1410 HD_UeKB_erkannt 0;
BA_ "GenSigSwitchedByIgnition" SG_ 1410 HD_UeKB_erkannt 0;
BA_ "GenSigSendType" SG_ 1410 HD_Verr_Taster_betaetigt_inv 0;
BA_ "GenSigSwitchedByIgnition" SG_ 1410 HD_Verr_Taster_betaetigt_inv 0;
BA_ "GenSigSendType" SG_ 1410 HD_Verriegelungstaster_betaetigt 0;
BA_ "GenSigSwitchedByIgnition" SG_ 1410 HD_Verriegelungstaster_betaetigt 0;
BA_ "GenSigSendType" SG_ 1410 HD_ZZH_Schalter_S3 3;
BA_ "GenSigSwitchedByIgnition" SG_ 1410 HD_ZZH_Schalter_S3 0;
BA_REL_ "GenSigTimeoutTime" BU_SG_REL_ BedienDisp_vo SG_ 705 EFP_Status_Taster_Fahrwerk 800;
BA_REL_ "GenSigTimeoutTime" BU_SG_REL_ DDA SG_ 264 FA_Hoehenwert_VL_00 500;
BA_REL_ "GenSigTimeoutTime" BU_SG_REL_ DDA SG_ 264 FA_Hoehenwert_VR_00 500;
BA_REL_ "GenSigTimeoutTime" BU_SG_REL_ DDA SG_ 264 FA_Hoehenwert_HL_00 500;
BA_REL_ "GenSigTimeoutTime" BU_SG_REL_ DDA SG_ 264 FA_Hoehenwert_HR_00 500;
BA_REL_ "GenSigTimeoutTime" BU_SG_REL_ DDA SG_ 173 GE_Fahrstufe 5000;
BA_REL_ "GenSigTimeoutTime" BU_SG_REL_ OTA_FC SG_ 795 ESP_Lampe 500;
BA_REL_ "GenSigTimeoutTime" BU_SG_REL_ OTA_FC SG_ 795 ABS_Lampe 500;
BA_REL_ "GenSigTimeoutTime" BU_SG_REL_ OTA_FC SG_ 795 BK_Lampe_02 500;
BA_REL_ "GenSigTimeoutTime" BU_SG_REL_ OTA_FC SG_ 795 ESP_Textanzeigen_03 500;
BA_REL_ "GenSigTimeoutTime" BU_SG_REL_ OTA_FC SG_ 795 ESP_Off_Lampe 500;
BA_REL_ "GenSigTimeoutTime" BU_SG_REL_ OTA_FC SG_ 795 ESP_BKV_Warnung 500;
BA_REL_ "GenSigTimeoutTime" BU_SG_REL_ OTA_FC SG_ 508 ESP_HOLD_verf 2000;
BA_REL_ "GenSigTimeoutTime" BU_SG_REL_ OTA_FC SG_ 264 FA_Hoehenwert_VL_00 500;
BA_REL_ "GenSigTimeoutTime" BU_SG_REL_ OTA_FC SG_ 264 FA_Hoehenwert_VR_00 500;
BA_REL_ "GenSigTimeoutTime" BU_SG_REL_ OTA_FC SG_ 264 FA_Hoehenwert_HL_00 500;
BA_REL_ "GenSigTimeoutTime" BU_SG_REL_ OTA_FC SG_ 264 FA_Hoehenwert_HR_00 500;
BA_REL_ "GenSigTimeoutTime" BU_SG_REL_ OTA_FC SG_ 264 FA_Fahrbahnunebenheit 500;
BA_REL_ "GenSigTimeoutTime" BU_SG_REL_ OTA_FC SG_ 429 NR_Reglerstatus 5000;
BA_REL_ "GenSigTimeoutTime" BU_SG_REL_ OTA_FC SG_ 429 FA_Absenkung_Fahrzeug 5000;
BA_REL_ "GenSigTimeoutTime" BU_SG_REL_ OTA_FC SG_ 429 FA_Anhebung_Fahrzeug 5000;
BA_REL_ "GenSigTimeoutTime" BU_SG_REL_ OTA_FC SG_ 429 FA_Druckspeicher_verfuegbar 5000;
BA_REL_ "GenSigTimeoutTime" BU_SG_REL_ OTA_FC SG_ 429 FA_Zwischenniveau 5000;
BA_REL_ "GenSigTimeoutTime" BU_SG_REL_ OTA_FC SG_ 429 NR_Kompressor_Temp_Zylinderkopf 5000;
BA_REL_ "GenSigTimeoutTime" BU_SG_REL_ OTA_FC SG_ 429 FA_Signal_Drucksensor 5000;
BA_REL_ "GenSigTimeoutTime" BU_SG_REL_ OTA_FC SG_ 2527679658 FA_FahrerAnf_Fahrwerk 3200;
BA_REL_ "GenSigTimeoutTime" BU_SG_REL_ OTA_FC SG_ 2527679658 FA_FahrerAnf_Lift 3200;
BA_REL_ "GenSigTimeoutTime" BU_SG_REL_ OTA_FC SG_ 2527679658 FA_FahrerAnf_Niveau 3200;
BA_REL_ "GenSigTimeoutTime" BU_SG_REL_ OTA_FC SG_ 2527679658 EFP_ReifenTemp_HL 3200;
BA_REL_ "GenSigTimeoutTime" BU_SG_REL_ OTA_FC SG_ 2527679658 EFP_ReifenTemp_HR 3200;
BA_REL_ "GenSigTimeoutTime" BU_SG_REL_ OTA_FC SG_ 2527679658 EFP_ReifenTemp_VL 3200;
BA_REL_ "GenSigTimeoutTime" BU_SG_REL_ OTA_FC SG_ 2527679658 EFP_ReifenTemp_VR 3200;
BA_REL_ "GenSigTimeoutTime" BU_SG_REL_ OTA_FC SG_ 173 GE_Fahrstufe 5000;
BA_REL_ "GenSigTimeoutTime" BU_SG_REL_ OTA_FC SG_ 173 GE_Zielgang 5000;
BA_REL_ "GenSigTimeoutTime" BU_SG_REL_ OTA_FC SG_ 968 GE_LaunchControl 2000;
BA_REL_ "GenSigTimeoutTime" BU_SG_REL_ OTA_FC SG_ 968 GE_Sumpftemperatur 2000;
BA_REL_ "GenSigTimeoutTime" BU_SG_REL_ OTA_FC SG_ 177 GE_Fahrprogramm 5000;
BA_REL_ "GenSigTimeoutTime" BU_SG_REL_ OTA_FC SG_ 177 GE_Getriebestatus_02 5000;
BA_REL_ "GenSigTimeoutTime" BU_SG_REL_ OTA_FC SG_ 891 GNSS_UTC_Zeit 5000;
BA_REL_ "GenSigTimeoutTime" BU_SG_REL_ OTA_FC SG_ 891 GNSS_Empfaenger_Status 5000;
BA_REL_ "GenSigTimeoutTime" BU_SG_REL_ ZR_High SG_ 795 ESP_Lampe 500;
BA_REL_ "GenSigTimeoutTime" BU_SG_REL_ ZR_High SG_ 795 ABS_Lampe 500;
BA_REL_ "GenSigTimeoutTime" BU_SG_REL_ ZR_High SG_ 795 ESP_Wegimp_VA 500;
BA_REL_ "GenSigTimeoutTime" BU_SG_REL_ ZR_High SG_ 795 ESP_Fehlerstatus_Wegimp 500;
BA_REL_ "GenSigTimeoutTime" BU_SG_REL_ ZR_High SG_ 795 ESP_Wegimp_Ueberlauf 500;
BA_REL_ "GenSigTimeoutTime" BU_SG_REL_ ZR_High SG_ 795 ESP_QBit_Wegimp_VA 500;
BA_REL_ "GenSigTimeoutTime" BU_SG_REL_ ZR_High SG_ 795 ESP_HDC_Geschw_Farbe 500;
BA_REL_ "GenSigTimeoutTime" BU_SG_REL_ ZR_High SG_ 795 ESP_Off_Lampe 500;
BA_REL_ "GenSigTimeoutTime" BU_SG_REL_ ZR_High SG_ 795 ESP_HDC_Regelgeschw 500;
BA_REL_ "GenSigTimeoutTime" BU_SG_REL_ ZR_High SG_ 508 ESP_EDS_Anzeige 2000;
BA_REL_ "GenSigTimeoutTime" BU_SG_REL_ ZR_High SG_ 264 FA_Hoehenwerte_kalibriert 500;
BA_REL_ "GenSigTimeoutTime" BU_SG_REL_ ZR_High SG_ 264 FA_Hoehenwert_VL_00 500;
BA_REL_ "GenSigTimeoutTime" BU_SG_REL_ ZR_High SG_ 264 FA_Hoehenwert_VR_00 500;
BA_REL_ "GenSigTimeoutTime" BU_SG_REL_ ZR_High SG_ 264 FA_Hoehenwert_HL_00 500;
BA_REL_ "GenSigTimeoutTime" BU_SG_REL_ ZR_High SG_ 264 FA_Hoehenwert_HR_00 500;
BA_REL_ "GenSigTimeoutTime" BU_SG_REL_ ZR_High SG_ 264 FA_Fahrbahnunebenheit 500;
BA_REL_ "GenSigTimeoutTime" BU_SG_REL_ ZR_High SG_ 2527679659 FA_Niveau_Druck_HL 3200;
BA_REL_ "GenSigTimeoutTime" BU_SG_REL_ ZR_High SG_ 2527679659 FA_Niveau_Druck_HR 3200;
BA_REL_ "GenSigTimeoutTime" BU_SG_REL_ ZR_High SG_ 2527679659 FA_Niveau_Druck_VL 3200;
BA_REL_ "GenSigTimeoutTime" BU_SG_REL_ ZR_High SG_ 2527679659 FA_Niveau_Druck_VR 3200;
BA_REL_ "GenSigTimeoutTime" BU_SG_REL_ ZR_High SG_ 429 NR_Reglerstatus 5000;
BA_REL_ "GenSigTimeoutTime" BU_SG_REL_ ZR_High SG_ 429 FA_Verstellung_in_Kuerze 5000;
BA_REL_ "GenSigTimeoutTime" BU_SG_REL_ ZR_High SG_ 429 FA_Verstellung_aktiv 5000;
BA_REL_ "GenSigTimeoutTime" BU_SG_REL_ ZR_High SG_ 429 NR_LED_SGN 5000;
BA_REL_ "GenSigTimeoutTime" BU_SG_REL_ ZR_High SG_ 429 NR_LED_TN 5000;
BA_REL_ "GenSigTimeoutTime" BU_SG_REL_ ZR_High SG_ 429 NR_LED_BN 5000;
BA_REL_ "GenSigTimeoutTime" BU_SG_REL_ ZR_High SG_ 429 FA_Absenkung_Fahrzeug 5000;
BA_REL_ "GenSigTimeoutTime" BU_SG_REL_ ZR_High SG_ 429 FA_Anhaengerstatus_intern 5000;
BA_REL_ "GenSigTimeoutTime" BU_SG_REL_ ZR_High SG_ 429 FA_Anhebung_Fahrzeug 5000;
BA_REL_ "GenSigTimeoutTime" BU_SG_REL_ ZR_High SG_ 429 NR_LED_HN 5000;
BA_REL_ "GenSigTimeoutTime" BU_SG_REL_ ZR_High SG_ 429 FA_Systemstatus 5000;
BA_REL_ "GenSigTimeoutTime" BU_SG_REL_ ZR_High SG_ 2527679658 FA_Beladung_HA 3200;
BA_REL_ "GenSigTimeoutTime" BU_SG_REL_ ZR_High SG_ 2527679658 FA_Beladung_VA 3200;
BA_REL_ "GenSigTimeoutTime" BU_SG_REL_ ZR_High SG_ 2463978619 FAS_SollStatus_Fkt_ASW 5000;
BA_REL_ "GenSigTimeoutTime" BU_SG_REL_ ZR_High SG_ 2463978619 FAS_SollStatus_Fkt_SWA 5000;
BA_REL_ "GenSigTimeoutTime" BU_SG_REL_ ZR_High SG_ 2463978619 FAS_SollStatus_Fkt_MKE 5000;
BA_REL_ "GenSigTimeoutTime" BU_SG_REL_ ZR_High SG_ 2463978619 FAS_SollStatus_Fkt_NV 5000;
BA_REL_ "GenSigTimeoutTime" BU_SG_REL_ ZR_High SG_ 2463978619 FAS_SollStatus_Fkt_AbstWarn_MV 5000;
BA_REL_ "GenSigTimeoutTime" BU_SG_REL_ ZR_High SG_ 2463978619 FAS_SollStatus_Fkt_STP 5000;
BA_REL_ "GenSigTimeoutTime" BU_SG_REL_ ZR_High SG_ 2463978619 FAS_SollStatus_Fkt_PreCrash 5000;
BA_REL_ "GenSigTimeoutTime" BU_SG_REL_ ZR_High SG_ 2463978619 FAS_SollStatus_Fkt_LGI 5000;
BA_REL_ "GenSigTimeoutTime" BU_SG_REL_ ZR_High SG_ 2527679660 FB_Fahrerwechsel 3200;
BA_REL_ "GenSigTimeoutTime" BU_SG_REL_ ZR_High SG_ 2527679660 FB_Fehler 3200;
BA_REL_ "GenSigTimeoutTime" BU_SG_REL_ ZR_High SG_ 2527679660 FB_Muedigkeit_Guete 3200;
BA_REL_ "GenSigTimeoutTime" BU_SG_REL_ ZR_High SG_ 2527679660 FB_Muedigkeit_Index 3200;
BA_REL_ "GenSigTimeoutTime" BU_SG_REL_ ZR_High SG_ 707 FDR_M_HL_02 800;
BA_REL_ "GenSigTimeoutTime" BU_SG_REL_ ZR_High SG_ 707 FDR_M_HR_02 800;
BA_REL_ "GenSigTimeoutTime" BU_SG_REL_ ZR_High SG_ 707 FDR_M_VL_02 800;
BA_REL_ "GenSigTimeoutTime" BU_SG_REL_ ZR_High SG_ 707 FDR_M_VR_02 800;
BA_REL_ "GenSigTimeoutTime" BU_SG_REL_ ZR_High SG_ 1605 FLA_ISP_defekt 5000;
BA_REL_ "GenSigTimeoutTime" BU_SG_REL_ ZR_High SG_ 1605 FLA_Sensor_blockiert 5000;
BA_REL_ "GenSigTimeoutTime" BU_SG_REL_ ZR_High SG_ 1605 FLA_Abblendursache 5000;
BA_REL_ "GenSigTimeoutTime" BU_SG_REL_ ZR_High SG_ 2589283684 FoD_Transmission_Info 5000;
BA_REL_ "GenSigTimeoutTime" BU_SG_REL_ ZR_High SG_ 173 GE_Fahrstufe 5000;
BA_REL_ "GenSigTimeoutTime" BU_SG_REL_ ZR_High SG_ 173 GE_Zielgang 5000;
BA_REL_ "GenSigTimeoutTime" BU_SG_REL_ ZR_High SG_ 968 GE_Sumpftemperatur 2000;
BA_REL_ "GenSigTimeoutTime" BU_SG_REL_ ZR_High SG_ 177 GE_Fahrprogramm 5000;
BA_REL_ "GenSigTimeoutTime" BU_SG_REL_ ZR_High SG_ 177 GE_TippZustand 5000;
BA_REL_ "GenSigTimeoutTime" BU_SG_REL_ ZR_High SG_ 879 GNSS_Nachrichtenpaket_ID1 5000;
BA_REL_ "GenSigTimeoutTime" BU_SG_REL_ ZR_High SG_ 879 GNSS_Breite_Ortung 5000;
BA_REL_ "GenSigTimeoutTime" BU_SG_REL_ ZR_High SG_ 879 GNSS_Richtung_Breite_Ortung 5000;
BA_REL_ "GenSigTimeoutTime" BU_SG_REL_ ZR_High SG_ 879 GNSS_Laenge_Ortung 5000;
BA_REL_ "GenSigTimeoutTime" BU_SG_REL_ ZR_High SG_ 879 GNSS_Richtung_Laenge_Ortung 5000;
BA_REL_ "GenSigTimeoutTime" BU_SG_REL_ ZR_High SG_ 879 GNSS_Ortung_FIX_Typ 5000;
BA_REL_ "GenSigTimeoutTime" BU_SG_REL_ ZR_High SG_ 879 GNSS_Fehlerzustand 5000;
BA_REL_ "GenSigTimeoutTime" BU_SG_REL_ ZR_High SG_ 884 GNSS_Nachrichtenpaket_ID2 5000;
BA_REL_ "GenSigTimeoutTime" BU_SG_REL_ ZR_High SG_ 884 GNSS_Ortung_Latenz 5000;
BA_REL_ "GenSigTimeoutTime" BU_SG_REL_ ZR_High SG_ 884 GNSS_Ortung_Ausrichtung 5000;
BA_REL_ "GenSigTimeoutTime" BU_SG_REL_ ZR_High SG_ 884 GNSS_Ortung_2D_Geschw_ue_Grund 5000;
BA_REL_ "GenSigTimeoutTime" BU_SG_REL_ ZR_High SG_ 884 GNSS_Ortung_Noerdliche_Geschw 5000;
BA_REL_ "GenSigTimeoutTime" BU_SG_REL_ ZR_High SG_ 884 GNSS_Ortung_Oestliche_Geschw 5000;
BA_REL_ "GenSigTimeoutTime" BU_SG_REL_ ZR_High SG_ 884 GNSS_Ortung_Vertikale_Geschw 5000;
BA_REL_ "GenSigTimeoutTime" BU_SG_REL_ ZR_High SG_ 886 GNSS_Nachrichtenpaket_ID3 5000;
BA_REL_ "GenSigTimeoutTime" BU_SG_REL_ ZR_High SG_ 886 GNSS_Ortung_GDOP 5000;
BA_REL_ "GenSigTimeoutTime" BU_SG_REL_ ZR_High SG_ 886 GNSS_Ortung_PDOP 5000;
BA_REL_ "GenSigTimeoutTime" BU_SG_REL_ ZR_High SG_ 886 GNSS_Ortung_HDOP 5000;
BA_REL_ "GenSigTimeoutTime" BU_SG_REL_ ZR_High SG_ 886 GNSS_Ortung_VDOP 5000;
BA_REL_ "GenSigTimeoutTime" BU_SG_REL_ ZR_High SG_ 886 GNSS_Ortung_Guete_Geschwindigk 5000;
BA_REL_ "GenSigTimeoutTime" BU_SG_REL_ ZR_High SG_ 886 GNSS_Ortung_Guete_Ausrichtung 5000;
BA_REL_ "GenSigTimeoutTime" BU_SG_REL_ ZR_High SG_ 886 GNSS_Ortung_Guete_horizontal 5000;
BA_REL_ "GenSigTimeoutTime" BU_SG_REL_ ZR_High SG_ 886 GNSS_Ortung_Guete_vertikal 5000;
BA_REL_ "GenSigTimeoutTime" BU_SG_REL_ ZR_High SG_ 888 GNSS_Nachrichtenpaket_ID4 5000;
BA_REL_ "GenSigTimeoutTime" BU_SG_REL_ ZR_High SG_ 888 GNSS_Ortung_Zeit_in_GPSWoche 5000;
BA_REL_ "GenSigTimeoutTime" BU_SG_REL_ ZR_High SG_ 888 GNSS_Ortung_Hoehe 5000;
BA_REL_ "GenSigTimeoutTime" BU_SG_REL_ ZR_High SG_ 891 GNSS_UTC_Zeit 5000;
BA_REL_ "GenSigTimeoutTime" BU_SG_REL_ ZR_High SG_ 891 GNSS_Empfaenger_Status 5000;
BA_REL_ "GenSigTimeoutTime" BU_SG_REL_ ZR_High SG_ 891 GNSS_GPS_in_Nutzung 5000;
BA_REL_ "GenSigTimeoutTime" BU_SG_REL_ ZR_High SG_ 891 GNSS_GLONASS_in_Nutzung 5000;
BA_REL_ "GenSigTimeoutTime" BU_SG_REL_ ZR_High SG_ 891 GNSS_Empfangbare_Satelliten 5000;
BA_REL_ "GenSigTimeoutTime" BU_SG_REL_ ZR_High SG_ 891 GNSS_Sichtbare_Satelliten 5000;
BA_REL_ "GenSigTimeoutTime" BU_SG_REL_ ZR_High SG_ 891 GNSS_Genutzte_Satelliten 5000;
BA_REL_ "GenSigTimeoutTime" BU_SG_REL_ ZR_High SG_ 891 GNSS_Nachrichtenpaket_ID5 5000;
BA_REL_ "GenSigTimeoutTime" BU_SG_REL_ ZR_High SG_ 1364 GNSS_Sat_Info_Sat_ID_1 5000;
BA_REL_ "GenSigTimeoutTime" BU_SG_REL_ ZR_High SG_ 1364 GNSS_Sat_Info_SNR_ID_1 5000;
BA_REL_ "GenSigTimeoutTime" BU_SG_REL_ ZR_High SG_ 1364 GNSS_Sat_Info_Azimuth_ID_1 5000;
BA_REL_ "GenSigTimeoutTime" BU_SG_REL_ ZR_High SG_ 1364 GNSS_Sat_Info_Hoehenwinkel_ID_1 5000;
BA_REL_ "GenSigTimeoutTime" BU_SG_REL_ ZR_High SG_ 1364 GNSS_Nachrichtenpaket_ID6 5000;
BA_REL_ "GenSigTimeoutTime" BU_SG_REL_ ZR_High SG_ 299 GRA_Hauptschalter 2000;
BA_REL_ "GenSigTimeoutTime" BU_SG_REL_ ZR_High SG_ 299 GRA_Abbrechen 2000;
BA_REL_ "GenSigTimeoutTime" BU_SG_REL_ ZR_High SG_ 299 GRA_Typ_Hauptschalter 2000;
BA_REL_ "GenSigTimeoutTime" BU_SG_REL_ ZR_High SG_ 299 GRA_Limiter 2000;
BA_REL_ "GenSigTimeoutTime" BU_SG_REL_ ZR_High SG_ 299 GRA_Tip_Setzen 2000;
BA_REL_ "GenSigTimeoutTime" BU_SG_REL_ ZR_High SG_ 299 GRA_Tip_Hoch 2000;
BA_REL_ "GenSigTimeoutTime" BU_SG_REL_ ZR_High SG_ 299 GRA_Tip_Runter 2000;
BA_REL_ "GenSigTimeoutTime" BU_SG_REL_ ZR_High SG_ 299 GRA_Tip_Wiederaufnahme 2000;
BA_REL_ "GenSigTimeoutTime" BU_SG_REL_ ZR_High SG_ 299 GRA_Verstellung_Zeitluecke 2000;
BA_REL_ "GenSigTimeoutTime" BU_SG_REL_ ZR_High SG_ 299 GRA_Codierung 2000;
BA_REL_ "GenSigTimeoutTime" BU_SG_REL_ ZR_High SG_ 299 GRA_Fehler 2000;
BA_REL_ "GenSigTimeoutTime" BU_SG_REL_ ZR_High SG_ 299 GRA_LIM_Taste_verfuegbar 2000;
BA_REL_ "GenSigTimeoutTime" BU_SG_REL_ ZR_High SG_ 299 GRA_Tip_Stufe_2 2000;
BA_REL_ "GenSigTimeoutTime" BU_SG_REL_ ZR_High SG_ 299 GRA_Typ_Bedienteil 2000;
BA_REL_ "GenSigTimeoutTime" BU_SG_REL_ ZR_High SG_ 1410 HD_Endstellung_oben 2000;
BA_REL_ "GenSigTimeoutTime" BU_SG_REL_ ZR_High SG_ 1410 HD_Endstellung_unten 2000;
BA_REL_ "GenSigTimeoutTime" BU_SG_REL_ ZR_High SG_ 1410 HD_Bewegung_auf 2000;
BA_REL_ "GenSigTimeoutTime" BU_SG_REL_ ZR_High SG_ 1410 HD_Bewegung_zu 2000;
BA_REL_ "GenSigTimeoutTime" BU_SG_REL_ ZR_High SG_ 1410 HD_Innentaster_betaetigt 2000;
BA_REL_ "GenSigTimeoutTime" BU_SG_REL_ ZR_High SG_ 1410 HD_UeKB_erkannt 2000;
BA_REL_ "GenSigTimeoutTime" BU_SG_REL_ ZR_High SG_ 1410 HD_Position 2000;
BA_REL_ "GenSigTimeoutTime" BU_SG_REL_ ZR_High SG_ 1410 HD_Taster_defekt 2000;
BA_REL_ "GenSigTimeoutTime" BU_SG_REL_ ZR_High SG_ 1410 HD_Verriegelungstaster_betaetigt 2000;
BA_REL_ "GenSigTimeoutTime" BU_SG_REL_ ZR_LIMU SG_ 795 ESP_Lampe 500;
BA_REL_ "GenSigTimeoutTime" BU_SG_REL_ ZR_LIMU SG_ 795 ESP_Wegimp_VA 500;
BA_REL_ "GenSigTimeoutTime" BU_SG_REL_ ZR_LIMU SG_ 795 ESP_Fehlerstatus_Wegimp 500;
BA_REL_ "GenSigTimeoutTime" BU_SG_REL_ ZR_LIMU SG_ 795 ESP_Wegimp_Ueberlauf 500;
BA_REL_ "GenSigTimeoutTime" BU_SG_REL_ ZR_LIMU SG_ 795 ESP_QBit_Wegimp_VA 500;
BA_REL_ "GenSigTimeoutTime" BU_SG_REL_ ZR_LIMU SG_ 795 ESP_HDC_Geschw_Farbe 500;
BA_REL_ "GenSigTimeoutTime" BU_SG_REL_ ZR_LIMU SG_ 795 ESP_HDC_Regelgeschw 500;
BA_REL_ "GenSigTimeoutTime" BU_SG_REL_ ZR_LIMU SG_ 508 ESP_Status_Bremsentemp_02 2000;
BA_REL_ "GenSigTimeoutTime" BU_SG_REL_ ZR_LIMU SG_ 508 ESP_EDS_Anzeige 2000;
BA_REL_ "GenSigTimeoutTime" BU_SG_REL_ ZR_LIMU SG_ 600 ESP_54_CRC 4000;
BA_REL_ "GenSigTimeoutTime" BU_SG_REL_ ZR_LIMU SG_ 600 ESP_54_BZ 4000;
BA_REL_ "GenSigTimeoutTime" BU_SG_REL_ ZR_LIMU SG_ 600 ESP_Slider_Text 4000;
BA_REL_ "GenSigTimeoutTime" BU_SG_REL_ ZR_LIMU SG_ 600 ESP_Slider_Status 4000;
BA_REL_ "GenSigTimeoutTime" BU_SG_REL_ ZR_LIMU SG_ 600 ESP_Slider_ist_01 4000;
BA_REL_ "GenSigTimeoutTime" BU_SG_REL_ ZR_LIMU SG_ 600 ESP_Slider_ist_02 4000;
BA_REL_ "GenSigTimeoutTime" BU_SG_REL_ ZR_LIMU SG_ 600 ESP_Slider_ist_03 4000;
BA_REL_ "GenSigTimeoutTime" BU_SG_REL_ ZR_LIMU SG_ 707 FDR_M_HL_02 800;
BA_REL_ "GenSigTimeoutTime" BU_SG_REL_ ZR_LIMU SG_ 707 FDR_M_HR_02 800;
BA_REL_ "GenSigTimeoutTime" BU_SG_REL_ ZR_LIMU SG_ 707 FDR_M_VL_02 800;
BA_REL_ "GenSigTimeoutTime" BU_SG_REL_ ZR_LIMU SG_ 707 FDR_M_VR_02 800;
BA_REL_ "GenSigTimeoutTime" BU_SG_REL_ ZR_LIMU SG_ 2589283684 FoD_Transmission_Info 5000;
BA_REL_ "GenSigTimeoutTime" BU_SG_REL_ ZR_LIMU SG_ 173 GE_Fahrstufe 5000;
BA_REL_ "GenSigTimeoutTime" BU_SG_REL_ ZR_LIMU SG_ 879 GNSS_Nachrichtenpaket_ID1 5000;
BA_REL_ "GenSigTimeoutTime" BU_SG_REL_ ZR_LIMU SG_ 879 GNSS_Breite_Ortung 5000;
BA_REL_ "GenSigTimeoutTime" BU_SG_REL_ ZR_LIMU SG_ 879 GNSS_Richtung_Breite_Ortung 5000;
BA_REL_ "GenSigTimeoutTime" BU_SG_REL_ ZR_LIMU SG_ 879 GNSS_Laenge_Ortung 5000;
BA_REL_ "GenSigTimeoutTime" BU_SG_REL_ ZR_LIMU SG_ 879 GNSS_Richtung_Laenge_Ortung 5000;
BA_REL_ "GenSigTimeoutTime" BU_SG_REL_ ZR_LIMU SG_ 879 GNSS_Ortung_FIX_Typ 5000;
BA_REL_ "GenSigTimeoutTime" BU_SG_REL_ ZR_LIMU SG_ 879 GNSS_Fehlerzustand 5000;
BA_REL_ "GenSigTimeoutTime" BU_SG_REL_ ZR_LIMU SG_ 884 GNSS_Nachrichtenpaket_ID2 5000;
BA_REL_ "GenSigTimeoutTime" BU_SG_REL_ ZR_LIMU SG_ 884 GNSS_Ortung_Latenz 5000;
BA_REL_ "GenSigTimeoutTime" BU_SG_REL_ ZR_LIMU SG_ 884 GNSS_Ortung_Ausrichtung 5000;
BA_REL_ "GenSigTimeoutTime" BU_SG_REL_ ZR_LIMU SG_ 884 GNSS_Ortung_2D_Geschw_ue_Grund 5000;
BA_REL_ "GenSigTimeoutTime" BU_SG_REL_ ZR_LIMU SG_ 884 GNSS_Ortung_Noerdliche_Geschw 5000;
BA_REL_ "GenSigTimeoutTime" BU_SG_REL_ ZR_LIMU SG_ 884 GNSS_Ortung_Oestliche_Geschw 5000;
BA_REL_ "GenSigTimeoutTime" BU_SG_REL_ ZR_LIMU SG_ 884 GNSS_Ortung_Vertikale_Geschw 5000;
BA_REL_ "GenSigTimeoutTime" BU_SG_REL_ ZR_LIMU SG_ 886 GNSS_Nachrichtenpaket_ID3 5000;
BA_REL_ "GenSigTimeoutTime" BU_SG_REL_ ZR_LIMU SG_ 886 GNSS_Ortung_GDOP 5000;
BA_REL_ "GenSigTimeoutTime" BU_SG_REL_ ZR_LIMU SG_ 886 GNSS_Ortung_PDOP 5000;
BA_REL_ "GenSigTimeoutTime" BU_SG_REL_ ZR_LIMU SG_ 886 GNSS_Ortung_HDOP 5000;
BA_REL_ "GenSigTimeoutTime" BU_SG_REL_ ZR_LIMU SG_ 886 GNSS_Ortung_VDOP 5000;
BA_REL_ "GenSigTimeoutTime" BU_SG_REL_ ZR_LIMU SG_ 886 GNSS_Ortung_Guete_Geschwindigk 5000;
BA_REL_ "GenSigTimeoutTime" BU_SG_REL_ ZR_LIMU SG_ 886 GNSS_Ortung_Guete_Ausrichtung 5000;
BA_REL_ "GenSigTimeoutTime" BU_SG_REL_ ZR_LIMU SG_ 886 GNSS_Ortung_Guete_horizontal 5000;
BA_REL_ "GenSigTimeoutTime" BU_SG_REL_ ZR_LIMU SG_ 886 GNSS_Ortung_Guete_vertikal 5000;
BA_REL_ "GenSigTimeoutTime" BU_SG_REL_ ZR_LIMU SG_ 888 GNSS_Nachrichtenpaket_ID4 5000;
BA_REL_ "GenSigTimeoutTime" BU_SG_REL_ ZR_LIMU SG_ 888 GNSS_Ortung_Zeit_in_GPSWoche 5000;
BA_REL_ "GenSigTimeoutTime" BU_SG_REL_ ZR_LIMU SG_ 888 GNSS_Ortung_Hoehe 5000;
BA_REL_ "GenSigTimeoutTime" BU_SG_REL_ ZR_LIMU SG_ 891 GNSS_UTC_Zeit 5000;
BA_REL_ "GenSigTimeoutTime" BU_SG_REL_ ZR_LIMU SG_ 891 GNSS_Empfaenger_Status 5000;
BA_REL_ "GenSigTimeoutTime" BU_SG_REL_ ZR_LIMU SG_ 891 GNSS_GPS_in_Nutzung 5000;
BA_REL_ "GenSigTimeoutTime" BU_SG_REL_ ZR_LIMU SG_ 891 GNSS_GLONASS_in_Nutzung 5000;
BA_REL_ "GenSigTimeoutTime" BU_SG_REL_ ZR_LIMU SG_ 891 GNSS_Empfangbare_Satelliten 5000;
BA_REL_ "GenSigTimeoutTime" BU_SG_REL_ ZR_LIMU SG_ 891 GNSS_Sichtbare_Satelliten 5000;
BA_REL_ "GenSigTimeoutTime" BU_SG_REL_ ZR_LIMU SG_ 891 GNSS_Genutzte_Satelliten 5000;
BA_REL_ "GenSigTimeoutTime" BU_SG_REL_ ZR_LIMU SG_ 891 GNSS_Nachrichtenpaket_ID5 5000;
BA_REL_ "GenSigTimeoutTime" BU_SG_REL_ ZR_LIMU SG_ 1364 GNSS_Sat_Info_Sat_ID_1 5000;
BA_REL_ "GenSigTimeoutTime" BU_SG_REL_ ZR_LIMU SG_ 1364 GNSS_Sat_Info_SNR_ID_1 5000;
BA_REL_ "GenSigTimeoutTime" BU_SG_REL_ ZR_LIMU SG_ 1364 GNSS_Sat_Info_Azimuth_ID_1 5000;
BA_REL_ "GenSigTimeoutTime" BU_SG_REL_ ZR_LIMU SG_ 1364 GNSS_Sat_Info_Hoehenwinkel_ID_1 5000;
BA_REL_ "GenSigTimeoutTime" BU_SG_REL_ ZR_LIMU SG_ 1364 GNSS_Nachrichtenpaket_ID6 5000;
BA_REL_ "GenSigTimeoutTime" BU_SG_REL_ ZR_LIMU SG_ 310 HAL_VZ_Radwinkel 1000;
BA_REL_ "GenSigTimeoutTime" BU_SG_REL_ ZR_LIMU SG_ 310 HAL_Radwinkel 1000;
BA_REL_ "GenSigTimeoutTime" BU_SG_REL_ ZR_MIB_TOP_ab_Gen3 SG_ 795 ESP_Lampe 500;
BA_REL_ "GenSigTimeoutTime" BU_SG_REL_ ZR_MIB_TOP_ab_Gen3 SG_ 795 ESP_Wegimp_VA 500;
BA_REL_ "GenSigTimeoutTime" BU_SG_REL_ ZR_MIB_TOP_ab_Gen3 SG_ 795 ESP_Fehlerstatus_Wegimp 500;
BA_REL_ "GenSigTimeoutTime" BU_SG_REL_ ZR_MIB_TOP_ab_Gen3 SG_ 795 ESP_Wegimp_Ueberlauf 500;
BA_REL_ "GenSigTimeoutTime" BU_SG_REL_ ZR_MIB_TOP_ab_Gen3 SG_ 795 ESP_QBit_Wegimp_VA 500;
BA_REL_ "GenSigTimeoutTime" BU_SG_REL_ ZR_MIB_TOP_ab_Gen3 SG_ 795 ESP_HDC_Geschw_Farbe 500;
BA_REL_ "GenSigTimeoutTime" BU_SG_REL_ ZR_MIB_TOP_ab_Gen3 SG_ 795 ESP_HDC_Regelgeschw 500;
BA_REL_ "GenSigTimeoutTime" BU_SG_REL_ ZR_MIB_TOP_ab_Gen3 SG_ 508 ESP_Status_Bremsentemp_02 2000;
BA_REL_ "GenSigTimeoutTime" BU_SG_REL_ ZR_MIB_TOP_ab_Gen3 SG_ 508 ESP_EDS_Anzeige 2000;
BA_REL_ "GenSigTimeoutTime" BU_SG_REL_ ZR_MIB_TOP_ab_Gen3 SG_ 264 FA_Hoehenwert_VL_00 500;
BA_REL_ "GenSigTimeoutTime" BU_SG_REL_ ZR_MIB_TOP_ab_Gen3 SG_ 264 FA_Hoehenwert_VR_00 500;
BA_REL_ "GenSigTimeoutTime" BU_SG_REL_ ZR_MIB_TOP_ab_Gen3 SG_ 264 FA_Hoehenwert_HL_00 500;
BA_REL_ "GenSigTimeoutTime" BU_SG_REL_ ZR_MIB_TOP_ab_Gen3 SG_ 264 FA_Hoehenwert_HR_00 500;
BA_REL_ "GenSigTimeoutTime" BU_SG_REL_ ZR_MIB_TOP_ab_Gen3 SG_ 2527679658 FA_FahrerAnf_Fahrwerk 3200;
BA_REL_ "GenSigTimeoutTime" BU_SG_REL_ ZR_MIB_TOP_ab_Gen3 SG_ 2527679658 FA_FahrerAnf_Lift 3200;
BA_REL_ "GenSigTimeoutTime" BU_SG_REL_ ZR_MIB_TOP_ab_Gen3 SG_ 2527679658 FA_FahrerAnf_Niveau 3200;
BA_REL_ "GenSigTimeoutTime" BU_SG_REL_ ZR_MIB_TOP_ab_Gen3 SG_ 2527679896 FA_FahrerAnf_Lift_Abwurf 3200;
BA_REL_ "GenSigTimeoutTime" BU_SG_REL_ ZR_MIB_TOP_ab_Gen3 SG_ 2331595995 EFP_FVertDisp_VR 500;
BA_REL_ "GenSigTimeoutTime" BU_SG_REL_ ZR_MIB_TOP_ab_Gen3 SG_ 2331595995 EFP_FVertDisp_VL 500;
BA_REL_ "GenSigTimeoutTime" BU_SG_REL_ ZR_MIB_TOP_ab_Gen3 SG_ 2331595995 EFP_FVertDisp_HR 500;
BA_REL_ "GenSigTimeoutTime" BU_SG_REL_ ZR_MIB_TOP_ab_Gen3 SG_ 2331595995 EFP_FVertDisp_HL 500;
BA_REL_ "GenSigTimeoutTime" BU_SG_REL_ ZR_MIB_TOP_ab_Gen3 SG_ 707 FDR_M_HL_02 800;
BA_REL_ "GenSigTimeoutTime" BU_SG_REL_ ZR_MIB_TOP_ab_Gen3 SG_ 707 FDR_M_HR_02 800;
BA_REL_ "GenSigTimeoutTime" BU_SG_REL_ ZR_MIB_TOP_ab_Gen3 SG_ 707 FDR_M_VL_02 800;
BA_REL_ "GenSigTimeoutTime" BU_SG_REL_ ZR_MIB_TOP_ab_Gen3 SG_ 707 FDR_M_VR_02 800;
BA_REL_ "GenSigTimeoutTime" BU_SG_REL_ ZR_MIB_TOP_ab_Gen3 SG_ 2589283684 FoD_Transmission_Info 5000;
BA_REL_ "GenSigTimeoutTime" BU_SG_REL_ ZR_MIB_TOP_ab_Gen3 SG_ 173 GE_Fahrstufe 5000;
BA_REL_ "GenSigTimeoutTime" BU_SG_REL_ ZR_MIB_TOP_ab_Gen3 SG_ 968 GE_Sumpftemperatur 2000;
BA_REL_ "GenSigTimeoutTime" BU_SG_REL_ ZR_MIB_TOP_ab_Gen3 SG_ 879 GNSS_Nachrichtenpaket_ID1 5000;
BA_REL_ "GenSigTimeoutTime" BU_SG_REL_ ZR_MIB_TOP_ab_Gen3 SG_ 879 GNSS_Breite_Ortung 5000;
BA_REL_ "GenSigTimeoutTime" BU_SG_REL_ ZR_MIB_TOP_ab_Gen3 SG_ 879 GNSS_Richtung_Breite_Ortung 5000;
BA_REL_ "GenSigTimeoutTime" BU_SG_REL_ ZR_MIB_TOP_ab_Gen3 SG_ 879 GNSS_Laenge_Ortung 5000;
BA_REL_ "GenSigTimeoutTime" BU_SG_REL_ ZR_MIB_TOP_ab_Gen3 SG_ 879 GNSS_Richtung_Laenge_Ortung 5000;
BA_REL_ "GenSigTimeoutTime" BU_SG_REL_ ZR_MIB_TOP_ab_Gen3 SG_ 879 GNSS_Ortung_FIX_Typ 5000;
BA_REL_ "GenSigTimeoutTime" BU_SG_REL_ ZR_MIB_TOP_ab_Gen3 SG_ 879 GNSS_Fehlerzustand 5000;
BA_REL_ "GenSigTimeoutTime" BU_SG_REL_ ZR_MIB_TOP_ab_Gen3 SG_ 884 GNSS_Nachrichtenpaket_ID2 5000;
BA_REL_ "GenSigTimeoutTime" BU_SG_REL_ ZR_MIB_TOP_ab_Gen3 SG_ 884 GNSS_Ortung_Latenz 5000;
BA_REL_ "GenSigTimeoutTime" BU_SG_REL_ ZR_MIB_TOP_ab_Gen3 SG_ 884 GNSS_Ortung_Ausrichtung 5000;
BA_REL_ "GenSigTimeoutTime" BU_SG_REL_ ZR_MIB_TOP_ab_Gen3 SG_ 884 GNSS_Ortung_2D_Geschw_ue_Grund 5000;
BA_REL_ "GenSigTimeoutTime" BU_SG_REL_ ZR_MIB_TOP_ab_Gen3 SG_ 884 GNSS_Ortung_Noerdliche_Geschw 5000;
BA_REL_ "GenSigTimeoutTime" BU_SG_REL_ ZR_MIB_TOP_ab_Gen3 SG_ 884 GNSS_Ortung_Oestliche_Geschw 5000;
BA_REL_ "GenSigTimeoutTime" BU_SG_REL_ ZR_MIB_TOP_ab_Gen3 SG_ 884 GNSS_Ortung_Vertikale_Geschw 5000;
BA_REL_ "GenSigTimeoutTime" BU_SG_REL_ ZR_MIB_TOP_ab_Gen3 SG_ 886 GNSS_Nachrichtenpaket_ID3 5000;
BA_REL_ "GenSigTimeoutTime" BU_SG_REL_ ZR_MIB_TOP_ab_Gen3 SG_ 886 GNSS_Ortung_GDOP 5000;
BA_REL_ "GenSigTimeoutTime" BU_SG_REL_ ZR_MIB_TOP_ab_Gen3 SG_ 886 GNSS_Ortung_PDOP 5000;
BA_REL_ "GenSigTimeoutTime" BU_SG_REL_ ZR_MIB_TOP_ab_Gen3 SG_ 886 GNSS_Ortung_HDOP 5000;
BA_REL_ "GenSigTimeoutTime" BU_SG_REL_ ZR_MIB_TOP_ab_Gen3 SG_ 886 GNSS_Ortung_VDOP 5000;
BA_REL_ "GenSigTimeoutTime" BU_SG_REL_ ZR_MIB_TOP_ab_Gen3 SG_ 886 GNSS_Ortung_Guete_Geschwindigk 5000;
BA_REL_ "GenSigTimeoutTime" BU_SG_REL_ ZR_MIB_TOP_ab_Gen3 SG_ 886 GNSS_Ortung_Guete_Ausrichtung 5000;
BA_REL_ "GenSigTimeoutTime" BU_SG_REL_ ZR_MIB_TOP_ab_Gen3 SG_ 886 GNSS_Ortung_Guete_horizontal 5000;
BA_REL_ "GenSigTimeoutTime" BU_SG_REL_ ZR_MIB_TOP_ab_Gen3 SG_ 886 GNSS_Ortung_Guete_vertikal 5000;
BA_REL_ "GenSigTimeoutTime" BU_SG_REL_ ZR_MIB_TOP_ab_Gen3 SG_ 888 GNSS_Nachrichtenpaket_ID4 5000;
BA_REL_ "GenSigTimeoutTime" BU_SG_REL_ ZR_MIB_TOP_ab_Gen3 SG_ 888 GNSS_Ortung_Zeit_in_GPSWoche 5000;
BA_REL_ "GenSigTimeoutTime" BU_SG_REL_ ZR_MIB_TOP_ab_Gen3 SG_ 888 GNSS_Ortung_Hoehe 5000;
BA_REL_ "GenSigTimeoutTime" BU_SG_REL_ ZR_MIB_TOP_ab_Gen3 SG_ 891 GNSS_UTC_Zeit 5000;
BA_REL_ "GenSigTimeoutTime" BU_SG_REL_ ZR_MIB_TOP_ab_Gen3 SG_ 891 GNSS_Empfaenger_Status 5000;
BA_REL_ "GenSigTimeoutTime" BU_SG_REL_ ZR_MIB_TOP_ab_Gen3 SG_ 891 GNSS_GPS_in_Nutzung 5000;
BA_REL_ "GenSigTimeoutTime" BU_SG_REL_ ZR_MIB_TOP_ab_Gen3 SG_ 891 GNSS_GLONASS_in_Nutzung 5000;
BA_REL_ "GenSigTimeoutTime" BU_SG_REL_ ZR_MIB_TOP_ab_Gen3 SG_ 891 GNSS_Empfangbare_Satelliten 5000;
BA_REL_ "GenSigTimeoutTime" BU_SG_REL_ ZR_MIB_TOP_ab_Gen3 SG_ 891 GNSS_Sichtbare_Satelliten 5000;
BA_REL_ "GenSigTimeoutTime" BU_SG_REL_ ZR_MIB_TOP_ab_Gen3 SG_ 891 GNSS_Genutzte_Satelliten 5000;
BA_REL_ "GenSigTimeoutTime" BU_SG_REL_ ZR_MIB_TOP_ab_Gen3 SG_ 891 GNSS_Nachrichtenpaket_ID5 5000;
BA_REL_ "GenSigTimeoutTime" BU_SG_REL_ ZR_MIB_TOP_ab_Gen3 SG_ 1364 GNSS_Sat_Info_Sat_ID_1 5000;
BA_REL_ "GenSigTimeoutTime" BU_SG_REL_ ZR_MIB_TOP_ab_Gen3 SG_ 1364 GNSS_Sat_Info_SNR_ID_1 5000;
BA_REL_ "GenSigTimeoutTime" BU_SG_REL_ ZR_MIB_TOP_ab_Gen3 SG_ 1364 GNSS_Sat_Info_Azimuth_ID_1 5000;
BA_REL_ "GenSigTimeoutTime" BU_SG_REL_ ZR_MIB_TOP_ab_Gen3 SG_ 1364 GNSS_Sat_Info_Hoehenwinkel_ID_1 5000;
BA_REL_ "GenSigTimeoutTime" BU_SG_REL_ ZR_MIB_TOP_ab_Gen3 SG_ 1364 GNSS_Nachrichtenpaket_ID6 5000;
BA_REL_ "GenSigTimeoutTime" BU_SG_REL_ ZR_MIB_TOP_ab_Gen3 SG_ 310 HAL_Radwinkel 1000;
BA_REL_ "GenSigTimeoutTime" BU_SG_REL_ ZR_Standard SG_ 795 ESP_Wegimp_VA 500;
BA_REL_ "GenSigTimeoutTime" BU_SG_REL_ ZR_Standard SG_ 795 ESP_Fehlerstatus_Wegimp 500;
BA_REL_ "GenSigTimeoutTime" BU_SG_REL_ ZR_Standard SG_ 795 ESP_Wegimp_Ueberlauf 500;
BA_REL_ "GenSigTimeoutTime" BU_SG_REL_ ZR_Standard SG_ 795 ESP_QBit_Wegimp_VA 500;
BA_REL_ "GenSigTimeoutTime" BU_SG_REL_ ZR_Standard SG_ 795 ESP_HDC_Regelgeschw 500;
BA_REL_ "GenSigTimeoutTime" BU_SG_REL_ ZR_Standard SG_ 707 FDR_M_HL_02 800;
BA_REL_ "GenSigTimeoutTime" BU_SG_REL_ ZR_Standard SG_ 707 FDR_M_HR_02 800;
BA_REL_ "GenSigTimeoutTime" BU_SG_REL_ ZR_Standard SG_ 707 FDR_M_VL_02 800;
BA_REL_ "GenSigTimeoutTime" BU_SG_REL_ ZR_Standard SG_ 707 FDR_M_VR_02 800;
BA_REL_ "GenSigTimeoutTime" BU_SG_REL_ ZR_Standard SG_ 968 GE_Sumpftemperatur 2000;
BA_REL_ "GenSigTimeoutTime" BU_SG_REL_ ZR_Standard SG_ 879 GNSS_Nachrichtenpaket_ID1 5000;
BA_REL_ "GenSigTimeoutTime" BU_SG_REL_ ZR_Standard SG_ 879 GNSS_Breite_Ortung 5000;
BA_REL_ "GenSigTimeoutTime" BU_SG_REL_ ZR_Standard SG_ 879 GNSS_Richtung_Breite_Ortung 5000;
BA_REL_ "GenSigTimeoutTime" BU_SG_REL_ ZR_Standard SG_ 879 GNSS_Laenge_Ortung 5000;
BA_REL_ "GenSigTimeoutTime" BU_SG_REL_ ZR_Standard SG_ 879 GNSS_Richtung_Laenge_Ortung 5000;
BA_REL_ "GenSigTimeoutTime" BU_SG_REL_ ZR_Standard SG_ 879 GNSS_Ortung_FIX_Typ 5000;
BA_REL_ "GenSigTimeoutTime" BU_SG_REL_ ZR_Standard SG_ 879 GNSS_Fehlerzustand 5000;
BA_REL_ "GenSigTimeoutTime" BU_SG_REL_ ZR_Standard SG_ 884 GNSS_Nachrichtenpaket_ID2 5000;
BA_REL_ "GenSigTimeoutTime" BU_SG_REL_ ZR_Standard SG_ 884 GNSS_Ortung_Latenz 5000;
BA_REL_ "GenSigTimeoutTime" BU_SG_REL_ ZR_Standard SG_ 884 GNSS_Ortung_Ausrichtung 5000;
BA_REL_ "GenSigTimeoutTime" BU_SG_REL_ ZR_Standard SG_ 884 GNSS_Ortung_2D_Geschw_ue_Grund 5000;
BA_REL_ "GenSigTimeoutTime" BU_SG_REL_ ZR_Standard SG_ 884 GNSS_Ortung_Noerdliche_Geschw 5000;
BA_REL_ "GenSigTimeoutTime" BU_SG_REL_ ZR_Standard SG_ 884 GNSS_Ortung_Oestliche_Geschw 5000;
BA_REL_ "GenSigTimeoutTime" BU_SG_REL_ ZR_Standard SG_ 884 GNSS_Ortung_Vertikale_Geschw 5000;
BA_REL_ "GenSigTimeoutTime" BU_SG_REL_ ZR_Standard SG_ 886 GNSS_Nachrichtenpaket_ID3 5000;
BA_REL_ "GenSigTimeoutTime" BU_SG_REL_ ZR_Standard SG_ 886 GNSS_Ortung_GDOP 5000;
BA_REL_ "GenSigTimeoutTime" BU_SG_REL_ ZR_Standard SG_ 886 GNSS_Ortung_PDOP 5000;
BA_REL_ "GenSigTimeoutTime" BU_SG_REL_ ZR_Standard SG_ 886 GNSS_Ortung_HDOP 5000;
BA_REL_ "GenSigTimeoutTime" BU_SG_REL_ ZR_Standard SG_ 886 GNSS_Ortung_VDOP 5000;
BA_REL_ "GenSigTimeoutTime" BU_SG_REL_ ZR_Standard SG_ 886 GNSS_Ortung_Guete_Geschwindigk 5000;
BA_REL_ "GenSigTimeoutTime" BU_SG_REL_ ZR_Standard SG_ 886 GNSS_Ortung_Guete_Ausrichtung 5000;
BA_REL_ "GenSigTimeoutTime" BU_SG_REL_ ZR_Standard SG_ 886 GNSS_Ortung_Guete_horizontal 5000;
BA_REL_ "GenSigTimeoutTime" BU_SG_REL_ ZR_Standard SG_ 886 GNSS_Ortung_Guete_vertikal 5000;
BA_REL_ "GenSigTimeoutTime" BU_SG_REL_ ZR_Standard SG_ 888 GNSS_Nachrichtenpaket_ID4 5000;
BA_REL_ "GenSigTimeoutTime" BU_SG_REL_ ZR_Standard SG_ 888 GNSS_Ortung_Zeit_in_GPSWoche 5000;
BA_REL_ "GenSigTimeoutTime" BU_SG_REL_ ZR_Standard SG_ 888 GNSS_Ortung_Hoehe 5000;
BA_REL_ "GenSigTimeoutTime" BU_SG_REL_ ZR_Standard SG_ 891 GNSS_UTC_Zeit 5000;
BA_REL_ "GenSigTimeoutTime" BU_SG_REL_ ZR_Standard SG_ 891 GNSS_Empfaenger_Status 5000;
BA_REL_ "GenSigTimeoutTime" BU_SG_REL_ ZR_Standard SG_ 891 GNSS_GPS_in_Nutzung 5000;
BA_REL_ "GenSigTimeoutTime" BU_SG_REL_ ZR_Standard SG_ 891 GNSS_GLONASS_in_Nutzung 5000;
BA_REL_ "GenSigTimeoutTime" BU_SG_REL_ ZR_Standard SG_ 891 GNSS_Empfangbare_Satelliten 5000;
BA_REL_ "GenSigTimeoutTime" BU_SG_REL_ ZR_Standard SG_ 891 GNSS_Sichtbare_Satelliten 5000;
BA_REL_ "GenSigTimeoutTime" BU_SG_REL_ ZR_Standard SG_ 891 GNSS_Genutzte_Satelliten 5000;
BA_REL_ "GenSigTimeoutTime" BU_SG_REL_ ZR_Standard SG_ 891 GNSS_Nachrichtenpaket_ID5 5000;
BA_REL_ "GenSigTimeoutTime" BU_SG_REL_ ZR_Standard SG_ 1364 GNSS_Sat_Info_Sat_ID_1 5000;
BA_REL_ "GenSigTimeoutTime" BU_SG_REL_ ZR_Standard SG_ 1364 GNSS_Sat_Info_SNR_ID_1 5000;
BA_REL_ "GenSigTimeoutTime" BU_SG_REL_ ZR_Standard SG_ 1364 GNSS_Sat_Info_Azimuth_ID_1 5000;
BA_REL_ "GenSigTimeoutTime" BU_SG_REL_ ZR_Standard SG_ 1364 GNSS_Sat_Info_Hoehenwinkel_ID_1 5000;
BA_REL_ "GenSigTimeoutTime" BU_SG_REL_ ZR_Standard SG_ 1364 GNSS_Nachrichtenpaket_ID6 5000;
VAL_ 795 ESP_Lampe 0 "Aus" 1 "Ein" ;
VAL_ 795 ABS_Lampe 0 "Aus" 1 "Ein" ;
VAL_ 795 BK_Lampe_02 0 "aus" 1 "Typ1_ein_statisch" 2 "Typ2_ein_statisch" 3 "Warnung" ;
VAL_ 795 TC_Lampe 0 "Aus" 1 "Ein" ;
VAL_ 795 ESP_m_Raddrehz 32765 "Unterspannung" 32766 "Init" 32767 "Fehler" ;
VAL_ 795 ESP_Textanzeigen_03 0 "kein_Text" 1 "ESP_Stoerung" 2 "ABS_Stoerung" 3 "ESP_ABS_Stoerung" 4 "Werkstatt_Bremse" 5 "ASR_Stoerung" 6 "ESP_switched_off" 7 "ASR_off" 8 "ESP_ASR_on" 10 "keine_Bremskraftverstaerkung" 11 "ASR_aktiviert" 12 "ABS_ASR_Stoerung" 15 "ESP_offroad" 17 "ESP_sport" 18 "ESP_Zwangsaktivierung" 19 "ESP_Taster_Info" 20 "TC_aktiv" 21 "reserviert_fuer_Verlwarn" 22 "TC_switched_off" 23 "Verlwarn_akt_Rollsicher_inakt" 24 "ESP_SuperSport" 25 "ESP_Offroad_nicht_verfuegbar" ;
VAL_ 795 ESP_Meldungen 0 "keine_Anzeige" 1 "Autohold_Hinweis_1" 2 "Stoerung_Autohold" 3 "Stoerung_Hillholder" 4 "Uebernehmen" 5 "Autohold_aus" 6 "Autohold_Hinweis_2" ;
VAL_ 795 ESP_Fehlerstatus_Wegimp 0 "Wegimpulse_iO" 1 "Fehler" ;
VAL_ 795 ESP_Wegimp_Ueberlauf 0 "Reset_und_kein_Ueberlauf" 1 "mindestens_1x_Ueberlauf" ;
VAL_ 795 ESP_QBit_Wegimp_VA 0 "gueltiger_Wert" 1 "Ersatz_Init_oder_Fehlerwert" ;
VAL_ 795 ESP_HDC_Geschw_Farbe 0 "Standard_Farbe" 1 "abweichende_Farbe" ;
VAL_ 795 ESP_Off_Lampe 0 "Lampe_aus" 1 "Lampe_ein" ;
VAL_ 795 ESP_HDC_Regelgeschw 0 "nicht_verbaut" 125 "HDC_Standby" 126 "Init" 127 "Fehler" ;
VAL_ 795 ESP_BKV_Warnung 0 "keine_Anzeige" 1 "keine_Bremskraftverstaerkung" ;
VAL_ 508 ESP_Status_Bremsentemp_02 0 "nicht_erhoeht" 1 "Schwelle_1" 2 "Schwelle_2" ;
VAL_ 508 ESP_Aggregataktivitaet 0 "inaktiv" 1 "aktiv" ;
VAL_ 508 ESP_Stillstandsflag 0 "kein_Stillstand_erkannt" 1 "Stillstand_erkannt" ;
VAL_ 508 ESC_MBK_Meldungen 0 "kein_Text" 1 "MBK_Hinweis_aktiv" 2 "MBK_Eskalation1_aktiv" ;
VAL_ 508 ESP_EDS_Anzeige 0 "Keine_Anzeige_aktiv" 1 "EDS_nicht_aktiv" 2 "EDS_aktiv_an_VA" 3 "EDS_aktiv_an_HA" 4 "EDS_aktiv_an_VA_und_HA" 5 "EDS_Uebertemperatur" 6 "EDS_Fehler" ;
VAL_ 508 RLE_Anzeigen 0 "keine_Anzeige" 1 "Rad_lose_allgemein" 2 "Rad_VL_lose" 3 "Rad_VR_lose" 4 "Rad_HL_lose" 5 "Rad_HR_lose" 6 "RLE_Pruefphase" 7 "RLE_Systemstoerung" ;
VAL_ 508 ESP_Wiederstart_Anz_Std 0 "keine_Anzeige" 1 "Standard_Wiederstartgrund" ;
VAL_ 508 ESC_Anforderung_Airbrake 0 "keine_Anforderung" 1 "Anf_Bremsperformancestellung" ;
VAL_ 508 ESC_FBA_Meldungen 0 "kein_Text" 1 "FBA_Warnung_aktiv_MT" 2 "FBA_Warnung_aktiv_AT" ;
VAL_ 508 ESP_Rollover_Status_dyn 0 "Auspraegung1" 1 "Auspraegung2" 2 "Auspraegung3" 3 "Auspraegung4" ;
VAL_ 508 ESP_Rollover_Status_stat 0 "Auspraegung1" 1 "Auspraegung2" 2 "Auspraegung3" 3 "Auspraegung4" ;
VAL_ 508 ESP_AVH_LED 0 "LED_aus" 1 "LED_ein" 2 "LED_blinken" 3 "Funktion_gesperrt__LED_aus" 6 "Init" ;
VAL_ 508 ESP_HDC_LED 0 "LED_aus" 1 "LED_ein" 2 "LED_blinken" 3 "Funktion_gesperrt__LED_aus" 6 "Init" ;
VAL_ 508 ESP_Off_LED 0 "LED_aus" 1 "LED_ein" 2 "LED_blinken" 3 "Funktion_gesperrt__LED_aus" 6 "Init" ;
VAL_ 508 ESP_Notbremsanzeige 0 "keine_Notbremsung_erkannt" 1 "Notbremsung_erkannt" ;
VAL_ 508 ESC_Motorstartverzoegerung 0 "Startfreigabe" 1 "Anforderung_Startverzoegerung" ;
VAL_ 508 ESP_Offroad_Lampe 0 "Aus" 1 "Ein" ;
VAL_ 508 ESP_HDC_Textanzeigen 0 "kein_Text" 1 "HDC_ein" 2 "HDC_aus" 3 "HDC_nicht_verfuegbar_in_FahrPr" 4 "HDC_nicht_verfuegbar_Uebertemp" 5 "HDC_verfuegbar_keine_Uebertemp" 6 "HDC_nicht_verfuegbar_ACC_aktiv" 7 "HDC_nicht_verfuegbar_GRA_aktiv" 8 "HDC_nicht_verfuegbar_LIM_aktiv" 9 "HDC_nicht_verfuegbar_IPA_aktiv" 10 "HDC_nicht_verfuegbar_PLA_aktiv" 11 "HDC_nicht_verf_anderes_Syst_akt" 12 "HDC_nicht_verfuegbar_Fehler" 13 "GRA_Hebel_einschalten" 14 "Funk_nicht_verfuegbar_bei_HDC" 15 "Funk_verfuegbar_wenn_HDC_aktiv" 16 "Deaktivierung_ESP_Eingriff" 17 "HDC_nicht_verfuegbar_ABS_solo" 18 "HDC_nicht_verfuegbar_Gaspedal" ;
VAL_ 508 ESP_HOLD_verf 0 "nicht_verfuegbar" 1 "verfuegbar" ;
VAL_ 600 ESP_DriftLevel 0 "Init" 1 "Level_1" 2 "Level_2" 3 "Level_3" 4 "Level_4" 5 "Level_5" 6 "Not_Available" ;
VAL_ 600 ESP_DriftText 0 "Text_1" 1 "Text_2" 2 "Text_3" 3 "Text_4" 4 "Text_5" 5 "Text_6" 6 "Text_7" 7 "Text_8" 8 "Text_9" 9 "Text_10" ;
VAL_ 600 ESP_DriftStatus 0 "Not_active" 1 "Active" ;
VAL_ 600 ESP_DriftGong 0 "Not_Active" 1 "Active" ;
VAL_ 600 ESP_Slider_Text 0 "Text_1" 1 "Text_2" 2 "Text_3" 3 "Text_4" 4 "Text_5" 5 "Text_6" 6 "Text_7" 7 "Text_8" 8 "Text_9" 9 "Text_10" ;
VAL_ 600 ESP_Slider_Lamp 0 "Lamp_off" 1 "Lamp_on" ;
VAL_ 600 ESP_Slider_Gong 0 "Not_Active" 1 "Active" ;
VAL_ 600 ESP_Slider_Status 0 "Not_active" 1 "Active" 2 "Disabled" ;
VAL_ 600 ESP_Slider_ist_01 127 "invalid" ;
VAL_ 600 ESP_Slider_ist_02 127 "invalid" ;
VAL_ 600 ESP_Slider_ist_03 127 "invalid" ;
VAL_ 264 FA_Hoehenwerte_kalibriert 0 "kalibrierte_Hoehenwerte_in_mm" 1 "Rohwerte" ;
VAL_ 264 EFP_Anf_Bremsenkuehlung 0 "keine_Anforderung" 1 "SKE_oeffnen" 2 "SKE_oeffnen_Luefter_ansteuern" ;
VAL_ 264 FA_Hoehenwert_VL_00 254 "nicht initialisiert" 255 "Fehler" ;
VAL_ 264 FA_Hoehenwert_VR_00 254 "nicht initialisiert" 255 "Fehler" ;
VAL_ 264 FA_Hoehenwert_HL_00 254 "nicht initialisiert" 255 "Fehler" ;
VAL_ 264 FA_Hoehenwert_HR_00 254 "nicht initialisiert" 255 "Fehler" ;
VAL_ 264 FA_Fahrbahnunebenheit 254 "Init" 255 "Fehler" ;
VAL_ 264 EFP_Reibwert_dyn 62 "Init" 63 "Fehler" ;
VAL_ 2527679659 FA_Niveau_Druck_HL 255 "Fehler" ;
VAL_ 2527679659 FA_Niveau_Druck_HR 255 "Fehler" ;
VAL_ 2527679659 FA_Niveau_Druck_VL 255 "Fehler" ;
VAL_ 2527679659 FA_Niveau_Druck_VR 255 "Fehler" ;
VAL_ 429 NR_Reglerstatus 0 "nicht_definiert" 1 "Hochniveau_2" 2 "Hochniveau_1" 3 "Zwischenniveau" 4 "Normalniveau" 5 "Tiefniveau_1" 6 "Tiefniveau_2" 7 "Tiefniveau_3" 8 "Verladeniveau" 9 "Beladungsniveau" 10 "Heckabsenkung" ;
VAL_ 429 FA_Verstellung_in_Kuerze 0 "keine_Verstellung_erwartet" 1 "Verstellung_erwartet" ;
VAL_ 429 FA_Verstellung_aktiv 0 "keine_Verstellung" 1 "Verstellung_aktiv" ;
VAL_ 429 FA_Kompressor_laeuft_in_Kuerze 0 "kein_Kompressorlauf_erwartet" 1 "Kompressorlauf_steht_bevor" ;
VAL_ 429 FA_Kompressor_laeuft 0 "Kompressor_nicht_angesteuert" 1 "Kompressor_angesteuert" ;
VAL_ 429 NR_Anforderung_v_Begrenzung 0 "keine_Begrenzung_angefordert" 1 "Sicherheitsbegrenzung_1_aktiv" 2 "Sicherheitsbegrenzung_2_aktiv" 3 "Komfortbegrenzung_aktiv" ;
VAL_ 429 NR_LED_SGN 0 "LED_aus" 1 "LED_ein" ;
VAL_ 429 NR_LED_TN 0 "LED_aus" 1 "LED_ein" ;
VAL_ 429 NR_LED_BN 0 "LED_aus" 1 "LED_ein" ;
VAL_ 429 FA_Absenkung_Fahrzeug 0 "keine_Absenkung" 1 "Absenkung_Fahrzeug" ;
VAL_ 429 FA_Anhaengerstatus_intern 0 "Anhaenger_intern_nicht_erkannt" 1 "Anhaenger_intern_erkannt_manuell" 2 "Anhaenger_intern_erkannt_automatisch" 3 "Anhaenger_intern_erkannt_automatisch_manuelle_Deaktivierung_aktiv" 4 "Anhaenger_intern_erkannt_Failsafe" ;
VAL_ 429 FA_Anhebung_Fahrzeug 0 "keine_Anhebung" 1 "Anhebung_Fahrzeug" ;
VAL_ 429 FA_Druckspeicher_verfuegbar 0 "Druckspeicher_nicht_verfuegbar" 1 "Regelung_aus_Druckspeicher_moeglich" ;
VAL_ 429 FA_HAL_Abschaltung 0 "keine_Beeinflussung" 1 "Abschaltung_angefordert" ;
VAL_ 429 FA_ESP_Zuschaltung 0 "keine_ESP_Beeinflussung" 1 "ESP_Zwangszuschaltung_angefordert" ;
VAL_ 429 NR_LED_HN 0 "LED_aus" 1 "LED_ein" ;
VAL_ 429 FA_Zwischenniveau 0 "kein_Zwischenniveau" 1 "Zwischenniveau" ;
VAL_ 429 FA_Systemstatus 0 "nicht_funktionsfaehig" 1 "funktionsfaehig" ;
VAL_ 429 EFP_Soll_FahrPr_HAL 0 "nicht_gesteuert" 1 "Zwang_Programm_1" 2 "Zwang_Programm_2" 3 "Zwang_Programm_3" 4 "Zwang_Programm_4" 5 "Zwang_Programm_5" 6 "Zwang_Programm_6" 7 "Zwang_Programm_7" 8 "Zwang_Programm_8" 9 "Zwang_Programm_9" 10 "Zwang_Programm_10" 11 "Zwang_Programm_11" 12 "Zwang_Programm_12" 13 "Zwang_Programm_13" 14 "Zwang_Programm_14" 15 "Zwang_Programm_15" ;
VAL_ 429 NR_Kompressor_Strom_02 255 "Fehler" ;
VAL_ 429 NR_Kompressor_Temp_Zylinderkopf 254 "Init" 255 "Fehler" ;
VAL_ 429 FA_Signal_Drucksensor 254 "Init" 255 "Fehler" ;
VAL_ 2527679658 FA_FahrerAnf_Fahrwerk 0 "KeinFahrerAnf_Fahrwerk" 1 "FahrerAnf_FahrwerkNormal" 2 "FahrerAnf_FahrwerkSport" 3 "FahrerAnf_FahrwerkSportPlus" ;
VAL_ 2527679658 FA_FahrerAnf_Lift 0 "KeinFahrerAnf_Lift" 1 "FahrerAnf_Lift" ;
VAL_ 2527679658 FA_FahrerAnf_Niveau 0 "KeinFahrerAnf_Niveau" 1 "FahrerAnf_NiveauSGN" 2 "FahrerAnf_NiveauGN" 3 "FahrerAnf_NiveauNN" 4 "FahrerAnf_NiveauTN" 5 "FahrerAnf_NiveauBN" ;
VAL_ 2527679658 EFP_ReifenTemp_HL 63 "Init" ;
VAL_ 2527679658 EFP_ReifenTemp_HR 63 "Init" ;
VAL_ 2527679658 EFP_ReifenTemp_VL 63 "Init" ;
VAL_ 2527679658 EFP_ReifenTemp_VR 63 "Init" ;
VAL_ 2527679658 FA_Beladung_HA 14 "Init" 15 "Fehler" ;
VAL_ 2527679658 FA_Beladung_VA 14 "Init" 15 "Fehler" ;
VAL_ 2527679896 EFP_ReifenTempOf_VL 63 "Init" ;
VAL_ 2527679896 EFP_ReifenTempOf_VR 63 "Init" ;
VAL_ 2527679896 EFP_ReifenTempOf_HL 63 "Init" ;
VAL_ 2527679896 EFP_ReifenTempOf_HR 63 "Init" ;
VAL_ 2527679896 FA_FahrerAnf_Lift_Abwurf 0 "KeinFahrerAnf_LiftAbwurf" 1 "FahrerAnf_LiftAbwurf" ;
VAL_ 2527679896 FA_Niveau_AOCCT_timer2_verbaut 0 "not_current" 1 "installed_and_coded" ;
VAL_ 2527679896 FA_Niveau_AOCCT_timer2_count 0 "inactiv" 1 "active" ;
VAL_ 2527679896 FA_Niveau_AOCCT_timer1_verbaut 0 "not_current" 1 "installed_and_coded" ;
VAL_ 2527679896 FA_Niveau_AOCCT_timer1_count 0 "inactive" 1 "active" ;
VAL_ 2527679896 FA_Niveau_AOCCT_teststatus 0 "diag_incomplete" 1 "diag_complete" ;
VAL_ 2527679896 FA_Niveau_AOCCT_fehlerstatus 0 "no_failure" 1 "failure" ;
VAL_ 2527679896 FA_Zuladung_VA 62 "Init" 63 "Fehler" ;
VAL_ 2527679896 FA_Zuladung_HA 62 "Init" 63 "Fehler" ;
VAL_ 2527679896 FA_Zuladung_Status_VA 0 "Berechnung_nicht_erfolgt" 1 "Berechnung_FehlertoleranzHoch" 2 "Berechnung_FehlertoleranzNiedrig" ;
VAL_ 2527679896 FA_Zuladung_Status_HA 0 "Berechnung_nicht_erfolgt" 1 "Berechnung_FehlertoleranzHoch" 2 "Berechnung_FehlertoleranzNiedrig" ;
VAL_ 2331595995 EFP_FVertDisp_VR 254 "Init" 255 "Fehler" ;
VAL_ 2331595995 EFP_FVertDisp_VL 254 "Init" 255 "Fehler" ;
VAL_ 2331595995 EFP_FVertDisp_HR 254 "Init" 255 "Fehler" ;
VAL_ 2331595995 EFP_FVertDisp_HL 254 "Init" 255 "Fehler" ;
VAL_ 705 EFP_Verbau_DR 0 "nicht_verbaut" 1 "verbaut" ;
VAL_ 705 EFP_Verbau_eAllrad 0 "nicht_verbaut" 1 "verbaut" ;
VAL_ 705 EFP_Verbau_LF 0 "nicht_verbaut" 1 "verbaut" ;
VAL_ 705 LF_Texte 0 "keine_Anzeige" 1 "Text_Fahrzeug_momentan_zu_tief_Regelung_laeuft" 2 "Text_Fahrzeug_momentan_zu_hoch_Regelung_laeuft" 3 "Text_Niveauregelung_abgeschaltet" ;
VAL_ 705 EFP_Verbau_eAWS 0 "nicht_verbaut" 1 "verbaut" ;
VAL_ 705 eAWS_Warnmeldung_Prio1 0 "keine_Anzeige" 1 "kritische_Fehlermeldung" ;
VAL_ 705 eAWS_Warnmeldung_Prio2 0 "keine_Anzeige" 1 "milde_Fehlermeldung" ;
VAL_ 705 LF_Texte_2 0 "Init" 1 "keine_Anzeige" 2 "Text_Fahrzeug_Anheben_angeforder" 3 "Text_Fahrzeug_Absenken_angeforde" 4 "reserviert" 5 "reserviert" 6 "reserviert" 7 "reserviert" 8 "reserviert" 9 "reserviert" 10 "reserviert" 11 "reserviert" 12 "reserviert" 13 "reserviert" 14 "reserviert" 15 "reserviert" ;
VAL_ 705 EFP_Status_Taster_Lift 0 "Keine_Anzeige" 1 "Status1" 2 "Status2" 3 "Status3" ;
VAL_ 705 EFP_Status_Taster_Fahrwerk 0 "Keine_Anzeige" 1 "Status1" 2 "Status2" 3 "Status3" ;
VAL_ 705 FDR_Warnung_ALR 0 "keine_Anzeige" 1 "Text_Stoerung_Allradverteilung" 2 "Text_Ausfall_Allradverteilung" 3 "reserved" ;
VAL_ 705 FDR_Warnung_TV 0 "keine_Anzeige" 1 "Text_Stoerung_TorqueVectoring" 2 "Text_Ausfall_TorqueVectoring" 3 "reserviert" ;
VAL_ 705 EFP_Verbau_eABC 0 "nicht_verbaut" 1 "verbaut" ;
VAL_ 705 LF_Warnung_Prio1_02 0 "keine_Anzeige" 1 "Text_Servicemodus" 2 "Text_Fehler_Luftfeder_Geschwindigkeit_1" 3 "Text_Fehler_Luftfeder_Geschwindigkeit_2" 4 "Text_Fehler_Luftfeder_Begrenzung_v_1" 5 "Text_Fehler_Luftfeder_Begrenzung_v_2" 6 "Text_Fehler_LuFe_Fzg_abstellen" ;
VAL_ 705 LF_Warnung_Prio1 0 "keine_Anzeige" 1 "Text_Servicemodus" 2 "Text_Fehler_Luftfeder_Geschwindigkeit_1" 3 "Text_Fehler_Luftfeder_Geschwindigkeit_2" ;
VAL_ 705 LF_Warnung_Prio2 0 "keine_Anzeige" 1 "Text_Fahrzeug_zu_tief_Bodenfreiheit_eingeschraenkt" 2 "Text_Fehler_Luftfeder" 3 "tbd" ;
VAL_ 705 eABC_Warnung_Prio2 0 "keine_Anzeige" 1 "Text_Stoerung_eABC_service_aufsuchen" 2 "Text_Stoerung_eABC_Bodenfreiheit_eingeschraenkt" 3 "Text_eABC_nicht_verfuegbar" ;
VAL_ 705 eABC_Warnung_Prio1 0 "keine_Anzeige" 1 "Text_Servicemodus" 2 "Text_Fehler_eABC_eingeschraenkte_Lenkbarkeit" 3 "Text_Fehler_eABC_eingeschraenkte_Fahrstabilitaet" 4 "Text_Fehler_eABC_eingeschraenkte_Geschwindigkeit" ;
VAL_ 705 eABC_Texte 0 "keine_Anzeige" 1 "Text_eABC_Vorausschau_nicht_verf" 2 "Text_eABC_Radwechselmodus" 3 "Text_eABC_Standfunktion_nicht_verfuegbar" 4 "Text_eABC_zur_Zeit_nicht_verfueg" 5 "Text_eABC_zur_Zeit_eingeschraenk" ;
VAL_ 705 DR_Warnung 0 "keine_Anzeige" 1 "Text_Fehler_Daempfer" ;
VAL_ 705 NR_LED_Offroadlevel 0 "LED_aus_und_Blinken_aus" 1 "LED_ein_und_Blinken_aus" 2 "LED_ein_und_Blinken_ein" 3 "Init" ;
VAL_ 705 NR_LED_Ladelevel 0 "LED_aus_und_Blinken_aus" 1 "LED_ein_und_Blinken_aus" 2 "LED_ein_und_Blinken_ein" 3 "Init" ;
VAL_ 705 NR_LED_Sync 0 "LED_aus_und_Blinken_aus" 1 "LED_ein_und_Blinken_aus" 2 "LED_ein_und_Blinken_ein" 3 "Init" ;
VAL_ 705 NR_LED_XtraLevel 0 "LED_aus_und_Blinken_aus" 1 "LED_ein_und_Blinken_aus" 2 "LED_ein_und_Blinken_ein" 3 "Init" ;
VAL_ 705 NR_LED_Strassenlevel 0 "LED_aus_und_Blinken_aus" 1 "LED_ein_und_Blinken_aus" 2 "LED_ein_und_Blinken_ein" 3 "Init" ;
VAL_ 705 EFP_Warnung_Naesse 0 "keine_Anzeige" 1 "Naesse_Meldung1" 2 "Naesse_Meldung2" 3 "Naesse_Meldung3" 4 "Naesse_Meldung4" 5 "Naesse_Meldung5" 6 "Naesse_Meldung6" 7 "Naesse_Meldung7" ;
VAL_ 705 EFP_Warnung_Naesse_verf 0 "verfuegbar" 1 "nicht_verfuegbar" ;
VAL_ 2463978619 FAS_SollStatus_Fkt_ASW 0 "Init" 1 "Funktion_ein" 2 "Funktion_aus" ;
VAL_ 2463978619 FAS_SollStatus_Fkt_SWA 0 "Init" 1 "Funktion_ein" 2 "Funktion_aus" ;
VAL_ 2463978619 FAS_SollStatus_Fkt_MKE 0 "Init" 1 "Funktion_ein" 2 "Funktion_aus" ;
VAL_ 2463978619 FAS_SollStatus_Fkt_NV 0 "Init" 1 "Funktion_ein" 2 "Funktion_aus" ;
VAL_ 2463978619 FAS_SollStatus_Fkt_AbstWarn_MV 0 "Init" 1 "Funktion_ein" 2 "Funktion_aus" ;
VAL_ 2463978619 FAS_SollStatus_Fkt_STP 0 "Init" 1 "Funktion_ein" 2 "Funktion_aus" ;
VAL_ 2463978619 FAS_SollStatus_Fkt_PreCrash 0 "Init" 1 "Funktion_ein" 2 "Funktion_aus" ;
VAL_ 2463978619 FAS_SollStatus_Fkt_LGI 0 "Init" 1 "Funktion_ein" 2 "Funktion_aus" ;
VAL_ 2463978619 FAS_SollStatus_Fkt_AbstWarn_LRR 0 "Init" 1 "Funktion_ein" 2 "Funktion_aus" ;
VAL_ 2527679660 FB_Kopfaktivitaet_A1 15 "Init" ;
VAL_ 2527679660 FB_Kopfaktivitaet_A2 15 "Init" ;
VAL_ 2527679660 FB_Blindheit 0 "nicht_erkannt" 1 "erkannt" ;
VAL_ 2527679660 FB_NichtVerfuegbar 0 "verfuegbar" 1 "nicht_verfuegbar" ;
VAL_ 2527679660 FB_Fahrerwechsel 0 "Fahrerwechsel_nicht_erkannt" 1 "Fahrerwechsel_erkannt" 3 "Init" ;
VAL_ 2527679660 FB_Fehler 0 "kein_Fehler" 1 "Fehler" ;
VAL_ 2527679660 FB_Muedigkeit_Index 255 "Init" ;
VAL_ 707 EFP_MomRad_Begr 4094 "Init" 4095 "Fehler" ;
VAL_ 707 FA_Warnung_Transportniveau 0 "keine_Anzeige" 1 "Warnung" ;
VAL_ 707 eAWS_Warnmeldung_Prio3 0 "keine_Anzeige" 1 "Hinweismeldung" ;
VAL_ 707 EFP_Anf_Kuehlklappenwarnung 0 "kein_Warnhinweis" 1 "Warnhinweis" ;
VAL_ 707 FDR_M_HL_02 252 "Darstellung_passiv" 253 "nicht_verbaut" 254 "Init" 255 "Fehler" ;
VAL_ 707 FDR_M_HR_02 252 "Darstellung_passiv" 253 "nicht_verbaut" 254 "Init" 255 "Fehler" ;
VAL_ 707 FDR_M_VL_02 252 "Darstellung_passiv" 253 "nicht_verbaut" 254 "Init" 255 "Fehler" ;
VAL_ 707 FDR_M_VR_02 252 "Darstellung_passiv" 253 "nicht_verbaut" 254 "Init" 255 "Fehler" ;
VAL_ 1605 FLA_aktiv 0 "inaktiv" 1 "aktiv" ;
VAL_ 1605 FLA_ISP_defekt 0 "iO" 1 "defekt" ;
VAL_ 1605 FLA_Sensor_blockiert 0 "Sensor in Ordnung" 1 "Sensor blockiert" ;
VAL_ 1605 FLA_Abblendursache 0 "nichts erkannt (Init-Wert) " 1 "enentgegenkommendes Fahrzeug (Scheinwerfer erkannt) " 2 "vorausfahrendes Fahrzeug (Heckleuchten erkannt) " 4 "Geschwindigkeitslimit unterschritten" 8 "Ortschaft_erkannt" 16 "Umgebungshelligkeit_generell_zu_hell" 32 "Nebel erkannt " 64 "Übertemperatur Imager" 128 "Verzögerungsbedingung" 255 "Fehler" ;
VAL_ 1605 FLA_Fernlicht_PWM 127 "Fehler" ;
VAL_ 1605 ISP_EC_Lichtwert_vorne 62 "Init" 63 "Fehler" ;
VAL_ 1605 ISP_EC_Lichtwert_hinten 62 "Init" 63 "Fehler" ;
VAL_ 1605 ISP_Himmelsrichtung 30 "nicht verfuegbar bzw. Init" 31 "Fehler" ;
VAL_ 1605 ISP_Taste_betaetigt 0 "nicht_betaetigt" 1 "betaetigt" ;
VAL_ 1605 ISP_EC_aktiv 0 "inaktiv" 1 "aktiv" ;
VAL_ 1605 ISP_Kompass_aktiv 0 "inaktiv" 1 "aktiv" ;
VAL_ 1605 FLA_Aufblenden 0 "nicht_aufblenden" 1 "aufblenden" ;
VAL_ 1605 FLA_SAE_Mode 0 "Init" 1 "FLA_Icon_invertiert" ;
VAL_ 2589283684 FoD_Transmission_Info 0 "Initwert" 1 "start_transmission" 2 "finish_transmission" ;
VAL_ 2589283684 FoD_Anz_Funktionsabschaltung 0 "Init" 1 "Popup_aufschalten" ;
VAL_ 173 GE_MMom_Soll_02 1022 "keine_Anforderung_Init" 1023 "Fehler" ;
VAL_ 173 GE_MMom_Vorhalt_02 1022 "Init" 1023 "Fehler" ;
VAL_ 173 GE_Uefkt 1023 "Fehler" ;
VAL_ 173 GE_Fahrstufe 0 "Zwischenstellung" 1 "Init" 5 "Position_P" 6 "Position_R" 7 "Position_N" 8 "Position_D" 9 "Position_S" 10 "Effizienz" 13 "Tipp_in_S" 14 "Tipp_in_D" 15 "Fehler" ;
VAL_ 173 GE_Schaltablauf 0 "keine_Schaltung" 1 "Momentenueberschneidung" 2 "Befuellphase" 3 "Drehzahlueberfuehrung" ;
VAL_ 173 GE_Uefkt_unplausibel 0 "Uefkt_plausibel" 1 "Uefkt_unplausibel" ;
VAL_ 173 GE_MMom_Status_02 0 "kein_Eingriff" 1 "abs_reduzierender_Eingriff_auf_Gesamt_Antrieb_nur_schneller_Pfad" 2 "abs_erhoehender_Eingriff_auf_Gesamt_Antrieb" 3 "relativer_Eingriff_auf_Gesamt_Antrieb" 4 "relativer_Eingriff_auf_E_Maschine" 5 "abs_red_Eingr_auf_Gesamt_Antrieb_nur_Luftpfad" 6 "abs_red_Eingr_auf_Gesamt_Antrieb_Luft-_und_schnellen_Pfad" 7 "abs_Eingriff_auf_Gesamtantrieb_erhoehend_und_reduzierend" ;
VAL_ 173 GE_Status_Kraftschluss 0 "offen_kein_Kraftschluss" 1 "offen_mit_Kraftschluss" 2 "schlupfend_geregelt" 3 "abgesichert_offen_kein_Kraftschl" 4 "geschlossen_mit_Mikroschlupf" 5 "geschlossen_mit_Ueberanpressung" 6 "sonstige_Fehler" 7 "fehlerhaft_geschlossen" ;
VAL_ 173 GE_MMom_Status 0 "keine Anforderung" 1 "reduzierender Getriebeeingriff" 2 "erhöhender Getriebeeingriff" 3 "Änderung mit Sprung" ;
VAL_ 173 GE_Freig_MMom_Vorhalt 0 "nicht_freigegeben" 1 "freigegeben" ;
VAL_ 173 GE_Verbot_Ausblendung 0 "kein_Verbot" 1 "Verbot" ;
VAL_ 173 GE_Zielgang 0 "Gang P/N (ausgekuppelt)" 1 "Gang 1" 2 "Gang 2" 3 "Gang 3" 4 "Gang 4" 5 "Gang 5" 6 "Gang 6" 7 "Gang 7" 8 "Gang R" 11 "Gang 8" 12 "Gang 9" 13 "Gang10" 14 "Istgang nicht definiert" 15 "Fehler" ;
VAL_ 968 GE_OBD_AbsperrVent 0 "kein Fehler / Init / nicht verbaut" 1 "KS- (Kurzschluss nach minus)" 2 "KS+ (Kurzschluss nach plus)" 3 "OC (Leitungsunterbrechung)" 4 "OOR+ (Signal zu gross)" 5 "OOR- (Signal zu klein)" 6 "RC+ (Signal unplausibel zu gross)" 7 "RC- (Signal unplausibel zu klein)" 8 "KS+/OC (Kurzschluss nach plus/Unterbrechung)" 9 "KS-/OC  (Kurzschluss nach minus/Unterbrechung)" 10 "KS-/KS+  (Kurzschluss nach minus/plus)" 11 "KS-/KS+/OC (Kurzschluss nach minus/plus/Unterbrechung)" 12 "Position_unbekannt" 13 "Failsafe_Position" 14 "Referenzfahrt_aktiv" 15 "frei" ;
VAL_ 968 GE_amax_moeglich 511 "nicht_definiert" ;
VAL_ 968 GE_Charisma_FahrPr 0 "keine_Funktion" 1 "Programm_1" 2 "Programm_2" 3 "Programm_3" 4 "Programm_4" 5 "Programm_5" 6 "Programm_6" 7 "Programm_7" 8 "Programm_8" 9 "Programm_9" 10 "Programm_10" 11 "Programm_11" 12 "Programm_12" 13 "Programm_13" 14 "Programm_14" 15 "Programm_15" ;
VAL_ 968 GE_Charisma_Status 0 "Init" 1 "verfuegbar" 2 "nicht_verfuegbar" 3 "asynchron_durch_Fahrerwunsch" ;
VAL_ 968 GE_Freigabe_Verfallsinfo_WFS 0 "Aus" 1 "Ein" ;
VAL_ 968 GE_LaunchControl_LB 0 "init" 1 "LC_not_available" 2 "LCperformance_not_possible" 3 "LCperformance_possible" 4 "LCperformance_armed" 5 "LCperformance_preparation" 6 "LCperformance_launch" 7 "LCperformance_aborted" 8 "LCsmoke_not_possible" 9 "LCsmoke_possible" 10 "LCsmoke_armed" 11 "LCsmoke_launch" 12 "LCsmoke_aborted" 13 "reserved" 14 "reserved" ;
VAL_ 968 GE_Status_PaddleNeutral 0 "Paddle_Neutral_inaktiv" 1 "Paddle_Neutral_aktiv" 2 "Paddle_Neutral_Ende_Timer_aktiv" 3 "Paddle_Neutral_Zwangsausstieg" ;
VAL_ 968 GE_Remotestart_Betrieb 0 "GSG_nicht_bereit_fuer_RS" 1 "GSG_bereit_fuer_oder_im_RS" ;
VAL_ 968 Freilauf_Charisma_FahrPr 0 "keine_Funktion" 1 "Programm_1" 2 "Programm_2" 3 "Programm_3" 4 "Programm_4" 5 "Programm_5" 6 "Programm_6" 7 "Programm_7" 8 "Programm_8" 9 "Programm_9" 10 "Programm_10" 11 "Programm_11" 12 "Programm_12" 13 "Programm_13" 14 "Programm_14" 15 "Programm_15" ;
VAL_ 968 Freilauf_Charisma_Status 0 "Init" 1 "verfuegbar" 2 "nicht_verfuegbar" 3 "asynchron_durch_Fahrerwunsch" ;
VAL_ 968 GE_Freigabe_Info_WFS 0 "ungueltig" 1 "gueltig" ;
VAL_ 968 GE_Sperr_Info_WFS 0 "nicht_gesperrt" 1 "gesperrt" ;
VAL_ 968 GE_Zustand_Kuppltemp 0 "Init" 1 "Kupplungstemp_normal" 2 "Kupplungstemp_hoch" 3 "Kupplungsschutz_aktivieren" ;
VAL_ 968 GE_Codierung_MSG 0 "Codierung iO / Init" 1 "Codierung niO" ;
VAL_ 968 GE_LaunchControl 0 "inaktiv" 1 "aktiv" ;
VAL_ 968 GE_Heizwunsch 0 "maximaler_Waermebedarf" 1 "kein_Waermebedarf" 2 "Kuehlbedarf" 3 "Notfall_(maximaler_Kuehlbedarf)" ;
VAL_ 968 GE_OBD_Status 0 "MIL aus" 1 "MIL ein" ;
VAL_ 968 GE_LFR_Adaption 0 "fuer_Adaption_geeignet" 1 "fuer_Adaption_nicht_geeignet" ;
VAL_ 968 GE_Sumpftemperatur 255 "Fehler" ;
VAL_ 177 GE_Fahrprogramm 0 "Init" 1 "nicht_belegt" 2 "Normal" 3 "Sport" 4 "Offroad" 5 "Efficiency" 6 "Sport_Plus" 7 "Sport_Response" 10 "Snow" 11 "Gravel" 12 "Mud_Ruts" 13 "Sand_Dune" ;
VAL_ 177 GE_TippZustand 0 "Init_Kein_Tipp" 1 "Tipp_permanent" 2 "Tipp_temporaer" ;
VAL_ 177 GE_Freilauf_Status 0 "Freilauf_inaktiv_aber_moeglich" 1 "Freilauf_aktiv" 2 "Freilauf_nicht_moegl_1Verhinderer" 3 "Freilauf_nicht_moegl_gr_1Verhinderer" 7 "Fehler" ;
VAL_ 177 GE_Grundeinstellung 0 "inaktiv" 1 "aktiv" ;
VAL_ 177 GE_Anschleppstart_Freigabe 0 "keine_Freigabe" 1 "Freigabe" ;
VAL_ 177 GE_Strombedarf_erh 0 "keine_Anforderung" 1 "erhoehte_Anforderung" ;
VAL_ 177 GE_Uefkt_Praed 16383 "Fehler" ;
VAL_ 177 GE_KomFehler_ESP 0 "kein_Fehler" 1 "Fehler" ;
VAL_ 177 GE_Rollrichtung_falsch 0 "richtige_Rollrichtung_o_Init" 1 "falsche_Rollrichtung" ;
VAL_ 177 GE_Getriebestatus_02 0 "inaktiv" 1 "Rennstartvorbereitung" 2 "Rennstart" 3 "Anfahrt" 4 "Anfahrt_Komfort" 5 "Anfahrt_Leerlaufregler" 6 "bereit_zur_Ueberanpressung" 7 "Low_Speed_Modus" 8 "eLaunch" ;
VAL_ 177 GE_Eingangsdrehz_Praed 16382 "Init" 16383 "Fehler" ;
VAL_ 879 GNSS_Breite_Ortung 134217726 "Init" 134217727 "Fehler" ;
VAL_ 879 GNSS_Richtung_Breite_Ortung 0 "Nord" 1 "Sued" ;
VAL_ 879 GNSS_Laenge_Ortung 268435454 "Init" 268435455 "Fehler" ;
VAL_ 879 GNSS_Richtung_Laenge_Ortung 0 "Ost" 1 "West" ;
VAL_ 879 GNSS_Ortung_FIX_Typ 0 "Init" 1 "No_Fix" 2 "2D_Fix" 3 "3D_Fix" ;
VAL_ 879 GNSS_Fehlerzustand 0 "Kein_Fehler" 1 "P_Mode" 2 "T_Mode" 3 "GNSS_Receiver_Problem" 4 "Kommunikationsproblem_im_SG" 5 "Start_GNSS_Receiver" 6 "GNSS_Receiver_aus" 7 "SG_spezifischer_Fehler" ;
VAL_ 884 GNSS_Ortung_Latenz 1022 "Init" 1023 "Fehler" ;
VAL_ 884 GNSS_Ortung_Ausrichtung 4094 "Init" 4095 "Fehler" ;
VAL_ 884 GNSS_Ortung_2D_Geschw_ue_Grund 510 "Init" 511 "Fehler" ;
VAL_ 884 GNSS_Ortung_Noerdliche_Geschw 1022 "Init" 1023 "Fehler" ;
VAL_ 884 GNSS_Ortung_Oestliche_Geschw 1022 "Init" 1023 "Fehler" ;
VAL_ 884 GNSS_Ortung_Vertikale_Geschw 1022 "Init" 1023 "Fehler" ;
VAL_ 886 GNSS_Ortung_GDOP 510 "Init" 511 "Fehler" ;
VAL_ 886 GNSS_Ortung_PDOP 510 "Init" 511 "Fehler" ;
VAL_ 886 GNSS_Ortung_HDOP 510 "Init" 511 "Fehler" ;
VAL_ 886 GNSS_Ortung_VDOP 510 "Init" 511 "Fehler" ;
VAL_ 886 GNSS_Ortung_Guete_Geschwindigk 62 "Init" 63 "Fehler" ;
VAL_ 886 GNSS_Ortung_Guete_Ausrichtung 62 "Init" 63 "Fehler" ;
VAL_ 886 GNSS_Ortung_Guete_horizontal 254 "Init" 255 "Fehler" ;
VAL_ 886 GNSS_Ortung_Guete_vertikal 62 "Init" 63 "Fehler" ;
VAL_ 888 GNSS_Ortung_Zeit_in_GPSWoche 1073741822 "Init" 1073741823 "Fehler" ;
VAL_ 888 GNSS_Ortung_Hoehe 4094 "Init" 4095 "Fehler" ;
VAL_ 891 GNSS_UTC_Zeit 0 "Init" ;
VAL_ 891 GNSS_Empfaenger_Status 0 "Backup_Mode" 1 "Live" ;
VAL_ 891 GNSS_GPS_in_Nutzung 0 "unbenutzt" 1 "benutzt" ;
VAL_ 891 GNSS_GLONASS_in_Nutzung 0 "unbenutzt" 1 "benutzt" ;
VAL_ 891 GNSS_Empfangbare_Satelliten 0 "Init" 31 "31_oder_mehr" ;
VAL_ 891 GNSS_Sichtbare_Satelliten 0 "Init" 31 "31_oder_mehr" ;
VAL_ 891 GNSS_Genutzte_Satelliten 0 "Init" 31 "31_oder_mehr" ;
VAL_ 1364 GNSS_Sat_Info_SNR_ID_1 31 "SNR_mehr_als_61_dB" ;
VAL_ 1364 GNSS_Sat_Info_Azimuth_ID_1 511 "Init" ;
VAL_ 1364 GNSS_Sat_Info_Hoehenwinkel_ID_1 127 "Init" ;
VAL_ 299 GRA_Hauptschalter 0 "Hauptschalter_aus__Taster_nicht_betaetigt" 1 "Hauptschalter_ein__Taster_betaetigt" ;
VAL_ 299 GRA_Abbrechen 0 "nicht_betaetigt" 1 "betaetigt" ;
VAL_ 299 GRA_Typ_Hauptschalter 0 "gerasteter_Lenkstockschalter" 1 "getasteter_Lenkstockschalter" ;
VAL_ 299 GRA_Limiter 0 "nicht_betaetigt" 1 "betaetigt" ;
VAL_ 299 GRA_Tip_Setzen 0 "nicht_betaetigt" 1 "betaetigt" ;
VAL_ 299 GRA_Tip_Hoch 0 "nicht_betaetigt" 1 "betaetigt" ;
VAL_ 299 GRA_Tip_Runter 0 "nicht_betaetigt" 1 "betaetigt" ;
VAL_ 299 GRA_Tip_Wiederaufnahme 0 "nicht_betaetigt" 1 "betaetigt" ;
VAL_ 299 GRA_Verstellung_Zeitluecke 0 "Taste_nicht_betaetigt" 1 "Dist_minus_1" 2 "Dist_plus_1" 3 "Dist_Toggle" ;
VAL_ 299 GRA_Codierung 0 "kein_Hebel" 1 "GRA_Hebel" 2 "ACC_Hebel" 3 "Limiter_Only" ;
VAL_ 299 GRA_Fehler 0 "kein_Fehler" 1 "Fehler" ;
VAL_ 299 GRA_LIM_Taste_verfuegbar 0 "Limiter_Taste_nicht_vorhanden" 1 "Limiter_Taste_vorhanden" ;
VAL_ 299 GRA_Tip_Stufe_2 0 "Tip_Stufe_1__keine_Betaetigung" 1 "Tip_Stufe_2" ;
VAL_ 299 GRA_Typ_Bedienteil 0 "Init" 1 "4_Positions_Bedienteil" 2 "6_Positions_Bedienteil" 3 "8_Positions_Bedienteil" 4 "PAG_5_Positions_Bedienteil" 5 "VW_MFL_Gen2" 6 "VW_MFL_Gen3" 7 "PAG_DX1_Bedienteil" ;
VAL_ 299 GRA_TravelAssist 0 "nicht_betaetigt" 1 "betaetigt" ;
VAL_ 310 HAL_Status 0 "Normalbetrieb" 1 "Lenkungsausfall" 2 "Derating_aktiv" 3 "Lenkung_manuell_deaktiviert" ;
VAL_ 310 HAL_VZ_Radwinkel 0 "positiv_Lenkeinschlag_links" 1 "negativ_Lenkeinschlag_rechts" ;
VAL_ 310 HAL_QBit_Radwinkel 0 "gueltiger_Wert" 1 "Ersatz_Init_oder_Fehlerwert" ;
VAL_ 310 HAL_Radwinkel 1020 "Unterspannung" 1021 "nicht_kalibriert" 1022 "Init" 1023 "Fehler" ;
VAL_ 310 HAL_Warnungen 0 "keine_Warnung" 1 "Ausfall_rote_Warnung" 2 "Systemstoerung_gelbe_Warnung" 3 "HAL_deaktiviert" ;
VAL_ 310 HAL_Winkelbegrenzung 0 "nicht_aktiv" 1 "Lenkwinkelbegrenzung_aktiv" ;
VAL_ 310 HAL_VZ_Fahrerwunschwinkel_Soll 0 "positiv" 1 "negativ" ;
VAL_ 310 HAL_Fahrerwunschwinkel_Soll 1022 "Init" 1023 "Fehler" ;
VAL_ 310 HAL_max_Gradient 126 "Init" 127 "Fehler" ;
VAL_ 310 HAL_EFP_FahrPr 0 "keine_Funktion" 1 "Programm_1" 2 "Programm_2" 3 "Programm_3" 4 "Programm_4" 5 "Programm_5" 6 "Programm_6" 7 "Programm_7" 8 "Programm_8" 9 "Programm_9" 10 "Programm_10" 11 "Programm_11" 12 "Programm_12" 13 "Programm_13" 14 "Programm_14" 15 "Programm_15" ;
VAL_ 310 HAL_Status_2 0 "Init" 1 "Fahrbereit" 2 "Symmetriefahrt" 3 "Gelbe_Warnung" 4 "Rote_Warnung" 5 "Hinterachlenkung_deaktiviert" ;
VAL_ 310 HAL_Charisma_Status 0 "Init" 1 "verfuegbar" 2 "nicht_verfuegbar" 3 "asynchron_durch_Fahrerwunsch" ;
VAL_ 310 HAL_Charisma_FahrPr 0 "keine_Funktion" 1 "Programm_1" 2 "Programm_2" 3 "Programm_3" 4 "Programm_4" 5 "Programm_5" 6 "Programm_6" 7 "Programm_7" 8 "Programm_8" 9 "Programm_9" 10 "Programm_10" 11 "Programm_11" 12 "Programm_12" 13 "Programm_13" 14 "Programm_14" 15 "Programm_15" ;
VAL_ 1410 HD_Endstellung_oben 1 "HD in Endstellung oben (offen)" ;
VAL_ 1410 HD_Endstellung_unten 0 "Init" 1 "HD in Endstellung unten (geschlossen)" ;
VAL_ 1410 HD_Bewegung_auf 0 "Init" 1 "HD in Bewegung auf" ;
VAL_ 1410 HD_Bewegung_zu 0 "Init" 1 "HD in Bewegung zu" ;
VAL_ 1410 HD_Innentaster_betaetigt 0 "HD_Innentaster_nicht_betaetigt" 1 "HD_Innentaster_betaetigt" ;
VAL_ 1410 HD_UeKB_erkannt 0 "Init" 1 "Einklemmschutz aktiv" ;
VAL_ 1410 HD_Taster_defekt 0 "Taster_funktionsfähig" 1 "Taster defekt" ;
VAL_ 1410 HD_Rueckmeld_prog 0 "keine Rueckmeldung" 1 "Rueckmeldung zur Programmierung Endstellung aktiv" ;
VAL_ 1410 HD_Verriegelungstaster_betaetigt 0 "Taster_nicht_betaetigt" 1 "Taster_betaetigt" ;
VAL_ 1410 HD_Verr_Taster_betaetigt_inv 0 "Taster_betaetigt" 1 "Taster_nicht_betaetigt" ;
VAL_ 1410 HD_ZZH_Schalter_S3 0 "nicht_betaetigt" 1 "betaetigt" ;
